[part 2 of 3: package /ComponentTypes]
AUTOSAR XML (schema 4-2-2)
package /ComponentTypes  (continued)
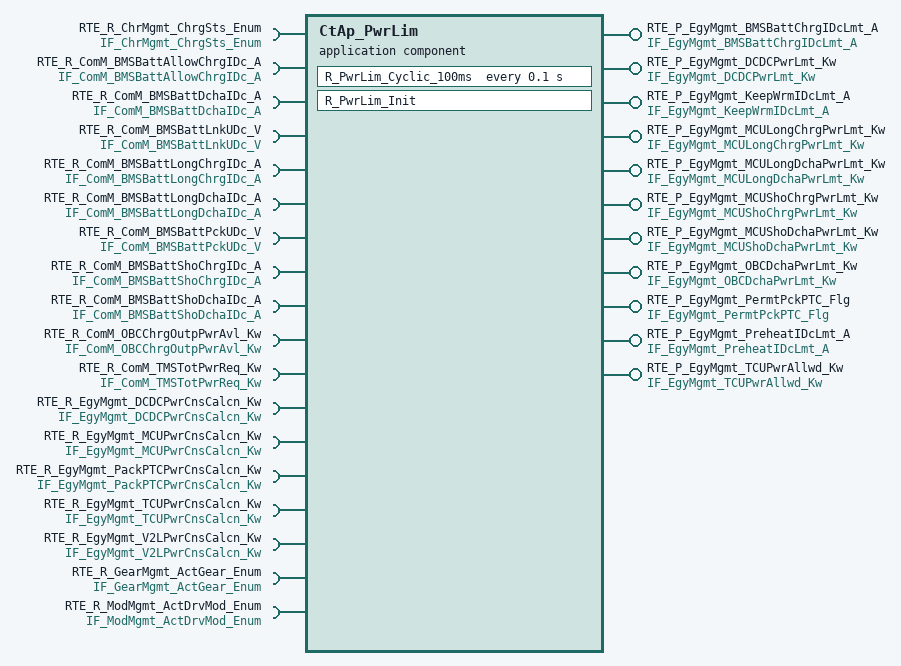
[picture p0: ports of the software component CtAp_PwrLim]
  application sw component type CtAp_PwrLim
    11 x provide port:
      RTE_P_EgyMgmt_BMSBattChrgIDcLmt_A: nonqueued-sender-com-spec{data-element=tec_EgyMgmt_BMSBattChrgIDcLmt_A, init-value=0}, provided-interface=IF_EgyMgmt_BMSBattChrgIDcLmt_A
      RTE_P_EgyMgmt_DCDCPwrLmt_Kw: nonqueued-sender-com-spec{data-element=tec_EgyMgmt_DCDCPwrLmt_Kw, init-value=0}, provided-interface=IF_EgyMgmt_DCDCPwrLmt_Kw
      RTE_P_EgyMgmt_KeepWrmIDcLmt_A: nonqueued-sender-com-spec{data-element=tec_EgyMgmt_KeepWrmIDcLmt_A, init-value=0}, provided-interface=IF_EgyMgmt_KeepWrmIDcLmt_A
      RTE_P_EgyMgmt_MCULongChrgPwrLmt_Kw: nonqueued-sender-com-spec{data-element=tec_EgyMgmt_MCULongChrgPwrLmt_Kw, init-value=0}, provided-interface=IF_EgyMgmt_MCULongChrgPwrLmt_Kw
      RTE_P_EgyMgmt_MCULongDchaPwrLmt_Kw: nonqueued-sender-com-spec{data-element=tec_EgyMgmt_MCULongDchaPwrLmt_Kw, init-value=0}, provided-interface=IF_EgyMgmt_MCULongDchaPwrLmt_Kw
      RTE_P_EgyMgmt_MCUShoChrgPwrLmt_Kw: nonqueued-sender-com-spec{data-element=tec_EgyMgmt_MCUShoChrgPwrLmt_Kw, init-value=0}, provided-interface=IF_EgyMgmt_MCUShoChrgPwrLmt_Kw
      RTE_P_EgyMgmt_MCUShoDchaPwrLmt_Kw: nonqueued-sender-com-spec{data-element=tec_EgyMgmt_MCUShoDchaPwrLmt_Kw, init-value=0}, provided-interface=IF_EgyMgmt_MCUShoDchaPwrLmt_Kw
      RTE_P_EgyMgmt_OBCDchaPwrLmt_Kw: nonqueued-sender-com-spec{data-element=tec_EgyMgmt_OBCDchaPwrLmt_Kw, init-value=0}, provided-interface=IF_EgyMgmt_OBCDchaPwrLmt_Kw
      RTE_P_EgyMgmt_PermtPckPTC_Flg: nonqueued-sender-com-spec{data-element=tec_EgyMgmt_PermtPckPTC_Flg, init-value=0}, provided-interface=IF_EgyMgmt_PermtPckPTC_Flg
      RTE_P_EgyMgmt_PreheatIDcLmt_A: nonqueued-sender-com-spec{data-element=tec_EgyMgmt_PreheatIDcLmt_A, init-value=0}, provided-interface=IF_EgyMgmt_PreheatIDcLmt_A
      RTE_P_EgyMgmt_TCUPwrAllwd_Kw: nonqueued-sender-com-spec{data-element=tec_EgyMgmt_TCUPwrAllwd_Kw, init-value=0}, provided-interface=IF_EgyMgmt_TCUPwrAllwd_Kw
    18 x require port:
      RTE_R_ChrMgmt_ChrgSts_Enum: nonqueued-receiver-com-spec{data-element=tec_ChrMgmt_ChrgSts_Enum, filter=data-filter-type=ALWAYS, init-value=0}, required-interface=IF_ChrMgmt_ChrgSts_Enum
      RTE_R_ComM_BMSBattAllowChrgIDc_A: nonqueued-receiver-com-spec{data-element=tec_ComM_BMSBattAllowChrgIDc_A, filter=data-filter-type=ALWAYS, init-value=0}, required-interface=IF_ComM_BMSBattAllowChrgIDc_A
      RTE_R_ComM_BMSBattDchaIDc_A: nonqueued-receiver-com-spec{data-element=tec_ComM_BMSBattDchaIDc_A, filter=data-filter-type=ALWAYS, init-value=0}, required-interface=IF_ComM_BMSBattDchaIDc_A
      RTE_R_ComM_BMSBattLnkUDc_V: nonqueued-receiver-com-spec{data-element=tec_ComM_BMSBattLnkUDc_V, filter=data-filter-type=ALWAYS, init-value=0}, required-interface=IF_ComM_BMSBattLnkUDc_V
      RTE_R_ComM_BMSBattLongChrgIDc_A: nonqueued-receiver-com-spec{data-element=tec_ComM_BMSBattLongChrgIDc_A, filter=data-filter-type=ALWAYS, init-value=0}, required-interface=IF_ComM_BMSBattLongChrgIDc_A
      RTE_R_ComM_BMSBattLongDchaIDc_A: nonqueued-receiver-com-spec{data-element=tec_ComM_BMSBattLongDchaIDc_A, filter=data-filter-type=ALWAYS, init-value=0}, required-interface=IF_ComM_BMSBattLongDchaIDc_A
      RTE_R_ComM_BMSBattPckUDc_V: nonqueued-receiver-com-spec{data-element=tec_ComM_BMSBattPckUDc_V, filter=data-filter-type=ALWAYS, init-value=0}, required-interface=IF_ComM_BMSBattPckUDc_V
      RTE_R_ComM_BMSBattShoChrgIDc_A: nonqueued-receiver-com-spec{data-element=tec_ComM_BMSBattShoChrgIDc_A, filter=data-filter-type=ALWAYS, init-value=0}, required-interface=IF_ComM_BMSBattShoChrgIDc_A
      RTE_R_ComM_BMSBattShoDchaIDc_A: nonqueued-receiver-com-spec{data-element=tec_ComM_BMSBattShoDchaIDc_A, filter=data-filter-type=ALWAYS, init-value=0}, required-interface=IF_ComM_BMSBattShoDchaIDc_A
      RTE_R_ComM_OBCChrgOutpPwrAvl_Kw: nonqueued-receiver-com-spec{data-element=tec_ComM_OBCChrgOutpPwrAvl_Kw, filter=data-filter-type=ALWAYS, init-value=0}, required-interface=IF_ComM_OBCChrgOutpPwrAvl_Kw
      RTE_R_ComM_TMSTotPwrReq_Kw: nonqueued-receiver-com-spec{data-element=tec_ComM_TMSTotPwrReq_Kw, filter=data-filter-type=ALWAYS, init-value=0}, required-interface=IF_ComM_TMSTotPwrReq_Kw
      RTE_R_EgyMgmt_DCDCPwrCnsCalcn_Kw: nonqueued-receiver-com-spec{data-element=tec_EgyMgmt_DCDCPwrCnsCalcn_Kw, filter=data-filter-type=ALWAYS, init-value=0}, required-interface=IF_EgyMgmt_DCDCPwrCnsCalcn_Kw
      RTE_R_EgyMgmt_MCUPwrCnsCalcn_Kw: nonqueued-receiver-com-spec{data-element=tec_EgyMgmt_MCUPwrCnsCalcn_Kw, filter=data-filter-type=ALWAYS, init-value=0}, required-interface=IF_EgyMgmt_MCUPwrCnsCalcn_Kw
      RTE_R_EgyMgmt_PackPTCPwrCnsCalcn_Kw: nonqueued-receiver-com-spec{data-element=tec_EgyMgmt_PackPTCPwrCnsCalcn_Kw, filter=data-filter-type=ALWAYS, init-value=0}, required-interface=IF_EgyMgmt_PackPTCPwrCnsCalcn_Kw
      RTE_R_EgyMgmt_TCUPwrCnsCalcn_Kw: nonqueued-receiver-com-spec{data-element=tec_EgyMgmt_TCUPwrCnsCalcn_Kw, filter=data-filter-type=ALWAYS, init-value=0}, required-interface=IF_EgyMgmt_TCUPwrCnsCalcn_Kw
      RTE_R_EgyMgmt_V2LPwrCnsCalcn_Kw: nonqueued-receiver-com-spec{data-element=IF_EgyMgmt_V2LPwrCnsCalcn_Kw, filter=data-filter-type=ALWAYS, init-value=0}, required-interface=IF_EgyMgmt_V2LPwrCnsCalcn_Kw
      RTE_R_GearMgmt_ActGear_Enum: nonqueued-receiver-com-spec{data-element=tec_GearMgmt_ActGear_Enum, filter=data-filter-type=ALWAYS, init-value=0}, required-interface=IF_GearMgmt_ActGear_Enum
      RTE_R_ModMgmt_ActDrvMod_Enum: nonqueued-receiver-com-spec{data-element=tec_ModMgmt_ActDrvMod_Enum, filter=data-filter-type=ALWAYS, init-value=0}, required-interface=IF_ModMgmt_ActDrvMod_Enum
    behavior CtAp_PwrLim_InternalBehavior
      timing event TMT_R_PwrLim_Cyclic_100ms: start-on-event=R_PwrLim_Cyclic_100ms, period=0.1
      init event CtAp_PwrLim_InitEvent: start-on-event=CtAp_PwrLim_InternalBehavior/R_PwrLim_Init
      runnable R_PwrLim_Cyclic_100ms
        data-receive-point-by-arguments:
          18 x access:
            REC_RTE_R_ChrMgmt_ChrgSts_Enum_tec_ChrMgmt_ChrgSts_Enum: accessed-variable=RTE_R_ChrMgmt_ChrgSts_Enum.tec_ChrMgmt_ChrgSts_Enum
            REC_RTE_R_ComM_BMSBattAllowChrgIDc_A_tec_ComM_BMSBattAllowChrgIDc_A: accessed-variable=RTE_R_ComM_BMSBattAllowChrgIDc_A.tec_ComM_BMSBattAllowChrgIDc_A
            REC_RTE_R_ComM_BMSBattDchaIDc_A_tec_ComM_BMSBattDchaIDc_A: accessed-variable=RTE_R_ComM_BMSBattDchaIDc_A.tec_ComM_BMSBattDchaIDc_A
            REC_RTE_R_ComM_BMSBattLnkUDc_V_tec_ComM_BMSBattLnkUDc_V: accessed-variable=RTE_R_ComM_BMSBattLnkUDc_V.tec_ComM_BMSBattLnkUDc_V
            REC_RTE_R_ComM_BMSBattLongChrgIDc_A_tec_ComM_BMSBattLongChrgIDc_A: accessed-variable=RTE_R_ComM_BMSBattLongChrgIDc_A.tec_ComM_BMSBattLongChrgIDc_A
            REC_RTE_R_ComM_BMSBattLongDchaIDc_A_tec_ComM_BMSBattLongDchaIDc_A: accessed-variable=RTE_R_ComM_BMSBattLongDchaIDc_A.tec_ComM_BMSBattLongDchaIDc_A
            REC_RTE_R_ComM_BMSBattPckUDc_V_tec_ComM_BMSBattPckUDc_V: accessed-variable=RTE_R_ComM_BMSBattPckUDc_V.tec_ComM_BMSBattPckUDc_V
            REC_RTE_R_ComM_BMSBattShoChrgIDc_A_tec_ComM_BMSBattShoChrgIDc_A: accessed-variable=RTE_R_ComM_BMSBattShoChrgIDc_A.tec_ComM_BMSBattShoChrgIDc_A
            REC_RTE_R_ComM_BMSBattShoDchaIDc_A_tec_ComM_BMSBattShoDchaIDc_A: accessed-variable=RTE_R_ComM_BMSBattShoDchaIDc_A.tec_ComM_BMSBattShoDchaIDc_A
            REC_RTE_R_ComM_OBCChrgOutpPwrAvl_Kw_tec_ComM_OBCChrgOutpPwrAvl_Kw: accessed-variable=RTE_R_ComM_OBCChrgOutpPwrAvl_Kw.tec_ComM_OBCChrgOutpPwrAvl_Kw
            REC_RTE_R_ComM_TMSTotPwrReq_Kw_tec_ComM_TMSTotPwrReq_Kw: accessed-variable=RTE_R_ComM_TMSTotPwrReq_Kw.tec_ComM_TMSTotPwrReq_Kw
            REC_RTE_R_EgyMgmt_DCDCPwrCnsCalcn_Kw_tec_EgyMgmt_DCDCPwrCnsCalcn_Kw: accessed-variable=RTE_R_EgyMgmt_DCDCPwrCnsCalcn_Kw.tec_EgyMgmt_DCDCPwrCnsCalcn_Kw
            REC_RTE_R_EgyMgmt_MCUPwrCnsCalcn_Kw_tec_EgyMgmt_MCUPwrCnsCalcn_Kw: accessed-variable=RTE_R_EgyMgmt_MCUPwrCnsCalcn_Kw.tec_EgyMgmt_MCUPwrCnsCalcn_Kw
            REC_RTE_R_EgyMgmt_PackPTCPwrCnsCalcn_Kw_tec_EgyMgmt_PackPTCPwrCnsCalcn_Kw: accessed-variable=RTE_R_EgyMgmt_PackPTCPwrCnsCalcn_Kw.tec_EgyMgmt_PackPTCPwrCnsCalcn_Kw
            REC_RTE_R_EgyMgmt_TCUPwrCnsCalcn_Kw_tec_EgyMgmt_TCUPwrCnsCalcn_Kw: accessed-variable=RTE_R_EgyMgmt_TCUPwrCnsCalcn_Kw.tec_EgyMgmt_TCUPwrCnsCalcn_Kw
            REC_RTE_R_EgyMgmt_V2LPwrCnsCalcn_Kw_IF_EgyMgmt_V2LPwrCnsCalcn_Kw: accessed-variable=RTE_R_EgyMgmt_V2LPwrCnsCalcn_Kw.IF_EgyMgmt_V2LPwrCnsCalcn_Kw
            REC_RTE_R_GearMgmt_ActGear_Enum_tec_GearMgmt_ActGear_Enum: accessed-variable=RTE_R_GearMgmt_ActGear_Enum.tec_GearMgmt_ActGear_Enum
            REC_RTE_R_ModMgmt_ActDrvMod_Enum_tec_ModMgmt_ActDrvMod_Enum: accessed-variable=RTE_R_ModMgmt_ActDrvMod_Enum.tec_ModMgmt_ActDrvMod_Enum
        data-send-points:
          11 x access:
            SEND_RTE_P_EgyMgmt_BMSBattChrgIDcLmt_A_tec_EgyMgmt_BMSBattChrgIDcLmt_A: accessed-variable=RTE_P_EgyMgmt_BMSBattChrgIDcLmt_A.tec_EgyMgmt_BMSBattChrgIDcLmt_A
            SEND_RTE_P_EgyMgmt_DCDCPwrLmt_Kw_tec_EgyMgmt_DCDCPwrLmt_Kw: accessed-variable=RTE_P_EgyMgmt_DCDCPwrLmt_Kw.tec_EgyMgmt_DCDCPwrLmt_Kw
            SEND_RTE_P_EgyMgmt_KeepWrmIDcLmt_A_tec_EgyMgmt_KeepWrmIDcLmt_A: accessed-variable=RTE_P_EgyMgmt_KeepWrmIDcLmt_A.tec_EgyMgmt_KeepWrmIDcLmt_A
            SEND_RTE_P_EgyMgmt_MCULongChrgPwrLmt_Kw_tec_EgyMgmt_MCULongChrgPwrLmt_Kw: accessed-variable=RTE_P_EgyMgmt_MCULongChrgPwrLmt_Kw.tec_EgyMgmt_MCULongChrgPwrLmt_Kw
            SEND_RTE_P_EgyMgmt_MCULongDchaPwrLmt_Kw_tec_EgyMgmt_MCULongDchaPwrLmt_Kw: accessed-variable=RTE_P_EgyMgmt_MCULongDchaPwrLmt_Kw.tec_EgyMgmt_MCULongDchaPwrLmt_Kw
            SEND_RTE_P_EgyMgmt_MCUShoChrgPwrLmt_Kw_tec_EgyMgmt_MCUShoChrgPwrLmt_Kw: accessed-variable=RTE_P_EgyMgmt_MCUShoChrgPwrLmt_Kw.tec_EgyMgmt_MCUShoChrgPwrLmt_Kw
            SEND_RTE_P_EgyMgmt_MCUShoDchaPwrLmt_Kw_tec_EgyMgmt_MCUShoDchaPwrLmt_Kw: accessed-variable=RTE_P_EgyMgmt_MCUShoDchaPwrLmt_Kw.tec_EgyMgmt_MCUShoDchaPwrLmt_Kw
            SEND_RTE_P_EgyMgmt_OBCDchaPwrLmt_Kw_tec_EgyMgmt_OBCDchaPwrLmt_Kw: accessed-variable=RTE_P_EgyMgmt_OBCDchaPwrLmt_Kw.tec_EgyMgmt_OBCDchaPwrLmt_Kw
            SEND_RTE_P_EgyMgmt_PermtPckPTC_Flg_tec_EgyMgmt_PermtPckPTC_Flg: accessed-variable=RTE_P_EgyMgmt_PermtPckPTC_Flg.tec_EgyMgmt_PermtPckPTC_Flg
            SEND_RTE_P_EgyMgmt_PreheatIDcLmt_A_tec_EgyMgmt_PreheatIDcLmt_A: accessed-variable=RTE_P_EgyMgmt_PreheatIDcLmt_A.tec_EgyMgmt_PreheatIDcLmt_A
            SEND_RTE_P_EgyMgmt_TCUPwrAllwd_Kw_tec_EgyMgmt_TCUPwrAllwd_Kw: accessed-variable=RTE_P_EgyMgmt_TCUPwrAllwd_Kw.tec_EgyMgmt_TCUPwrAllwd_Kw
      runnable R_PwrLim_Init
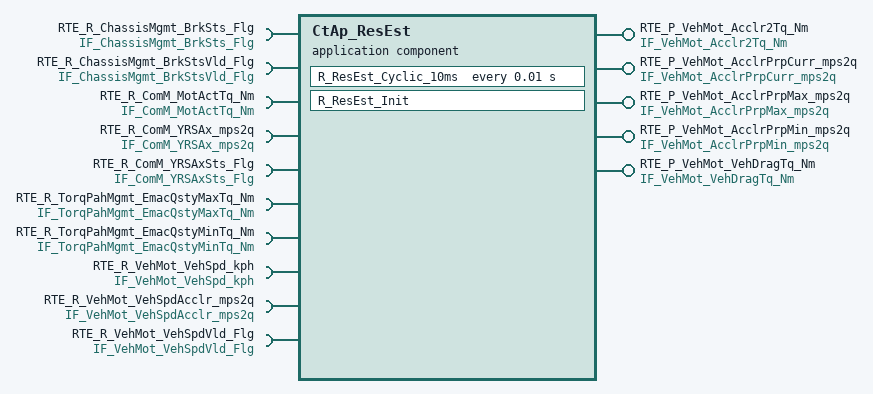
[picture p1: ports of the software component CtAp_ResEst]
  application sw component type CtAp_ResEst
    5 x provide port:
      RTE_P_VehMot_Acclr2Tq_Nm: nonqueued-sender-com-spec{data-element=tec_VehMot_Acclr2Tq_Nm, init-value=0}, provided-interface=IF_VehMot_Acclr2Tq_Nm
      RTE_P_VehMot_AcclrPrpCurr_mps2q: nonqueued-sender-com-spec{data-element=tec_VehMot_AcclrPrpCurr_mps2q, init-value=0}, provided-interface=IF_VehMot_AcclrPrpCurr_mps2q
      RTE_P_VehMot_AcclrPrpMax_mps2q: nonqueued-sender-com-spec{data-element=tec_VehMot_AcclrPrpMax_mps2q, init-value=0}, provided-interface=IF_VehMot_AcclrPrpMax_mps2q
      RTE_P_VehMot_AcclrPrpMin_mps2q: nonqueued-sender-com-spec{data-element=tec_VehMot_AcclrPrpMin_mps2q, init-value=0}, provided-interface=IF_VehMot_AcclrPrpMin_mps2q
      RTE_P_VehMot_VehDragTq_Nm: nonqueued-sender-com-spec{data-element=tec_VehMot_VehDragTq_Nm, init-value=0}, provided-interface=IF_VehMot_VehDragTq_Nm
    10 x require port:
      RTE_R_ChassisMgmt_BrkSts_Flg: nonqueued-receiver-com-spec{data-element=tec_ChassisMgmt_BrkSts_Flg, filter=data-filter-type=ALWAYS, init-value=0}, required-interface=IF_ChassisMgmt_BrkSts_Flg
      RTE_R_ChassisMgmt_BrkStsVld_Flg: nonqueued-receiver-com-spec{data-element=tec_ChassisMgmt_BrkStsVld_Flg, filter=data-filter-type=ALWAYS, init-value=0}, required-interface=IF_ChassisMgmt_BrkStsVld_Flg
      RTE_R_ComM_MotActTq_Nm: nonqueued-receiver-com-spec{data-element=tec_ComM_MotActTq_Nm, filter=data-filter-type=ALWAYS, init-value=0}, required-interface=IF_ComM_MotActTq_Nm
      RTE_R_ComM_YRSAx_mps2q: nonqueued-receiver-com-spec{data-element=tec_ComM_YRSAx_mps2q, filter=data-filter-type=ALWAYS, init-value=0}, required-interface=IF_ComM_YRSAx_mps2q
      RTE_R_ComM_YRSAxSts_Flg: nonqueued-receiver-com-spec{data-element=tec_ComM_YRSAxSts_Flg, filter=data-filter-type=ALWAYS, init-value=0}, required-interface=IF_ComM_YRSAxSts_Flg
      RTE_R_TorqPahMgmt_EmacQstyMaxTq_Nm: nonqueued-receiver-com-spec{data-element=tec_TorqPahMgmt_EmacQstyMaxTq_Nm, filter=data-filter-type=ALWAYS, init-value=0}, required-interface=IF_TorqPahMgmt_EmacQstyMaxTq_Nm
      RTE_R_TorqPahMgmt_EmacQstyMinTq_Nm: nonqueued-receiver-com-spec{data-element=tec_TorqPahMgmt_EmacQstyMinTq_Nm, filter=data-filter-type=ALWAYS, init-value=0}, required-interface=IF_TorqPahMgmt_EmacQstyMinTq_Nm
      RTE_R_VehMot_VehSpd_kph: nonqueued-receiver-com-spec{data-element=tec_VehMot_VehSpd_kph, filter=data-filter-type=ALWAYS, init-value=0}, required-interface=IF_VehMot_VehSpd_kph
      RTE_R_VehMot_VehSpdAcclr_mps2q: nonqueued-receiver-com-spec{data-element=tec_VehMot_VehSpdAcclr_mps2q, filter=data-filter-type=ALWAYS, init-value=0}, required-interface=IF_VehMot_VehSpdAcclr_mps2q
      RTE_R_VehMot_VehSpdVld_Flg: nonqueued-receiver-com-spec{data-element=tec_VehMot_VehSpdVld_Flg, filter=data-filter-type=ALWAYS, init-value=0}, required-interface=IF_VehMot_VehSpdVld_Flg
    behavior CtAp_ResEst_InternalBehavior
      timing event TMT_R_ResEst_Cyclic_10ms: start-on-event=R_ResEst_Cyclic_10ms, period=0.01
      init event CtAp_ResEst_InitEvent: start-on-event=R_ResEst_Init
      runnable R_ResEst_Cyclic_10ms
        data-receive-point-by-arguments:
          10 x access:
            REC_RTE_R_ChassisMgmt_BrkSts_Flg_tec_ChassisMgmt_BrkSts_Flg: accessed-variable=RTE_R_ChassisMgmt_BrkSts_Flg.tec_ChassisMgmt_BrkSts_Flg
            REC_RTE_R_ChassisMgmt_BrkStsVld_Flg_tec_ChassisMgmt_BrkStsVld_Flg: accessed-variable=RTE_R_ChassisMgmt_BrkStsVld_Flg.tec_ChassisMgmt_BrkStsVld_Flg
            REC_RTE_R_ComM_MotActTq_Nm_tec_ComM_MotActTq_Nm: accessed-variable=RTE_R_ComM_MotActTq_Nm.tec_ComM_MotActTq_Nm
            REC_RTE_R_ComM_YRSAx_mps2q_tec_ComM_YRSAx_mps2q: accessed-variable=RTE_R_ComM_YRSAx_mps2q.tec_ComM_YRSAx_mps2q
            REC_RTE_R_ComM_YRSAxSts_Flg_tec_ComM_YRSAxSts_Flg: accessed-variable=RTE_R_ComM_YRSAxSts_Flg.tec_ComM_YRSAxSts_Flg
            REC_RTE_R_TorqPahMgmt_EmacQstyMaxTq_Nm_tec_TorqPahMgmt_EmacQstyMaxTq_Nm: accessed-variable=RTE_R_TorqPahMgmt_EmacQstyMaxTq_Nm.tec_TorqPahMgmt_EmacQstyMaxTq_Nm
            REC_RTE_R_TorqPahMgmt_EmacQstyMinTq_Nm_tec_TorqPahMgmt_EmacQstyMinTq_Nm: accessed-variable=RTE_R_TorqPahMgmt_EmacQstyMinTq_Nm.tec_TorqPahMgmt_EmacQstyMinTq_Nm
            REC_RTE_R_VehMot_VehSpd_kph_tec_VehMot_VehSpd_kph: accessed-variable=RTE_R_VehMot_VehSpd_kph.tec_VehMot_VehSpd_kph
            REC_RTE_R_VehMot_VehSpdAcclr_mps2q_tec_VehMot_VehSpdAcclr_mps2q: accessed-variable=RTE_R_VehMot_VehSpdAcclr_mps2q.tec_VehMot_VehSpdAcclr_mps2q
            REC_RTE_R_VehMot_VehSpdVld_Flg_tec_VehMot_VehSpdVld_Flg: accessed-variable=RTE_R_VehMot_VehSpdVld_Flg.tec_VehMot_VehSpdVld_Flg
        data-send-points:
          5 x access:
            SEND_RTE_P_VehMot_Acclr2Tq_Nm_tec_VehMot_Acclr2Tq_Nm: accessed-variable=RTE_P_VehMot_Acclr2Tq_Nm.tec_VehMot_Acclr2Tq_Nm
            SEND_RTE_P_VehMot_AcclrPrpCurr_mps2q_tec_VehMot_AcclrPrpCurr_mps2q: accessed-variable=RTE_P_VehMot_AcclrPrpCurr_mps2q.tec_VehMot_AcclrPrpCurr_mps2q
            SEND_RTE_P_VehMot_AcclrPrpMax_mps2q_tec_VehMot_AcclrPrpMax_mps2q: accessed-variable=RTE_P_VehMot_AcclrPrpMax_mps2q.tec_VehMot_AcclrPrpMax_mps2q
            SEND_RTE_P_VehMot_AcclrPrpMin_mps2q_tec_VehMot_AcclrPrpMin_mps2q: accessed-variable=RTE_P_VehMot_AcclrPrpMin_mps2q.tec_VehMot_AcclrPrpMin_mps2q
            SEND_RTE_P_VehMot_VehDragTq_Nm_tec_VehMot_VehDragTq_Nm: accessed-variable=RTE_P_VehMot_VehDragTq_Nm.tec_VehMot_VehDragTq_Nm
      runnable R_ResEst_Init
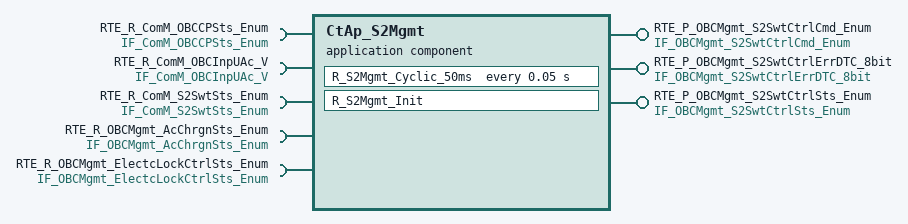
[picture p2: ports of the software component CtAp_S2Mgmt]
  application sw component type CtAp_S2Mgmt
    provide port RTE_P_OBCMgmt_S2SwtCtrlCmd_Enum: nonqueued-sender-com-spec{data-element=tec_OBCMgmt_S2SwtCtrlCmd_Enum, init-value=0}, provided-interface=IF_OBCMgmt_S2SwtCtrlCmd_Enum
    provide port RTE_P_OBCMgmt_S2SwtCtrlErrDTC_8bit: nonqueued-sender-com-spec{data-element=tec_OBCMgmt_S2SwtCtrlErrDTC_8bit, init-value=0}, provided-interface=IF_OBCMgmt_S2SwtCtrlErrDTC_8bit
    provide port RTE_P_OBCMgmt_S2SwtCtrlSts_Enum: nonqueued-sender-com-spec{data-element=tec_OBCMgmt_S2SwtCtrlSts_Enum, init-value=0}, provided-interface=IF_OBCMgmt_S2SwtCtrlSts_Enum
    5 x require port:
      RTE_R_ComM_OBCCPSts_Enum: nonqueued-receiver-com-spec{data-element=tec_ComM_OBCCPSts_Enum, filter=data-filter-type=ALWAYS, init-value=0}, required-interface=IF_ComM_OBCCPSts_Enum
      RTE_R_ComM_OBCInpUAc_V: nonqueued-receiver-com-spec{data-element=tec_ComM_OBCInpUAc_V, filter=data-filter-type=ALWAYS, init-value=0}, required-interface=IF_ComM_OBCInpUAc_V
      RTE_R_ComM_S2SwtSts_Enum: nonqueued-receiver-com-spec{data-element=tec_ComM_S2SwtSts_Enum, filter=data-filter-type=ALWAYS, init-value=0}, required-interface=IF_ComM_S2SwtSts_Enum
      RTE_R_OBCMgmt_AcChrgnSts_Enum: nonqueued-receiver-com-spec{data-element=tec_OBCMgmt_AcChrgnSts_Enum, filter=data-filter-type=ALWAYS, init-value=0}, required-interface=IF_OBCMgmt_AcChrgnSts_Enum
      RTE_R_OBCMgmt_ElectcLockCtrlSts_Enum: nonqueued-receiver-com-spec{data-element=tec_OBCMgmt_ElectcLockCtrlSts_Enum, filter=data-filter-type=ALWAYS, init-value=0}, required-interface=IF_OBCMgmt_ElectcLockCtrlSts_Enum
    behavior CtAp_S2Mgmt_InternalBehavior
      timing event TMT_R_S2Mgmt_Cyclic_50ms: start-on-event=R_S2Mgmt_Cyclic_50ms, period=0.05
      init event CtAp_S2Mgmt_InitEvent: start-on-event=R_S2Mgmt_Init
      runnable R_S2Mgmt_Cyclic_50ms
        data-receive-point-by-arguments:
          5 x access:
            REC_RTE_R_ComM_OBCCPSts_Enum_tec_ComM_OBCCPSts_Enum: accessed-variable=RTE_R_ComM_OBCCPSts_Enum.tec_ComM_OBCCPSts_Enum
            REC_RTE_R_ComM_OBCInpUAc_V_tec_ComM_OBCInpUAc_V: accessed-variable=RTE_R_ComM_OBCInpUAc_V.tec_ComM_OBCInpUAc_V
            REC_RTE_R_ComM_S2SwtSts_Enum_tec_ComM_S2SwtSts_Enum: accessed-variable=RTE_R_ComM_S2SwtSts_Enum.tec_ComM_S2SwtSts_Enum
            REC_RTE_R_OBCMgmt_AcChrgnSts_Enum_tec_OBCMgmt_AcChrgnSts_Enum: accessed-variable=RTE_R_OBCMgmt_AcChrgnSts_Enum.tec_OBCMgmt_AcChrgnSts_Enum
            REC_RTE_R_OBCMgmt_ElectcLockCtrlSts_Enum_tec_OBCMgmt_ElectcLockCtrlSts_Enum: accessed-variable=RTE_R_OBCMgmt_ElectcLockCtrlSts_Enum.tec_OBCMgmt_ElectcLockCtrlSts_Enum
        data-send-points:
          access SEND_RTE_P_OBCMgmt_S2SwtCtrlCmd_Enum_tec_OBCMgmt_S2SwtCtrlCmd_Enum: accessed-variable=RTE_P_OBCMgmt_S2SwtCtrlCmd_Enum.tec_OBCMgmt_S2SwtCtrlCmd_Enum
          access SEND_RTE_P_OBCMgmt_S2SwtCtrlErrDTC_8bit_tec_OBCMgmt_S2SwtCtrlErrDTC_8bit: accessed-variable=RTE_P_OBCMgmt_S2SwtCtrlErrDTC_8bit.tec_OBCMgmt_S2SwtCtrlErrDTC_8bit
          access SEND_RTE_P_OBCMgmt_S2SwtCtrlSts_Enum_tec_OBCMgmt_S2SwtCtrlSts_Enum: accessed-variable=RTE_P_OBCMgmt_S2SwtCtrlSts_Enum.tec_OBCMgmt_S2SwtCtrlSts_Enum
      runnable R_S2Mgmt_Init
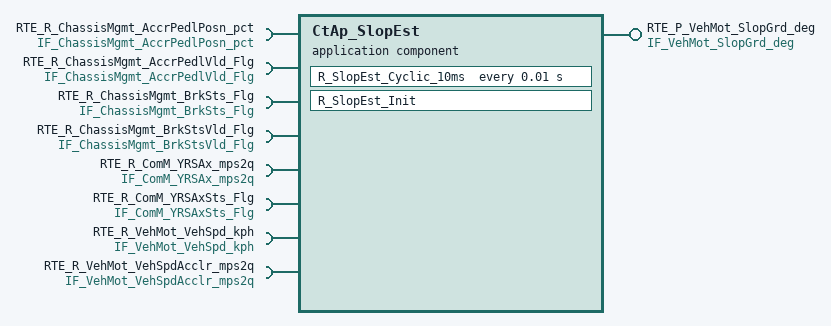
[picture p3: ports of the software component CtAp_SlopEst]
  application sw component type CtAp_SlopEst
    provide port RTE_P_VehMot_SlopGrd_deg: nonqueued-sender-com-spec{data-element=tec_VehMot_SlopGrd_deg, init-value=0}, provided-interface=IF_VehMot_SlopGrd_deg
    8 x require port:
      RTE_R_ChassisMgmt_AccrPedlPosn_pct: nonqueued-receiver-com-spec{data-element=tec_ChassisMgmt_AccrPedlPosn_pct, filter=data-filter-type=ALWAYS, init-value=0}, required-interface=IF_ChassisMgmt_AccrPedlPosn_pct
      RTE_R_ChassisMgmt_AccrPedlVld_Flg: nonqueued-receiver-com-spec{data-element=tec_ChassisMgmt_AccrPedlVld_Flg, filter=data-filter-type=ALWAYS, init-value=0}, required-interface=IF_ChassisMgmt_AccrPedlVld_Flg
      RTE_R_ChassisMgmt_BrkSts_Flg: nonqueued-receiver-com-spec{data-element=tec_ChassisMgmt_BrkSts_Flg, filter=data-filter-type=ALWAYS, init-value=0}, required-interface=IF_ChassisMgmt_BrkSts_Flg
      RTE_R_ChassisMgmt_BrkStsVld_Flg: nonqueued-receiver-com-spec{data-element=tec_ChassisMgmt_BrkStsVld_Flg, filter=data-filter-type=ALWAYS, init-value=0}, required-interface=IF_ChassisMgmt_BrkStsVld_Flg
      RTE_R_ComM_YRSAx_mps2q: nonqueued-receiver-com-spec{data-element=tec_ComM_YRSAx_mps2q, filter=data-filter-type=ALWAYS, init-value=0}, required-interface=IF_ComM_YRSAx_mps2q
      RTE_R_ComM_YRSAxSts_Flg: nonqueued-receiver-com-spec{data-element=tec_ComM_YRSAxSts_Flg, filter=data-filter-type=ALWAYS, init-value=0}, required-interface=IF_ComM_YRSAxSts_Flg
      RTE_R_VehMot_VehSpd_kph: nonqueued-receiver-com-spec{data-element=tec_VehMot_VehSpd_kph, filter=data-filter-type=ALWAYS, init-value=0}, required-interface=IF_VehMot_VehSpd_kph
      RTE_R_VehMot_VehSpdAcclr_mps2q: nonqueued-receiver-com-spec{data-element=tec_VehMot_VehSpdAcclr_mps2q, filter=data-filter-type=ALWAYS, init-value=0}, required-interface=IF_VehMot_VehSpdAcclr_mps2q
    behavior CtAp_SlopEst_InternalBehavior
      timing event TMT_R_SlopEst_Cyclic_10ms: start-on-event=R_SlopEst_Cyclic_10ms, period=0.01
      init event CtAp_SlopEst_InitEvent: start-on-event=R_SlopEst_Init
      runnable R_SlopEst_Cyclic_10ms
        data-receive-point-by-arguments:
          8 x access:
            REC_RTE_R_ChassisMgmt_AccrPedlPosn_pct_tec_ChassisMgmt_AccrPedlPosn_pct: accessed-variable=RTE_R_ChassisMgmt_AccrPedlPosn_pct.tec_ChassisMgmt_AccrPedlPosn_pct
            REC_RTE_R_ChassisMgmt_AccrPedlVld_Flg_tec_ChassisMgmt_AccrPedlVld_Flg: accessed-variable=RTE_R_ChassisMgmt_AccrPedlVld_Flg.tec_ChassisMgmt_AccrPedlVld_Flg
            REC_RTE_R_ChassisMgmt_BrkSts_Flg_tec_ChassisMgmt_BrkSts_Flg: accessed-variable=RTE_R_ChassisMgmt_BrkSts_Flg.tec_ChassisMgmt_BrkSts_Flg
            REC_RTE_R_ChassisMgmt_BrkStsVld_Flg_tec_ChassisMgmt_BrkStsVld_Flg: accessed-variable=RTE_R_ChassisMgmt_BrkStsVld_Flg.tec_ChassisMgmt_BrkStsVld_Flg
            REC_RTE_R_ComM_YRSAx_mps2q_tec_ComM_YRSAx_mps2q: accessed-variable=RTE_R_ComM_YRSAx_mps2q.tec_ComM_YRSAx_mps2q
            REC_RTE_R_ComM_YRSAxSts_Flg_tec_ComM_YRSAxSts_Flg: accessed-variable=RTE_R_ComM_YRSAxSts_Flg.tec_ComM_YRSAxSts_Flg
            REC_RTE_R_VehMot_VehSpd_kph_tec_VehMot_VehSpd_kph: accessed-variable=RTE_R_VehMot_VehSpd_kph.tec_VehMot_VehSpd_kph
            REC_RTE_R_VehMot_VehSpdAcclr_mps2q_tec_VehMot_VehSpdAcclr_mps2q: accessed-variable=RTE_R_VehMot_VehSpdAcclr_mps2q.tec_VehMot_VehSpdAcclr_mps2q
        data-send-points:
          access SEND_RTE_P_VehMot_SlopGrd_deg_tec_VehMot_SlopGrd_deg: accessed-variable=RTE_P_VehMot_SlopGrd_deg.tec_VehMot_SlopGrd_deg
      runnable R_SlopEst_Init
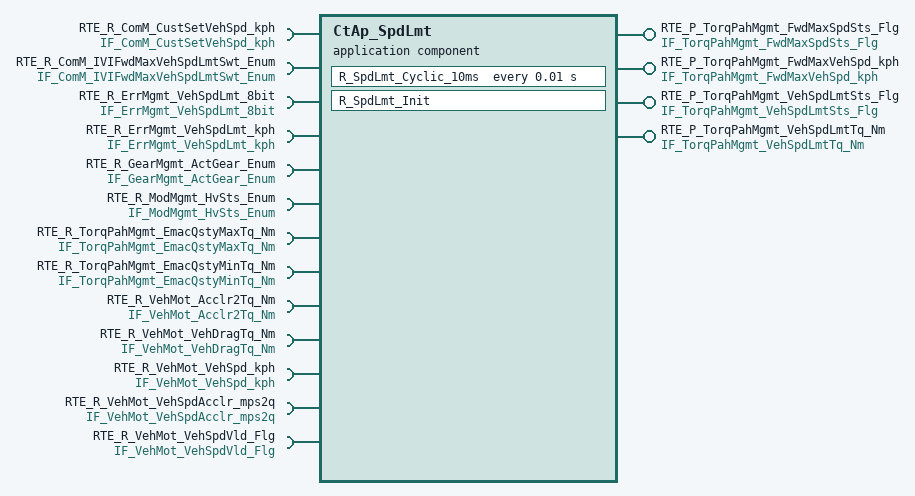
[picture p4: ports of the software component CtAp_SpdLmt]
  application sw component type CtAp_SpdLmt
    4 x provide port:
      RTE_P_TorqPahMgmt_FwdMaxSpdSts_Flg: nonqueued-sender-com-spec{data-element=tec_TorqPahMgmt_FwdMaxSpdSts_Flg, init-value=0}, provided-interface=IF_TorqPahMgmt_FwdMaxSpdSts_Flg
      RTE_P_TorqPahMgmt_FwdMaxVehSpd_kph: nonqueued-sender-com-spec{data-element=tec_TorqPahMgmt_FwdMaxVehSpd_kph, init-value=0}, provided-interface=IF_TorqPahMgmt_FwdMaxVehSpd_kph
      RTE_P_TorqPahMgmt_VehSpdLmtSts_Flg: nonqueued-sender-com-spec{data-element=tec_TorqPahMgmt_VehSpdLmtSts_Flg, init-value=0}, provided-interface=IF_TorqPahMgmt_VehSpdLmtSts_Flg
      RTE_P_TorqPahMgmt_VehSpdLmtTq_Nm: nonqueued-sender-com-spec{data-element=tec_TorqPahMgmt_VehSpdLmtTq_Nm, init-value=0}, provided-interface=IF_TorqPahMgmt_VehSpdLmtTq_Nm
    13 x require port:
      RTE_R_ComM_CustSetVehSpd_kph: nonqueued-receiver-com-spec{data-element=tec_ComM_IVISetFwdVehSpd_kph, filter=data-filter-type=ALWAYS, init-value=0}, required-interface=IF_ComM_CustSetVehSpd_kph
      RTE_R_ComM_IVIFwdMaxVehSpdLmtSwt_Enum: nonqueued-receiver-com-spec{data-element=tec_ComM_IVIFwdMaxVehSpdLmtSwt_Enum, filter=data-filter-type=ALWAYS, init-value=0}, required-interface=IF_ComM_IVIFwdMaxVehSpdLmtSwt_Enum
      RTE_R_ErrMgmt_VehSpdLmt_8bit: nonqueued-receiver-com-spec{data-element=tec_ErrMgmt_VehSpdLmt_8bit, filter=data-filter-type=ALWAYS, init-value=0}, required-interface=IF_ErrMgmt_VehSpdLmt_8bit
      RTE_R_ErrMgmt_VehSpdLmt_kph: nonqueued-receiver-com-spec{data-element=tec_ErrMgmt_VehSpdLmt_kph, filter=data-filter-type=ALWAYS, init-value=0}, required-interface=IF_ErrMgmt_VehSpdLmt_kph
      RTE_R_GearMgmt_ActGear_Enum: nonqueued-receiver-com-spec{data-element=tec_GearMgmt_ActGear_Enum, filter=data-filter-type=ALWAYS, init-value=0}, required-interface=IF_GearMgmt_ActGear_Enum
      RTE_R_ModMgmt_HvSts_Enum: nonqueued-receiver-com-spec{data-element=tec_ModMgmt_HvSts_Enum, filter=data-filter-type=ALWAYS, init-value=0}, required-interface=IF_ModMgmt_HvSts_Enum
      RTE_R_TorqPahMgmt_EmacQstyMaxTq_Nm: nonqueued-receiver-com-spec{data-element=tec_TorqPahMgmt_EmacQstyMaxTq_Nm, filter=data-filter-type=ALWAYS, init-value=0}, required-interface=IF_TorqPahMgmt_EmacQstyMaxTq_Nm
      RTE_R_TorqPahMgmt_EmacQstyMinTq_Nm: nonqueued-receiver-com-spec{data-element=tec_TorqPahMgmt_EmacQstyMinTq_Nm, filter=data-filter-type=ALWAYS, init-value=0}, required-interface=IF_TorqPahMgmt_EmacQstyMinTq_Nm
      RTE_R_VehMot_Acclr2Tq_Nm: nonqueued-receiver-com-spec{data-element=tec_VehMot_Acclr2Tq_Nm, filter=data-filter-type=ALWAYS, init-value=0}, required-interface=IF_VehMot_Acclr2Tq_Nm
      RTE_R_VehMot_VehDragTq_Nm: nonqueued-receiver-com-spec{data-element=tec_VehMot_VehDragTq_Nm, filter=data-filter-type=ALWAYS, init-value=0}, required-interface=IF_VehMot_VehDragTq_Nm
      RTE_R_VehMot_VehSpd_kph: nonqueued-receiver-com-spec{data-element=tec_VehMot_VehSpd_kph, filter=data-filter-type=ALWAYS, init-value=0}, required-interface=IF_VehMot_VehSpd_kph
      RTE_R_VehMot_VehSpdAcclr_mps2q: nonqueued-receiver-com-spec{data-element=tec_VehMot_VehSpdAcclr_mps2q, filter=data-filter-type=ALWAYS, init-value=0}, required-interface=IF_VehMot_VehSpdAcclr_mps2q
      RTE_R_VehMot_VehSpdVld_Flg: nonqueued-receiver-com-spec{data-element=tec_VehMot_VehSpdVld_Flg, filter=data-filter-type=ALWAYS, init-value=0}, required-interface=IF_VehMot_VehSpdVld_Flg
    behavior CtAp_SpdLmt_InternalBehavior
      timing event TMT_R_SpdLmt_Cyclic_10ms: start-on-event=R_SpdLmt_Cyclic_10ms, period=0.01
      init event CtAp_TorqLmt_InitEvent: start-on-event=R_SpdLmt_Init
      runnable R_SpdLmt_Cyclic_10ms
        data-receive-point-by-arguments:
          13 x access:
            REC_RTE_R_ComM_CustSetVehSpd_kph_tec_ComM_IVISetFwdVehSpd_kph: accessed-variable=RTE_R_ComM_CustSetVehSpd_kph.tec_ComM_IVISetFwdVehSpd_kph
            REC_RTE_R_ComM_IVIFwdMaxVehSpdLmtSwt_Enum_tec_ComM_IVIFwdMaxVehSpdLmtSwt_Enum: accessed-variable=RTE_R_ComM_IVIFwdMaxVehSpdLmtSwt_Enum.tec_ComM_IVIFwdMaxVehSpdLmtSwt_Enum
            REC_RTE_R_ErrMgmt_VehSpdLmt_8bit_tec_ErrMgmt_VehSpdLmt_8bit: accessed-variable=RTE_R_ErrMgmt_VehSpdLmt_8bit.tec_ErrMgmt_VehSpdLmt_8bit
            REC_RTE_R_ErrMgmt_VehSpdLmt_kph_tec_ErrMgmt_VehSpdLmt_kph: accessed-variable=RTE_R_ErrMgmt_VehSpdLmt_kph.tec_ErrMgmt_VehSpdLmt_kph
            REC_RTE_R_GearMgmt_ActGear_Enum_tec_GearMgmt_ActGear_Enum: accessed-variable=RTE_R_GearMgmt_ActGear_Enum.tec_GearMgmt_ActGear_Enum
            REC_RTE_R_ModMgmt_HvSts_Enum_tec_ModMgmt_HvSts_Enum: accessed-variable=RTE_R_ModMgmt_HvSts_Enum.tec_ModMgmt_HvSts_Enum
            REC_RTE_R_VehMot_Acclr2Tq_Nm_tec_VehMot_Acclr2Tq_Nm: accessed-variable=RTE_R_VehMot_Acclr2Tq_Nm.tec_VehMot_Acclr2Tq_Nm
            REC_RTE_R_VehMot_VehDragTq_Nm_tec_VehMot_VehDragTq_Nm: accessed-variable=RTE_R_VehMot_VehDragTq_Nm.tec_VehMot_VehDragTq_Nm
            REC_RTE_R_VehMot_VehSpd_kph_tec_VehMot_VehSpd_kph: accessed-variable=RTE_R_VehMot_VehSpd_kph.tec_VehMot_VehSpd_kph
            REC_RTE_R_VehMot_VehSpdAcclr_mps2q_tec_VehMot_VehSpdAcclr_mps2q: accessed-variable=RTE_R_VehMot_VehSpdAcclr_mps2q.tec_VehMot_VehSpdAcclr_mps2q
            REC_RTE_R_VehMot_VehSpdVld_Flg_tec_VehMot_VehSpdVld_Flg: accessed-variable=RTE_R_VehMot_VehSpdVld_Flg.tec_VehMot_VehSpdVld_Flg
            SEND_RTE_P_TorqPahMgmt_EmacQstyMaxTq_Nm_tec_TorqPahMgmt_EmacQstyMaxTq_Nm: accessed-variable=RTE_R_TorqPahMgmt_EmacQstyMaxTq_Nm.tec_TorqPahMgmt_EmacQstyMaxTq_Nm
            SEND_RTE_P_TorqPahMgmt_EmacQstyMinTq_Nm_tec_TorqPahMgmt_EmacQstyMinTq_Nm: accessed-variable=RTE_R_TorqPahMgmt_EmacQstyMinTq_Nm.tec_TorqPahMgmt_EmacQstyMinTq_Nm
        data-send-points:
          4 x access:
            SEND_RTE_P_TorqPahMgmt_FwdMaxSpdSts_Flg_tec_TorqPahMgmt_FwdMaxSpdSts_Flg: accessed-variable=RTE_P_TorqPahMgmt_FwdMaxSpdSts_Flg.tec_TorqPahMgmt_FwdMaxSpdSts_Flg
            SEND_RTE_P_TorqPahMgmt_FwdMaxVehSpd_kph_tec_TorqPahMgmt_FwdMaxVehSpd_kph: accessed-variable=RTE_P_TorqPahMgmt_FwdMaxVehSpd_kph.tec_TorqPahMgmt_FwdMaxVehSpd_kph
            SEND_RTE_P_TorqPahMgmt_VehSpdLmtSts_Flg_tec_TorqPahMgmt_VehSpdLmtSts_Flg: accessed-variable=RTE_P_TorqPahMgmt_VehSpdLmtSts_Flg.tec_TorqPahMgmt_VehSpdLmtSts_Flg
            SEND_RTE_P_TorqPahMgmt_VehSpdLmtTq_Nm_tec_TorqPahMgmt_VehSpdLmtTq_Nm: accessed-variable=RTE_P_TorqPahMgmt_VehSpdLmtTq_Nm.tec_TorqPahMgmt_VehSpdLmtTq_Nm
      runnable R_SpdLmt_Init
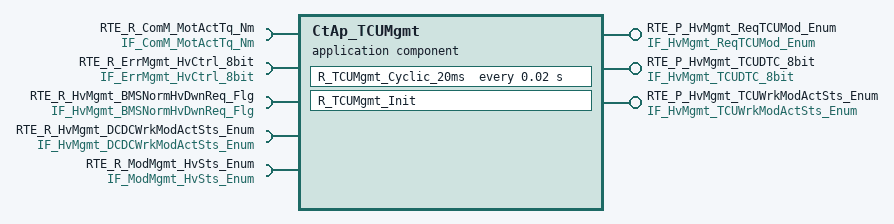
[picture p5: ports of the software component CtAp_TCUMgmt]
  application sw component type CtAp_TCUMgmt
    provide port RTE_P_HvMgmt_ReqTCUMod_Enum: nonqueued-sender-com-spec{data-element=tec_HvMgmt_ReqTCUMod_Enum, init-value=0}, provided-interface=IF_HvMgmt_ReqTCUMod_Enum
    provide port RTE_P_HvMgmt_TCUDTC_8bit: nonqueued-sender-com-spec{data-element=tec_HvMgmt_TCUDTC_8bit, init-value=0}, provided-interface=IF_HvMgmt_TCUDTC_8bit
    provide port RTE_P_HvMgmt_TCUWrkModActSts_Enum: nonqueued-sender-com-spec{data-element=tec_HvMgmt_TCUWrkModActSts_Enum, init-value=0}, provided-interface=IF_HvMgmt_TCUWrkModActSts_Enum
    5 x require port:
      RTE_R_ComM_MotActTq_Nm: nonqueued-receiver-com-spec{data-element=tec_ComM_MotActTq_Nm, filter=data-filter-type=ALWAYS, init-value=0}, required-interface=IF_ComM_MotActTq_Nm
      RTE_R_ErrMgmt_HvCtrl_8bit: nonqueued-receiver-com-spec{data-element=tec_ErrMgmt_HvCtrl_8bit, filter=data-filter-type=ALWAYS, init-value=0}, required-interface=IF_ErrMgmt_HvCtrl_8bit
      RTE_R_HvMgmt_BMSNormHvDwnReq_Flg: nonqueued-receiver-com-spec{data-element=tec_HvMgmt_BMSNormHvDwnReq_Flg, filter=data-filter-type=ALWAYS, init-value=0}, required-interface=IF_HvMgmt_BMSNormHvDwnReq_Flg
      RTE_R_HvMgmt_DCDCWrkModActSts_Enum: nonqueued-receiver-com-spec{data-element=tec_HvMgmt_DCDCWrkModActSts_Enum, filter=data-filter-type=ALWAYS, init-value=0}, required-interface=IF_HvMgmt_DCDCWrkModActSts_Enum
      RTE_R_ModMgmt_HvSts_Enum: nonqueued-receiver-com-spec{data-element=tec_ModMgmt_HvSts_Enum, filter=data-filter-type=ALWAYS, init-value=0}, required-interface=IF_ModMgmt_HvSts_Enum
    behavior CtAp_TCUMgmt_InternalBehavior
      timing event TMT_R_TCUMgmt_Cyclic_20ms: start-on-event=R_TCUMgmt_Cyclic_20ms, period=0.02
      init event CtAp_TCUMgmt_InitEvent: start-on-event=R_TCUMgmt_Init
      runnable R_TCUMgmt_Cyclic_20ms
        data-receive-point-by-arguments:
          5 x access:
            REC_RTE_R_ComM_MotActTq_Nm_tec_ComM_MotActTq_Nm: accessed-variable=RTE_R_ComM_MotActTq_Nm.tec_ComM_MotActTq_Nm
            REC_RTE_R_ErrMgmt_HvCtrl_8bit_tec_ErrMgmt_HvCtrl_8bit: accessed-variable=RTE_R_ErrMgmt_HvCtrl_8bit.tec_ErrMgmt_HvCtrl_8bit
            REC_RTE_R_HvMgmt_BMSNormHvDwnReq_Flg_tec_HvMgmt_BMSNormHvDwnReq_Flg: accessed-variable=RTE_R_HvMgmt_BMSNormHvDwnReq_Flg.tec_HvMgmt_BMSNormHvDwnReq_Flg
            REC_RTE_R_HvMgmt_DCDCWrkModActSts_Enum_tec_HvMgmt_DCDCWrkModActSts_Enum: accessed-variable=RTE_R_HvMgmt_DCDCWrkModActSts_Enum.tec_HvMgmt_DCDCWrkModActSts_Enum
            REC_RTE_R_ModMgmt_HvSts_Enum_tec_ModMgmt_HvSts_Enum: accessed-variable=RTE_R_ModMgmt_HvSts_Enum.tec_ModMgmt_HvSts_Enum
        data-send-points:
          access SEND_RTE_P_HvMgmt_ReqTCUMod_Enum_tec_HvMgmt_ReqTCUMod_Enum: accessed-variable=RTE_P_HvMgmt_ReqTCUMod_Enum.tec_HvMgmt_ReqTCUMod_Enum
          access SEND_RTE_P_HvMgmt_TCUDTC_8bit_tec_HvMgmt_TCUDTC_8bit: accessed-variable=RTE_P_HvMgmt_TCUDTC_8bit.tec_HvMgmt_TCUDTC_8bit
          access SEND_RTE_P_HvMgmt_TCUWrkModActSts_Enum_tec_HvMgmt_TCUWrkModActSts_Enum: accessed-variable=RTE_P_HvMgmt_TCUWrkModActSts_Enum.tec_HvMgmt_TCUWrkModActSts_Enum
      runnable R_TCUMgmt_Init
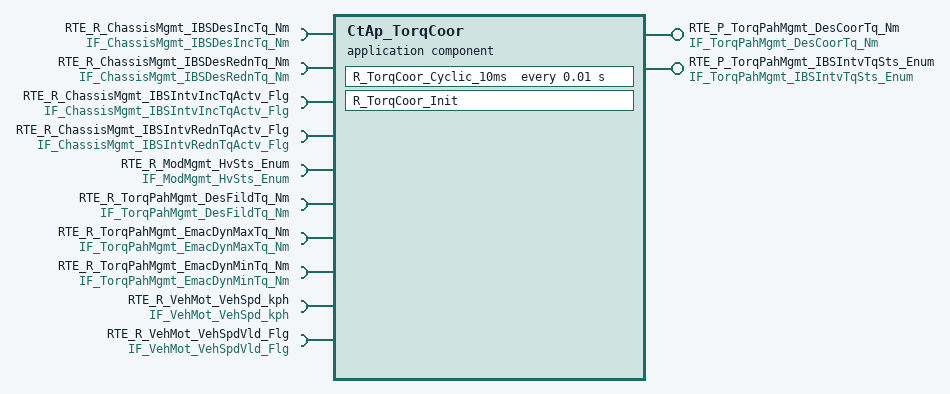
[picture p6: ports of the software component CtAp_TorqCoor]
  application sw component type CtAp_TorqCoor
    provide port RTE_P_TorqPahMgmt_DesCoorTq_Nm: nonqueued-sender-com-spec{data-element=tec_TorqPahMgmt_DesCoorTq_Nm, init-value=0}, provided-interface=IF_TorqPahMgmt_DesCoorTq_Nm
    provide port RTE_P_TorqPahMgmt_IBSIntvTqSts_Enum: nonqueued-sender-com-spec{data-element=tec_TorqPahMgmt_IBSIntvTqSts_Enum, init-value=0}, provided-interface=IF_TorqPahMgmt_IBSIntvTqSts_Enum
    10 x require port:
      RTE_R_ChassisMgmt_IBSDesIncTq_Nm: nonqueued-receiver-com-spec{data-element=tec_ChassisMgmt_IBSDesIncTq_Nm, filter=data-filter-type=ALWAYS, init-value=0}, required-interface=IF_ChassisMgmt_IBSDesIncTq_Nm
      RTE_R_ChassisMgmt_IBSDesRednTq_Nm: nonqueued-receiver-com-spec{data-element=tec_ChassisMgmt_IBSDesRednTq_Nm, filter=data-filter-type=ALWAYS, init-value=0}, required-interface=IF_ChassisMgmt_IBSDesRednTq_Nm
      RTE_R_ChassisMgmt_IBSIntvIncTqActv_Flg: nonqueued-receiver-com-spec{data-element=tec_ChassisMgmt_IBSIntvIncTqActv_Flg, filter=data-filter-type=ALWAYS, init-value=0}, required-interface=IF_ChassisMgmt_IBSIntvIncTqActv_Flg
      RTE_R_ChassisMgmt_IBSIntvRednTqActv_Flg: nonqueued-receiver-com-spec{data-element=tec_ChassisMgmt_IBSIntvRednTqActv_Flg, filter=data-filter-type=ALWAYS, init-value=0}, required-interface=IF_ChassisMgmt_IBSIntvRednTqActv_Flg
      RTE_R_ModMgmt_HvSts_Enum: nonqueued-receiver-com-spec{data-element=tec_ModMgmt_HvSts_Enum, filter=data-filter-type=ALWAYS, init-value=0}, required-interface=IF_ModMgmt_HvSts_Enum
      RTE_R_TorqPahMgmt_DesFildTq_Nm: nonqueued-receiver-com-spec{data-element=tec_TorqPahMgmt_DesFildTq_Nm, filter=data-filter-type=ALWAYS, init-value=0}, required-interface=IF_TorqPahMgmt_DesFildTq_Nm
      RTE_R_TorqPahMgmt_EmacDynMaxTq_Nm: nonqueued-receiver-com-spec{data-element=tec_TorqPahMgmt_EmacDynMaxTq_Nm, filter=data-filter-type=ALWAYS, init-value=0}, required-interface=IF_TorqPahMgmt_EmacDynMaxTq_Nm
      RTE_R_TorqPahMgmt_EmacDynMinTq_Nm: nonqueued-receiver-com-spec{data-element=tec_TorqPahMgmt_EmacDynMinTq_Nm, filter=data-filter-type=ALWAYS, init-value=0}, required-interface=IF_TorqPahMgmt_EmacDynMinTq_Nm
      RTE_R_VehMot_VehSpd_kph: nonqueued-receiver-com-spec{data-element=tec_VehMot_VehSpd_kph, filter=data-filter-type=ALWAYS, init-value=0}, required-interface=IF_VehMot_VehSpd_kph
      RTE_R_VehMot_VehSpdVld_Flg: nonqueued-receiver-com-spec{data-element=tec_VehMot_VehSpdVld_Flg, filter=data-filter-type=ALWAYS, init-value=0}, required-interface=IF_VehMot_VehSpdVld_Flg
    behavior CtAp_TorqCoor_InternalBehavior
      timing event TMT_R_TorqCoor_Cyclic_10ms: start-on-event=R_TorqCoor_Cyclic_10ms, period=0.01
      init event CtAp_TorqCoor_InitEvent: start-on-event=R_TorqCoor_Init
      runnable R_TorqCoor_Cyclic_10ms
        data-receive-point-by-arguments:
          10 x access:
            REC_RTE_R_ChassisMgmt_IBSDesIncTq_Nm_tec_ChassisMgmt_IBSDesIncTq_Nm: accessed-variable=RTE_R_ChassisMgmt_IBSDesIncTq_Nm.tec_ChassisMgmt_IBSDesIncTq_Nm
            REC_RTE_R_ChassisMgmt_IBSDesRednTq_Nm_tec_ChassisMgmt_IBSDesRednTq_Nm: accessed-variable=RTE_R_ChassisMgmt_IBSDesRednTq_Nm.tec_ChassisMgmt_IBSDesRednTq_Nm
            REC_RTE_R_ChassisMgmt_IBSIntvIncTqActv_Flg_tec_ChassisMgmt_IBSIntvIncTqActv_Flg: accessed-variable=RTE_R_ChassisMgmt_IBSIntvIncTqActv_Flg.tec_ChassisMgmt_IBSIntvIncTqActv_Flg
            REC_RTE_R_ChassisMgmt_IBSIntvRednTqActv_Flg_tec_ChassisMgmt_IBSIntvRednTqActv_Flg: accessed-variable=RTE_R_ChassisMgmt_IBSIntvRednTqActv_Flg.tec_ChassisMgmt_IBSIntvRednTqActv_Flg
            REC_RTE_R_ModMgmt_HvSts_Enum_tec_ModMgmt_HvSts_Enum: accessed-variable=RTE_R_ModMgmt_HvSts_Enum.tec_ModMgmt_HvSts_Enum
            REC_RTE_R_TorqPahMgmt_DesFildTq_Nm_tec_TorqPahMgmt_DesFildTq_Nm: accessed-variable=RTE_R_TorqPahMgmt_DesFildTq_Nm.tec_TorqPahMgmt_DesFildTq_Nm
            REC_RTE_R_TorqPahMgmt_EmacDynMaxTq_Nm_tec_TorqPahMgmt_EmacDynMaxTq_Nm: accessed-variable=RTE_R_TorqPahMgmt_EmacDynMaxTq_Nm.tec_TorqPahMgmt_EmacDynMaxTq_Nm
            REC_RTE_R_TorqPahMgmt_EmacDynMinTq_Nm_tec_TorqPahMgmt_EmacDynMinTq_Nm: accessed-variable=RTE_R_TorqPahMgmt_EmacDynMinTq_Nm.tec_TorqPahMgmt_EmacDynMinTq_Nm
            REC_RTE_R_VehMot_VehSpd_kph_tec_VehMot_VehSpd_kph: accessed-variable=RTE_R_VehMot_VehSpd_kph.tec_VehMot_VehSpd_kph
            REC_RTE_R_VehMot_VehSpdVld_Flg_tec_VehMot_VehSpdVld_Flg: accessed-variable=RTE_R_VehMot_VehSpdVld_Flg.tec_VehMot_VehSpdVld_Flg
        data-send-points:
          access SEND_RTE_P_TorqPahMgmt_DesCoorTq_Nm_tec_TorqPahMgmt_DesCoorTq_Nm: accessed-variable=RTE_P_TorqPahMgmt_DesCoorTq_Nm.tec_TorqPahMgmt_DesCoorTq_Nm
          access SEND_RTE_P_TorqPahMgmt_IBSIntvTqSts_Enum_tec_TorqPahMgmt_IBSIntvTqSts_Enum: accessed-variable=RTE_P_TorqPahMgmt_IBSIntvTqSts_Enum.tec_TorqPahMgmt_IBSIntvTqSts_Enum
      runnable R_TorqCoor_Init
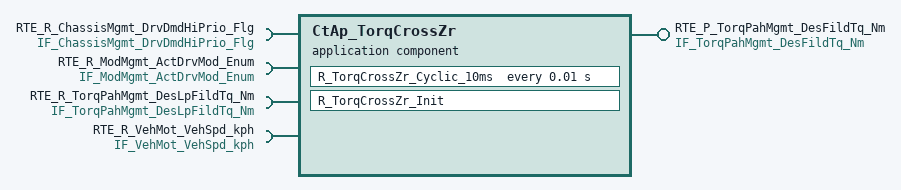
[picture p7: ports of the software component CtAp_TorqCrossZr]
  application sw component type CtAp_TorqCrossZr
    provide port RTE_P_TorqPahMgmt_DesFildTq_Nm: nonqueued-sender-com-spec{data-element=tec_TorqPahMgmt_DesFildTq_Nm, init-value=0}, provided-interface=IF_TorqPahMgmt_DesFildTq_Nm
    4 x require port:
      RTE_R_ChassisMgmt_DrvDmdHiPrio_Flg: nonqueued-receiver-com-spec{data-element=tec_ChassisMgmt_DrvDmdHiPrio_Flg, filter=data-filter-type=ALWAYS, init-value=0}, required-interface=IF_ChassisMgmt_DrvDmdHiPrio_Flg
      RTE_R_ModMgmt_ActDrvMod_Enum: nonqueued-receiver-com-spec{data-element=tec_ModMgmt_ActDrvMod_Enum, filter=data-filter-type=ALWAYS, init-value=0}, required-interface=IF_ModMgmt_ActDrvMod_Enum
      RTE_R_TorqPahMgmt_DesLpFildTq_Nm: nonqueued-receiver-com-spec{data-element=tec_TorqPahMgmt_DesLpFildTq_Nm, filter=data-filter-type=ALWAYS, init-value=0}, required-interface=IF_TorqPahMgmt_DesLpFildTq_Nm
      RTE_R_VehMot_VehSpd_kph: nonqueued-receiver-com-spec{data-element=tec_VehMot_VehSpd_kph, filter=data-filter-type=ALWAYS, init-value=0}, required-interface=IF_VehMot_VehSpd_kph
    behavior CtAp_TorqCrossZr_InternalBehavior
      timing event TMT_R_TorqCrossZr_Cyclic_10ms: start-on-event=R_TorqCrossZr_Cyclic_10ms, period=0.01
      init event CtAp_TorqCrossZr_InitEvent: start-on-event=R_TorqCrossZr_Init
      runnable R_TorqCrossZr_Cyclic_10ms
        data-receive-point-by-arguments:
          4 x access:
            REC_RTE_R_ChassisMgmt_DrvDmdHiPrio_Flg_tec_ChassisMgmt_DrvDmdHiPrio_Flg: accessed-variable=RTE_R_ChassisMgmt_DrvDmdHiPrio_Flg.tec_ChassisMgmt_DrvDmdHiPrio_Flg
            REC_RTE_R_ModMgmt_ActDrvMod_Enum_tec_ModMgmt_ActDrvMod_Enum: accessed-variable=RTE_R_ModMgmt_ActDrvMod_Enum.tec_ModMgmt_ActDrvMod_Enum
            REC_RTE_R_TorqPahMgmt_DesLpFildTq_Nm_tec_TorqPahMgmt_DesLpFildTq_Nm: accessed-variable=RTE_R_TorqPahMgmt_DesLpFildTq_Nm.tec_TorqPahMgmt_DesLpFildTq_Nm
            REC_RTE_R_VehMot_VehSpd_kph_tec_VehMot_VehSpd_kph: accessed-variable=RTE_R_VehMot_VehSpd_kph.tec_VehMot_VehSpd_kph
        data-send-points:
          access SEND_RTE_P_TorqPahMgmt_DesFildTq_Nm_tec_TorqPahMgmt_DesFildTq_Nm: accessed-variable=RTE_P_TorqPahMgmt_DesFildTq_Nm.tec_TorqPahMgmt_DesFildTq_Nm
      runnable R_TorqCrossZr_Init
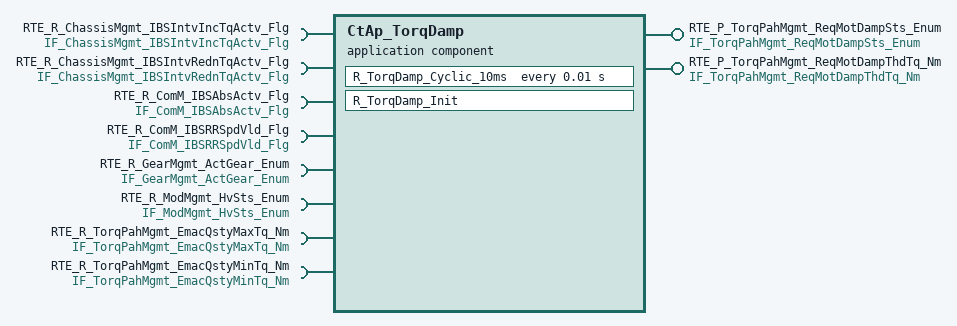
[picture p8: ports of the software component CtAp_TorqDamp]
  application sw component type CtAp_TorqDamp
    provide port RTE_P_TorqPahMgmt_ReqMotDampSts_Enum: nonqueued-sender-com-spec{data-element=tec_TorqPahMgmt_ReqMotDampSts_Enum, init-value=0}, provided-interface=IF_TorqPahMgmt_ReqMotDampSts_Enum
    provide port RTE_P_TorqPahMgmt_ReqMotDampThdTq_Nm: nonqueued-sender-com-spec{data-element=tec_TorqPahMgmt_ReqMotDampThdTq_Nm, init-value=0}, provided-interface=IF_TorqPahMgmt_ReqMotDampThdTq_Nm
    8 x require port:
      RTE_R_ChassisMgmt_IBSIntvIncTqActv_Flg: nonqueued-receiver-com-spec{data-element=tec_ChassisMgmt_IBSIntvIncTqActv_Flg, filter=data-filter-type=ALWAYS, init-value=0}, required-interface=IF_ChassisMgmt_IBSIntvIncTqActv_Flg
      RTE_R_ChassisMgmt_IBSIntvRednTqActv_Flg: nonqueued-receiver-com-spec{data-element=tec_ChassisMgmt_IBSIntvRednTqActv_Flg, filter=data-filter-type=ALWAYS, init-value=0}, required-interface=IF_ChassisMgmt_IBSIntvRednTqActv_Flg
      RTE_R_ComM_IBSAbsActv_Flg: nonqueued-receiver-com-spec{data-element=tec_ComM_IBSAbsActv_Flg, filter=data-filter-type=ALWAYS, init-value=0}, required-interface=IF_ComM_IBSAbsActv_Flg
      RTE_R_ComM_IBSRRSpdVld_Flg: nonqueued-receiver-com-spec{data-element=tec_ComM_IBSRRSpdVld_Flg, filter=data-filter-type=ALWAYS, init-value=0}, required-interface=IF_ComM_IBSRRSpdVld_Flg
      RTE_R_GearMgmt_ActGear_Enum: nonqueued-receiver-com-spec{data-element=tec_GearMgmt_ActGear_Enum, filter=data-filter-type=ALWAYS, init-value=0}, required-interface=IF_GearMgmt_ActGear_Enum
      RTE_R_ModMgmt_HvSts_Enum: nonqueued-receiver-com-spec{data-element=tec_ModMgmt_HvSts_Enum, filter=data-filter-type=ALWAYS, init-value=0}, required-interface=IF_ModMgmt_HvSts_Enum
      RTE_R_TorqPahMgmt_EmacQstyMaxTq_Nm: nonqueued-receiver-com-spec{data-element=tec_TorqPahMgmt_EmacQstyMaxTq_Nm, filter=data-filter-type=ALWAYS, init-value=0}, required-interface=IF_TorqPahMgmt_EmacQstyMaxTq_Nm
      RTE_R_TorqPahMgmt_EmacQstyMinTq_Nm: nonqueued-receiver-com-spec{data-element=tec_TorqPahMgmt_EmacQstyMinTq_Nm, filter=data-filter-type=ALWAYS, init-value=0}, required-interface=IF_TorqPahMgmt_EmacQstyMinTq_Nm
    behavior CtAp_TorqDamp_InternalBehavior
      timing event TMT_R_TorqDamp_Cyclic_10ms: start-on-event=R_TorqDamp_Cyclic_10ms, period=0.01
      init event CtAp_TorqDamp_InitEvent: start-on-event=R_TorqDamp_Init
      runnable R_TorqDamp_Cyclic_10ms
        data-receive-point-by-arguments:
          8 x access:
            REC_RTE_R_ChassisMgmt_IBSIntvIncTqActv_Flg_tec_ChassisMgmt_IBSIntvIncTqActv_Flg: accessed-variable=RTE_R_ChassisMgmt_IBSIntvIncTqActv_Flg.tec_ChassisMgmt_IBSIntvIncTqActv_Flg
            REC_RTE_R_ChassisMgmt_IBSIntvRednTqActv_Flg_tec_ChassisMgmt_IBSIntvRednTqActv_Flg: accessed-variable=RTE_R_ChassisMgmt_IBSIntvRednTqActv_Flg.tec_ChassisMgmt_IBSIntvRednTqActv_Flg
            REC_RTE_R_ComM_IBSAbsActv_Flg_tec_ComM_IBSAbsActv_Flg: accessed-variable=RTE_R_ComM_IBSAbsActv_Flg.tec_ComM_IBSAbsActv_Flg
            REC_RTE_R_Comm_IBSRRSpdVld_Flg_tec_ComM_IBSRRSpdVld_Flg: accessed-variable=RTE_R_ComM_IBSRRSpdVld_Flg.tec_ComM_IBSRRSpdVld_Flg
            REC_RTE_R_GearMgmt_ActGear_Enum_tec_GearMgmt_ActGear_Enum: accessed-variable=RTE_R_GearMgmt_ActGear_Enum.tec_GearMgmt_ActGear_Enum
            REC_RTE_R_ModMgmt_HvSts_Enum_tec_ModMgmt_HvSts_Enum: accessed-variable=RTE_R_ModMgmt_HvSts_Enum.tec_ModMgmt_HvSts_Enum
            REC_RTE_R_TorqPahMgmt_EmacQstyMaxTq_Nm_tec_TorqPahMgmt_EmacQstyMaxTq_Nm: accessed-variable=RTE_R_TorqPahMgmt_EmacQstyMaxTq_Nm.tec_TorqPahMgmt_EmacQstyMaxTq_Nm
            REC_RTE_R_TorqPahMgmt_EmacQstyMinTq_Nm_tec_TorqPahMgmt_EmacQstyMinTq_Nm: accessed-variable=RTE_R_TorqPahMgmt_EmacQstyMinTq_Nm.tec_TorqPahMgmt_EmacQstyMinTq_Nm
        data-send-points:
          access SEND_RTE_P_TorqPahMgmt_ReqMotDampSts_Enum_tec_TorqPahMgmt_ReqMotDampSts_Enum: accessed-variable=RTE_P_TorqPahMgmt_ReqMotDampSts_Enum.tec_TorqPahMgmt_ReqMotDampSts_Enum
          access SEND_RTE_P_TorqPahMgmt_ReqMotDampThdTq_Nm_tec_TorqPahMgmt_ReqMotDampThdTq_Nm: accessed-variable=RTE_P_TorqPahMgmt_ReqMotDampThdTq_Nm.tec_TorqPahMgmt_ReqMotDampThdTq_Nm
      runnable R_TorqDamp_Init
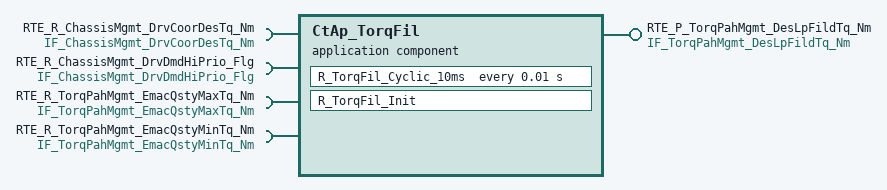
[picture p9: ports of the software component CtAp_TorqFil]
  application sw component type CtAp_TorqFil
    provide port RTE_P_TorqPahMgmt_DesLpFildTq_Nm: nonqueued-sender-com-spec{data-element=tec_TorqPahMgmt_DesLpFildTq_Nm, init-value=0}, provided-interface=IF_TorqPahMgmt_DesLpFildTq_Nm
    4 x require port:
      RTE_R_ChassisMgmt_DrvCoorDesTq_Nm: nonqueued-receiver-com-spec{data-element=tec_ChassisMgmt_DrvCoorDesTq_Nm, filter=data-filter-type=ALWAYS, init-value=0}, required-interface=IF_ChassisMgmt_DrvCoorDesTq_Nm
      RTE_R_ChassisMgmt_DrvDmdHiPrio_Flg: nonqueued-receiver-com-spec{data-element=tec_ChassisMgmt_DrvDmdHiPrio_Flg, filter=data-filter-type=ALWAYS, init-value=0}, required-interface=IF_ChassisMgmt_DrvDmdHiPrio_Flg
      RTE_R_TorqPahMgmt_EmacQstyMaxTq_Nm: nonqueued-receiver-com-spec{data-element=tec_TorqPahMgmt_EmacQstyMaxTq_Nm, filter=data-filter-type=ALWAYS, init-value=0}, required-interface=IF_TorqPahMgmt_EmacQstyMaxTq_Nm
      RTE_R_TorqPahMgmt_EmacQstyMinTq_Nm: nonqueued-receiver-com-spec{data-element=tec_TorqPahMgmt_EmacQstyMinTq_Nm, filter=data-filter-type=ALWAYS, init-value=0}, required-interface=IF_TorqPahMgmt_EmacQstyMinTq_Nm
    behavior CtAp_TorqFil_InternalBehavior
      timing event TMT_R_TorqFil_Cyclic_10ms: start-on-event=R_TorqFil_Cyclic_10ms, period=0.01
      init event CtAp_TorqFil_InitEvent: start-on-event=R_TorqFil_Init
      runnable R_TorqFil_Cyclic_10ms
        data-receive-point-by-arguments:
          4 x access:
            REC_RTE_R_ChassisMgmt_DrvCoorDesTq_Nm_tec_ChassisMgmt_DrvCoorDesTq_Nm: accessed-variable=RTE_R_ChassisMgmt_DrvCoorDesTq_Nm.tec_ChassisMgmt_DrvCoorDesTq_Nm
            REC_RTE_R_ChassisMgmt_DrvDmdHiPrio_Flg_tec_ChassisMgmt_DrvDmdHiPrio_Flg: accessed-variable=RTE_R_ChassisMgmt_DrvDmdHiPrio_Flg.tec_ChassisMgmt_DrvDmdHiPrio_Flg
            REC_RTE_R_TorqPahMgmt_EmacQstyMaxTq_Nm_tec_TorqPahMgmt_EmacQstyMaxTq_Nm: accessed-variable=RTE_R_TorqPahMgmt_EmacQstyMaxTq_Nm.tec_TorqPahMgmt_EmacQstyMaxTq_Nm
            REC_RTE_R_TorqPahMgmt_EmacQstyMinTq_Nm_tec_TorqPahMgmt_EmacQstyMinTq_Nm: accessed-variable=RTE_R_TorqPahMgmt_EmacQstyMinTq_Nm.tec_TorqPahMgmt_EmacQstyMinTq_Nm
        data-send-points:
          access SEND_RTE_P_TorqPahMgmt_DesLpFildTq_Nm_tec_TorqPahMgmt_DesLpFildTq_Nm: accessed-variable=RTE_P_TorqPahMgmt_DesLpFildTq_Nm.tec_TorqPahMgmt_DesLpFildTq_Nm
      runnable R_TorqFil_Init
  application sw component type CtAp_TorqLmt
    4 x provide port:
      RTE_P_TorqPahMgmt_EmacDynMaxTq_Nm: nonqueued-sender-com-spec{data-element=tec_TorqPahMgmt_EmacDynMaxTq_Nm, init-value=0}, provided-interface=IF_TorqPahMgmt_EmacDynMaxTq_Nm
      RTE_P_TorqPahMgmt_EmacDynMinTq_Nm: nonqueued-sender-com-spec{data-element=tec_TorqPahMgmt_EmacDynMinTq_Nm, init-value=0}, provided-interface=IF_TorqPahMgmt_EmacDynMinTq_Nm
      RTE_P_TorqPahMgmt_EmacQstyMaxTq_Nm: nonqueued-sender-com-spec{data-element=tec_TorqPahMgmt_EmacQstyMaxTq_Nm, init-value=0}, provided-interface=IF_TorqPahMgmt_EmacQstyMaxTq_Nm
      RTE_P_TorqPahMgmt_EmacQstyMinTq_Nm: nonqueued-sender-com-spec{data-element=tec_TorqPahMgmt_EmacQstyMinTq_Nm, init-value=0}, provided-interface=IF_TorqPahMgmt_EmacQstyMinTq_Nm
    9 x require port:
      RTE_R_ComM_MCUUDc_V: nonqueued-receiver-com-spec{data-element=tec_ComM_MCUUDc_V, filter=data-filter-type=ALWAYS, init-value=0}, required-interface=IF_ComM_MCUUDc_V
      RTE_R_ComM_MotActSpd_rpm: nonqueued-receiver-com-spec{data-element=tec_ComM_MotActSpd_rpm, filter=data-filter-type=ALWAYS, init-value=0}, required-interface=IF_ComM_MotActSpd_rpm
      RTE_R_ComM_MotMaxTq_Nm: nonqueued-receiver-com-spec{data-element=tec_ComM_MotMaxTq_Nm, filter=data-filter-type=ALWAYS, init-value=0}, required-interface=IF_ComM_MotMaxTq_Nm
      RTE_R_ComM_MotMinTq_Nm: nonqueued-receiver-com-spec{data-element=tec_ComM_MotMinTq_Nm, filter=data-filter-type=ALWAYS, init-value=0}, required-interface=IF_ComM_MotMinTq_Nm
      RTE_R_EgyMgmt_MCULongChrgPwrLmt_Kw: nonqueued-receiver-com-spec{data-element=tec_EgyMgmt_MCULongChrgPwrLmt_Kw, filter=data-filter-type=ALWAYS, init-value=0}, required-interface=IF_EgyMgmt_MCULongChrgPwrLmt_Kw
      RTE_R_EgyMgmt_MCULongDchaPwrLmt_Kw: nonqueued-receiver-com-spec{data-element=tec_EgyMgmt_MCULongDchaPwrLmt_Kw, filter=data-filter-type=ALWAYS, init-value=0}, required-interface=IF_EgyMgmt_MCULongDchaPwrLmt_Kw
      RTE_R_EgyMgmt_MCUShoChrgPwrLmt_Kw: nonqueued-receiver-com-spec{data-element=tec_EgyMgmt_MCUShoChrgPwrLmt_Kw, filter=data-filter-type=ALWAYS, init-value=0}, required-interface=IF_EgyMgmt_MCUShoChrgPwrLmt_Kw
      RTE_R_EgyMgmt_MCUShoDchaPwrLmt_Kw: nonqueued-receiver-com-spec{data-element=tec_EgyMgmt_MCUShoDchaPwrLmt_Kw, filter=data-filter-type=ALWAYS, init-value=0}, required-interface=IF_EgyMgmt_MCUShoDchaPwrLmt_Kw
      RTE_R_ErrMgmt_TqCtrl_8bit: nonqueued-receiver-com-spec{data-element=tec_ErrMgmt_TqCtrl_8bit, filter=data-filter-type=ALWAYS, init-value=0}, required-interface=IF_ErrMgmt_TqCtrl_8bit
    behavior CtAp_TorqLmt_InternalBehavior
      timing event TMT_R_TorqLmt_Cyclic_10ms: start-on-event=R_TorqLmt_Cyclic_10ms, period=0.01
      init event CtAp_TorqLmt_InitEvent: start-on-event=R_TorqLmt_Init
      runnable R_TorqLmt_Cyclic_10ms
        data-receive-point-by-arguments:
          9 x access:
            REC_RTE_R_ComM_MCUUDc_V_tec_ComM_MCUUDc_V: accessed-variable=RTE_R_ComM_MCUUDc_V.tec_ComM_MCUUDc_V
            REC_RTE_R_ComM_MotActSpd_rpm_tec_ComM_MotActSpd_rpm: accessed-variable=RTE_R_ComM_MotActSpd_rpm.tec_ComM_MotActSpd_rpm
            REC_RTE_R_ComM_MotMaxTq_Nm_tec_ComM_MotMaxTq_Nm: accessed-variable=RTE_R_ComM_MotMaxTq_Nm.tec_ComM_MotMaxTq_Nm
            REC_RTE_R_ComM_MotMinTq_Nm_tec_ComM_MotMinTq_Nm: accessed-variable=RTE_R_ComM_MotMinTq_Nm.tec_ComM_MotMinTq_Nm
            REC_RTE_R_EgyMgmt_MCULongChrgPwrLmt_Kw_tec_EgyMgmt_MCULongChrgPwrLmt_Kw: accessed-variable=RTE_R_EgyMgmt_MCULongChrgPwrLmt_Kw.tec_EgyMgmt_MCULongChrgPwrLmt_Kw
            REC_RTE_R_EgyMgmt_MCULongDchaPwrLmt_Kw_tec_EgyMgmt_MCULongDchaPwrLmt_Kw: accessed-variable=RTE_R_EgyMgmt_MCULongDchaPwrLmt_Kw.tec_EgyMgmt_MCULongDchaPwrLmt_Kw
            REC_RTE_R_EgyMgmt_MCUShoChrgPwrLmt_Kw_tec_EgyMgmt_MCUShoChrgPwrLmt_Kw: accessed-variable=RTE_R_EgyMgmt_MCUShoChrgPwrLmt_Kw.tec_EgyMgmt_MCUShoChrgPwrLmt_Kw
            REC_RTE_R_EgyMgmt_MCUShoDchaPwrLmt_Kw_tec_EgyMgmt_MCUShoDchaPwrLmt_Kw: accessed-variable=RTE_R_EgyMgmt_MCUShoDchaPwrLmt_Kw.tec_EgyMgmt_MCUShoDchaPwrLmt_Kw
            REC_RTE_R_ErrMgmt_TqCtrl_8bit_tec_ErrMgmt_TqCtrl_8bit: accessed-variable=RTE_R_ErrMgmt_TqCtrl_8bit.tec_ErrMgmt_TqCtrl_8bit
        data-send-points:
          4 x access:
            SEND_RTE_P_TorqPahMgmt_EmacDynMaxTq_Nm_tec_TorqPahMgmt_EmacDynMaxTq_Nm: accessed-variable=RTE_P_TorqPahMgmt_EmacDynMaxTq_Nm.tec_TorqPahMgmt_EmacDynMaxTq_Nm
            SEND_RTE_P_TorqPahMgmt_EmacDynMinTq_Nm_tec_TorqPahMgmt_EmacDynMinTq_Nm: accessed-variable=RTE_P_TorqPahMgmt_EmacDynMinTq_Nm.tec_TorqPahMgmt_EmacDynMinTq_Nm
            SEND_RTE_P_TorqPahMgmt_EmacQstyMaxTq_Nm_tec_TorqPahMgmt_EmacQstyMaxTq_Nm: accessed-variable=RTE_P_TorqPahMgmt_EmacQstyMaxTq_Nm.tec_TorqPahMgmt_EmacQstyMaxTq_Nm
            SEND_RTE_P_TorqPahMgmt_EmacQstyMinTq_Nm_tec_TorqPahMgmt_EmacQstyMinTq_Nm: accessed-variable=RTE_P_TorqPahMgmt_EmacQstyMinTq_Nm.tec_TorqPahMgmt_EmacQstyMinTq_Nm
      runnable R_TorqLmt_Init
  application sw component type CtAp_TorqModMap
    provide port RTE_P_TorqPahMgmt_DesMotSpd_rpm: nonqueued-sender-com-spec{data-element=tec_TorqPahMgmt_DesMotSpd_rpm, init-value=0}, provided-interface=IF_TorqPahMgmt_DesMotSpd_rpm
    provide port RTE_P_TorqPahMgmt_DesMotTq_Nm: nonqueued-sender-com-spec{data-element=tec_TorqPahMgmt_DesMotTq_Nm, init-value=0}, provided-interface=IF_TorqPahMgmt_DesMotTq_Nm
    7 x require port:
      RTE_R_ChassisMgmt_OnePedlDesSpd_rpm: nonqueued-receiver-com-spec{data-element=tec_ChassisMgmt_OnePedlDesSpd_rpm, filter=data-filter-type=ALWAYS, init-value=0}, required-interface=IF_ChassisMgmt_OnePedlDesSpd_rpm
      RTE_R_ComM_MotActTq_Nm: nonqueued-receiver-com-spec{data-element=tec_ComM_MotActTq_Nm, filter=data-filter-type=ALWAYS, init-value=0}, required-interface=IF_ComM_MotActTq_Nm
      RTE_R_GearMgmt_TarGearPInhbTq_Flg: nonqueued-receiver-com-spec{data-element=tec_GearMgmt_TarGearPInhbTq_Flg, filter=data-filter-type=ALWAYS, init-value=0}, required-interface=IF_GearMgmt_TarGearPInhbTq_Flg
      RTE_R_HvMgmt_MCUReqSts_Enum: nonqueued-receiver-com-spec{data-element=tec_HvMgmt_MCUReqSts_Enum, filter=data-filter-type=ALWAYS, init-value=0}, required-interface=IF_HvMgmt_MCUReqSts_Enum
      RTE_R_TorqPahMgmt_DesCoorTq_Nm: nonqueued-receiver-com-spec{data-element=tec_TorqPahMgmt_DesCoorTq_Nm, filter=data-filter-type=ALWAYS, init-value=0}, required-interface=IF_TorqPahMgmt_DesCoorTq_Nm
      RTE_R_TorqPahMgmt_TramProtdLmtMaxTq_Nm: nonqueued-receiver-com-spec{data-element=IF_TorqPahMgmt_TramProtdLmtMaxTq_Nm/tec_TorqPahMgmt_TramProtdLmtMaxTq_Nm, filter=data-filter-type=ALWAYS, init-value=0}, required-interface=IF_TorqPahMgmt_TramProtdLmtMaxTq_Nm
      RTE_R_TorqPahMgmt_TramProtdLmtMinTq_Nm: nonqueued-receiver-com-spec{data-element=IF_TorqPahMgmt_TramProtdLmtMinTq_Nm/tec_TorqPahMgmt_TramProtdLmtMinTq_Nm, filter=data-filter-type=ALWAYS, init-value=0}, required-interface=IF_TorqPahMgmt_TramProtdLmtMinTq_Nm
    behavior CtAp_TorqModMap_InternalBehavior
      timing event TMT_R_TorqModMap_Cyclic_10ms: start-on-event=R_TorqModMap_Cyclic_10ms, period=0.01
      init event CtAp_TorqModMap_InitEvent: start-on-event=R_TorqModMap_Init
      runnable R_TorqModMap_Cyclic_10ms
        data-receive-point-by-arguments:
          7 x access:
            REC_RTE_R_ChassisMgmt_OnePedlDesSpd_rpm_tec_ChassisMgmt_OnePedlDesSpd_rpm: accessed-variable=RTE_R_ChassisMgmt_OnePedlDesSpd_rpm.tec_ChassisMgmt_OnePedlDesSpd_rpm
            REC_RTE_R_ComM_MotActTq_Nm_tec_ComM_MotActTq_Nm: accessed-variable=RTE_R_ComM_MotActTq_Nm.tec_ComM_MotActTq_Nm
            REC_RTE_R_GearMgmt_TarGearPInhbTq_Flg_tec_GearMgmt_TarGearPInhbTq_Flg: accessed-variable=RTE_R_GearMgmt_TarGearPInhbTq_Flg.tec_GearMgmt_TarGearPInhbTq_Flg
            REC_RTE_R_HvMgmt_MCUReqSts_Enum_tec_HvMgmt_MCUReqSts_Enum: accessed-variable=RTE_R_HvMgmt_MCUReqSts_Enum.tec_HvMgmt_MCUReqSts_Enum
            REC_RTE_R_TorqPahMgmt_DesCoorTq_Nm_tec_TorqPahMgmt_DesCoorTq_Nm: accessed-variable=RTE_R_TorqPahMgmt_DesCoorTq_Nm.tec_TorqPahMgmt_DesCoorTq_Nm
            REC_RTE_R_TorqPahMgmt_TramProtdLmtMaxTq_Nm_tec_TorqPahMgmt_TramProtdLmtMaxTq_Nm: accessed-variable=RTE_R_TorqPahMgmt_TramProtdLmtMaxTq_Nm.tec_TorqPahMgmt_TramProtdLmtMaxTq_Nm
            REC_RTE_R_TorqPahMgmt_TramProtdLmtMinTq_Nm_tec_TorqPahMgmt_TramProtdLmtMinTq_Nm: accessed-variable=RTE_R_TorqPahMgmt_TramProtdLmtMinTq_Nm.tec_TorqPahMgmt_TramProtdLmtMinTq_Nm
        data-send-points:
          access SEND_RTE_P_TorqPahMgmt_DesMotSpd_rpm_tec_TorqPahMgmt_DesMotSpd_rpm: accessed-variable=RTE_P_TorqPahMgmt_DesMotSpd_rpm.tec_TorqPahMgmt_DesMotSpd_rpm
          access SEND_RTE_P_TorqPahMgmt_DesMotTq_Nm_tec_TorqPahMgmt_DesMotTq_Nm: accessed-variable=RTE_P_TorqPahMgmt_DesMotTq_Nm.tec_TorqPahMgmt_DesMotTq_Nm
      runnable R_TorqModMap_Init
  application sw component type CtAp_TrsmProtd
    provide port RTE_P_TorqPahMgmt_TramProtdLimMaxTq_Nm: nonqueued-sender-com-spec{data-element=IF_TorqPahMgmt_TramProtdLimMaxTq_Nm/tec_TorqPahMgmt_TramProtdLmtMaxTq_Nm, init-value=0}, provided-interface=IF_TorqPahMgmt_TramProtdLimMaxTq_Nm
    provide port RTE_P_TorqPahMgmt_TramProtdLimMinTq_Nm: nonqueued-sender-com-spec{data-element=IF_TorqPahMgmt_TramProtdLimMinTq_Nm/tec_TorqPahMgmt_TramProtdLmtMinTq_Nm, init-value=0}, provided-interface=IF_TorqPahMgmt_TramProtdLimMinTq_Nm
    9 x require port:
      RTE_R_ComM_IBSRLMovgDir_Enum: nonqueued-receiver-com-spec{data-element=tec_ComM_IBSRLMovgDir_Enum, filter=data-filter-type=ALWAYS, init-value=0}, required-interface=IF_ComM_IBSRLMovgDir_Enum
      RTE_R_ComM_IBSRLSpd_kph: nonqueued-receiver-com-spec{data-element=tec_ComM_IBSRLSpd_kph, filter=data-filter-type=ALWAYS, init-value=0}, required-interface=IF_ComM_IBSRLSpd_kph
      RTE_R_ComM_IBSRLSpdVld_Flg: nonqueued-receiver-com-spec{data-element=tec_ComM_IBSRLSpdVld_Flg, filter=data-filter-type=ALWAYS, init-value=0}, required-interface=IF_ComM_IBSRLSpdVld_Flg
      RTE_R_ComM_IBSRRMovgDir_Enum: nonqueued-receiver-com-spec{data-element=tec_ComM_IBSRRMovgDir_Enum, filter=data-filter-type=ALWAYS, init-value=0}, required-interface=IF_ComM_IBSRRMovgDir_Enum
      RTE_R_ComM_IBSRrSpd_kph: nonqueued-receiver-com-spec{data-element=tec_ComM_IBSRRSpd_kph, filter=data-filter-type=ALWAYS, init-value=0}, required-interface=IF_ComM_IBSRrSpd_kph
      RTE_R_ComM_IBSRRSpdVld_Flg: nonqueued-receiver-com-spec{data-element=tec_ComM_IBSRRSpdVld_Flg, filter=data-filter-type=ALWAYS, init-value=0}, required-interface=IF_ComM_IBSRRSpdVld_Flg
      RTE_R_ComM_MotActSpd_rpm: nonqueued-receiver-com-spec{data-element=tec_ComM_MotActSpd_rpm, filter=data-filter-type=ALWAYS, init-value=0}, required-interface=IF_ComM_MotActSpd_rpm
      RTE_R_GearMgmt_ActGear_Enum: nonqueued-receiver-com-spec{data-element=tec_GearMgmt_ActGear_Enum, filter=data-filter-type=ALWAYS, init-value=0}, required-interface=IF_GearMgmt_ActGear_Enum
      RTE_R_VehMot_VehSpd_kph: nonqueued-receiver-com-spec{data-element=tec_VehMot_VehSpd_kph, filter=data-filter-type=ALWAYS, init-value=0}, required-interface=IF_VehMot_VehSpd_kph
    behavior CtAp_TrsmProtd_InternalBehavior
      timing event TMT_R_TrsmProtd_Cyclic_10ms: start-on-event=R_TrsmProtd_Cyclic_10ms, period=0.01
      init event CtAp_TrsmProtd_InitEvent: start-on-event=R_TrsmProtd_Init
      runnable R_TrsmProtd_Cyclic_10ms
        data-receive-point-by-arguments:
          9 x access:
            REC_RTE_R_ComM_IBSRLMovgDir_Enum_tec_ComM_IBSRLMovgDir_Enum: accessed-variable=RTE_R_ComM_IBSRLMovgDir_Enum.tec_ComM_IBSRLMovgDir_Enum
            REC_RTE_R_ComM_IBSRLSpd_kph_tec_ComM_IBSRLSpd_kph: accessed-variable=RTE_R_ComM_IBSRLSpd_kph.tec_ComM_IBSRLSpd_kph
            REC_RTE_R_Comm_IBSRLSpdVld_Flg_tec_ComM_IBSRLSpdVld_Flg: accessed-variable=RTE_R_ComM_IBSRLSpdVld_Flg.tec_ComM_IBSRLSpdVld_Flg
            REC_RTE_R_ComM_IBSRRMovgDir_Enum_tec_ComM_IBSRRMovgDir_Enum: accessed-variable=RTE_R_ComM_IBSRRMovgDir_Enum.tec_ComM_IBSRRMovgDir_Enum
            REC_RTE_R_Comm_IBSRrSpd_kph_tec_ComM_IBSRRSpd_kph: accessed-variable=RTE_R_ComM_IBSRrSpd_kph.tec_ComM_IBSRRSpd_kph
            REC_RTE_R_Comm_IBSRRSpdVld_Flg_tec_ComM_IBSRRSpdVld_Flg: accessed-variable=RTE_R_ComM_IBSRRSpdVld_Flg.tec_ComM_IBSRRSpdVld_Flg
            REC_RTE_R_ComM_MotActSpd_rpm_tec_ComM_MotActSpd_rpm: accessed-variable=RTE_R_ComM_MotActSpd_rpm.tec_ComM_MotActSpd_rpm
            REC_RTE_R_GearMgmt_ActGear_Enum_tec_GearMgmt_ActGear_Enum: accessed-variable=RTE_R_GearMgmt_ActGear_Enum.tec_GearMgmt_ActGear_Enum
            REC_RTE_R_VehMot_VehSpd_kph_tec_VehMot_VehSpd_kph: accessed-variable=RTE_R_VehMot_VehSpd_kph.tec_VehMot_VehSpd_kph
        data-send-points:
          access SEND_RTE_P_TorqPahMgmt_TramProtdLimMaxTq_Nm_tec_TorqPahMgmt_TramProtdLmtMaxTq_Nm: accessed-variable=RTE_P_TorqPahMgmt_TramProtdLimMaxTq_Nm.tec_TorqPahMgmt_TramProtdLmtMaxTq_Nm
          access SEND_RTE_P_TorqPahMgmt_TramProtdLimMinTq_Nm_tec_TorqPahMgmt_TramProtdLmtMinTq_Nm: accessed-variable=RTE_P_TorqPahMgmt_TramProtdLimMinTq_Nm.tec_TorqPahMgmt_TramProtdLmtMinTq_Nm
      runnable R_TrsmProtd_Init
  application sw component type CtAp_VehSpd
    4 x provide port:
      RTE_P_VehMot_VehDirDif_Flg: nonqueued-sender-com-spec{data-element=tec_VehMot_VehDirDif_Flg, init-value=0}, provided-interface=IF_VehMot_VehDirDif_Flg
      RTE_P_VehMot_VehSpd_kph: nonqueued-sender-com-spec{data-element=tec_VehMot_VehSpd_kph, init-value=0}, provided-interface=IF_VehMot_VehSpd_kph
      RTE_P_VehMot_VehSpdABS_kph: nonqueued-sender-com-spec{data-element=tec_VehMot_VehSpdABS_kph, init-value=0}, provided-interface=IF_VehMot_VehSpdABS_kph
      RTE_P_VehMot_VehSpdVld_Flg: nonqueued-sender-com-spec{data-element=tec_VehMot_VehSpdVld_Flg, init-value=0}, provided-interface=IF_VehMot_VehSpdVld_Flg
    10 x require port:
      RTE_R_ComM_IBSFLMovgDir_Enum: nonqueued-receiver-com-spec{data-element=tec_ComM_IBSFLMovgDir_Enum, filter=data-filter-type=ALWAYS, init-value=0}, required-interface=IF_ComM_IBSFLMovgDir_Enum
      RTE_R_ComM_IBSFRMovgDir_Enum: nonqueued-receiver-com-spec{data-element=tec_ComM_IBSFRMovgDir_Enum, filter=data-filter-type=ALWAYS, init-value=0}, required-interface=IF_ComM_IBSFRMovgDir_Enum
      RTE_R_ComM_IBSRLMovgDir_Enum: nonqueued-receiver-com-spec{data-element=tec_ComM_IBSRLMovgDir_Enum, filter=data-filter-type=ALWAYS, init-value=0}, required-interface=IF_ComM_IBSRLMovgDir_Enum
      RTE_R_ComM_IBSRRMovgDir_Enum: nonqueued-receiver-com-spec{data-element=tec_ComM_IBSRRMovgDir_Enum, filter=data-filter-type=ALWAYS, init-value=0}, required-interface=IF_ComM_IBSRRMovgDir_Enum
      RTE_R_ComM_IBSVehSpd_kph: nonqueued-receiver-com-spec{data-element=tec_ComM_IBSVehSpd_kph, filter=data-filter-type=ALWAYS, init-value=0}, required-interface=IF_ComM_IBSVehSpd_kph
      RTE_R_ComM_IBSVehSpdVld_Flg: nonqueued-receiver-com-spec{data-element=tec_ComM_IBSVehSpdVld_Flg, filter=data-filter-type=ALWAYS, init-value=0}, required-interface=IF_ComM_IBSVehSpdVld_Flg
      RTE_R_ComM_MotActSpd_rpm: nonqueued-receiver-com-spec{data-element=tec_ComM_MotActSpd_rpm, filter=data-filter-type=ALWAYS, init-value=0}, required-interface=IF_ComM_MotActSpd_rpm
      RTE_R_ComM_MotActSpdVld_Flg: nonqueued-receiver-com-spec{data-element=tec_ComM_MotActSpdVld_Flg, filter=data-filter-type=ALWAYS, init-value=0}, required-interface=IF_ComM_MotActSpdVld_Flg
      RTE_R_ErrMgmt_ComFailDTC_16bit: nonqueued-receiver-com-spec{data-element=tec_ErrMgmt_ComFailDTC_16bit, filter=data-filter-type=ALWAYS, init-value=0}, required-interface=IF_ErrMgmt_ComFailDTC_16bit
      RTE_R_GearMgmt_ActGear_Enum: nonqueued-receiver-com-spec{data-element=tec_GearMgmt_ActGear_Enum, filter=data-filter-type=ALWAYS, init-value=0}, required-interface=IF_GearMgmt_ActGear_Enum
    behavior CtAp_VehSpd_InternalBehavior
      timing event TMT_R_VehSpd_Cyclic_10ms: start-on-event=R_VehSpd_Cyclic_10ms, period=0.01
      init event CtAp_VehSpd_InitEvent: start-on-event=R_VehSpd_Init
      runnable R_VehSpd_Cyclic_10ms
        data-receive-point-by-arguments:
          10 x access:
            REC_RTE_R_ComM_IBSFLMovgDir_Enum_tec_ComM_IBSFLMovgDir_Enum: accessed-variable=RTE_R_ComM_IBSFLMovgDir_Enum.tec_ComM_IBSFLMovgDir_Enum
            REC_RTE_R_ComM_IBSFRMovgDir_Enum_tec_ComM_IBSFRMovgDir_Enum: accessed-variable=RTE_R_ComM_IBSFRMovgDir_Enum.tec_ComM_IBSFRMovgDir_Enum
            REC_RTE_R_ComM_IBSRLMovgDir_Enum_tec_ComM_IBSRLMovgDir_Enum: accessed-variable=RTE_R_ComM_IBSRLMovgDir_Enum.tec_ComM_IBSRLMovgDir_Enum
            REC_RTE_R_ComM_IBSRRMovgDir_Enum_tec_ComM_IBSRRMovgDir_Enum: accessed-variable=RTE_R_ComM_IBSRRMovgDir_Enum.tec_ComM_IBSRRMovgDir_Enum
            REC_RTE_R_ComM_IBSVehSpd_kph_tec_ComM_IBSVehSpd_kph: accessed-variable=RTE_R_ComM_IBSVehSpd_kph.tec_ComM_IBSVehSpd_kph
            REC_RTE_R_ComM_IBSVehSpdVld_Flg_tec_ComM_IBSVehSpdVld_Flg: accessed-variable=RTE_R_ComM_IBSVehSpdVld_Flg.tec_ComM_IBSVehSpdVld_Flg
            REC_RTE_R_ComM_MotActSpd_rpm_tec_ComM_MotActSpd_rpm: accessed-variable=RTE_R_ComM_MotActSpd_rpm.tec_ComM_MotActSpd_rpm
            REC_RTE_R_ComM_MotActSpdVld_Flg_tec_ComM_MotActSpdVld_Flg: accessed-variable=RTE_R_ComM_MotActSpdVld_Flg.tec_ComM_MotActSpdVld_Flg
            REC_RTE_R_ErrMgmt_ComFailDTC_16bit_tec_ErrMgmt_ComFailDTC_16bit: accessed-variable=RTE_R_ErrMgmt_ComFailDTC_16bit.tec_ErrMgmt_ComFailDTC_16bit
            REC_RTE_R_GearMgmt_ActGear_Enum_tec_GearMgmt_ActGear_Enum: accessed-variable=RTE_R_GearMgmt_ActGear_Enum.tec_GearMgmt_ActGear_Enum
        data-send-points:
          4 x access:
            SEND_RTE_P_VehMot_VehDirDif_Flg_tec_VehMot_VehDirDif_Flg: accessed-variable=RTE_P_VehMot_VehDirDif_Flg.tec_VehMot_VehDirDif_Flg
            SEND_RTE_P_VehMot_VehSpd_kph_tec_VehMot_VehSpd_kph: accessed-variable=RTE_P_VehMot_VehSpd_kph.tec_VehMot_VehSpd_kph
            SEND_RTE_P_VehMot_VehSpdABS_kph_tec_VehMot_VehSpdABS_kph: accessed-variable=RTE_P_VehMot_VehSpdABS_kph.tec_VehMot_VehSpdABS_kph
            SEND_RTE_P_VehMot_VehSpdVld_Flg_tec_VehMot_VehSpdVld_Flg: accessed-variable=RTE_P_VehMot_VehSpdVld_Flg.tec_VehMot_VehSpdVld_Flg
      runnable R_VehSpd_Init
  application sw component type CtAp_VehStabyCtrl
    4 x provide port:
      RTE_P_ChassisMgmt_IBSIntvIncTq_Nm: nonqueued-sender-com-spec{data-element=tec_ChassisMgmt_IBSIntvIncTq_Nm, init-value=0}, provided-interface=IF_ChassisMgmt_IBSIntvIncTq_Nm
      RTE_P_ChassisMgmt_IBSIntvIncTqActv_Flg: nonqueued-sender-com-spec{data-element=tec_ChassisMgmt_IBSIntvIncTqActv_Flg, init-value=0}, provided-interface=IF_ChassisMgmt_IBSIntvIncTqActv_Flg
      RTE_P_ChassisMgmt_IBSIntvRednTq_Nm: nonqueued-sender-com-spec{data-element=tec_ChassisMgmt_IBSIntvRednTq_Nm, init-value=0}, provided-interface=IF_ChassisMgmt_IBSIntvRednTq_Nm
      RTE_P_ChassisMgmt_IBSIntvRednTqActv_Flg: nonqueued-sender-com-spec{data-element=tec_ChassisMgmt_IBSIntvRednTqActv_Flg, init-value=0}, provided-interface=IF_ChassisMgmt_IBSIntvRednTqActv_Flg
    16 x require port:
      RTE_R_ComM_IBSDtcActv_Flg: nonqueued-receiver-com-spec{data-element=tec_ComM_IBSDtcActv_Flg, filter=data-filter-type=ALWAYS, init-value=0}, required-interface=IF_ComM_IBSDtcActv_Flg
      RTE_R_ComM_IBSDtcFlt_Flg: nonqueued-receiver-com-spec{data-element=tec_ComM_IBSDtcFlt_Flg, filter=data-filter-type=ALWAYS, init-value=0}, required-interface=IF_ComM_IBSDtcFlt_Flg
      RTE_R_ComM_IBSReqIncTq_Nm: nonqueued-receiver-com-spec{data-element=tec_ComM_IBSReqIncTq_Nm, filter=data-filter-type=ALWAYS, init-value=0}, required-interface=IF_ComM_IBSReqIncTq_Nm
      RTE_R_ComM_IBSReqIncTqVld_Flg: nonqueued-receiver-com-spec{data-element=tec_ComM_IBSReqIncTqVld_Flg, filter=data-filter-type=ALWAYS, init-value=0}, required-interface=IF_ComM_IBSReqIncTqVld_Flg
      RTE_R_ComM_IBSReqRednTq_Nm: nonqueued-receiver-com-spec{data-element=tec_ComM_IBSReqRednTq_Nm, filter=data-filter-type=ALWAYS, init-value=0}, required-interface=IF_ComM_IBSReqRednTq_Nm
      RTE_R_ComM_IBSReqRednTqVld_Flg: nonqueued-receiver-com-spec{data-element=tec_ComM_IBSReqRednTqVld_Flg, filter=data-filter-type=ALWAYS, init-value=0}, required-interface=IF_ComM_IBSReqRednTqVld_Flg
      RTE_R_ComM_IBSTcsActv_Flg: nonqueued-receiver-com-spec{data-element=tec_ComM_IBSTcsActv_Flg, filter=data-filter-type=ALWAYS, init-value=0}, required-interface=IF_ComM_IBSTcsActv_Flg
      RTE_R_ComM_IBSTcsFlt_Flg: nonqueued-receiver-com-spec{data-element=tec_ComM_IBSTcsFlt_Flg, filter=data-filter-type=ALWAYS, init-value=0}, required-interface=IF_ComM_IBSTcsFlt_Flg
      RTE_R_ComM_IBSVdcActv_Flg: nonqueued-receiver-com-spec{data-element=tec_ComM_IBSVdcActv_Flg, filter=data-filter-type=ALWAYS, init-value=0}, required-interface=IF_ComM_IBSVdcActv_Flg
      RTE_R_ComM_IBSVdcFlt_Flg: nonqueued-receiver-com-spec{data-element=tec_ComM_IBSVdcFlt_Flg, filter=data-filter-type=ALWAYS, init-value=0}, required-interface=IF_ComM_IBSVdcFlt_Flg
      RTE_R_ErrMgmt_ChassisCtrl_8bit: nonqueued-receiver-com-spec{data-element=tec_ErrMgmt_ChassisCtrl_8bit, filter=data-filter-type=ALWAYS, init-value=0}, required-interface=IF_ErrMgmt_ChassisCtrl_8bit
      RTE_R_GearMgmt_ActGear_Enum: nonqueued-receiver-com-spec{data-element=tec_GearMgmt_ActGear_Enum, filter=data-filter-type=ALWAYS, init-value=0}, required-interface=IF_GearMgmt_ActGear_Enum
      RTE_R_ModMgmt_HvSts_Enum: nonqueued-receiver-com-spec{data-element=tec_ModMgmt_HvSts_Enum, filter=data-filter-type=ALWAYS, init-value=0}, required-interface=IF_ModMgmt_HvSts_Enum
      RTE_R_TorqPahMgmt_EmacQstyMaxTq_Nm: nonqueued-receiver-com-spec{data-element=tec_TorqPahMgmt_EmacQstyMaxTq_Nm, filter=data-filter-type=ALWAYS, init-value=0}, required-interface=IF_TorqPahMgmt_EmacQstyMaxTq_Nm
      RTE_R_TorqPahMgmt_EmacQstyMinTq_Nm: nonqueued-receiver-com-spec{data-element=tec_TorqPahMgmt_EmacQstyMinTq_Nm, filter=data-filter-type=ALWAYS, init-value=0}, required-interface=IF_TorqPahMgmt_EmacQstyMinTq_Nm
      RTE_R_TorqPahMgmt_IBSIntvTqSts_Enum: nonqueued-receiver-com-spec{data-element=tec_TorqPahMgmt_IBSIntvTqSts_Enum, filter=data-filter-type=ALWAYS, init-value=0}, required-interface=IF_TorqPahMgmt_IBSIntvTqSts_Enum
    behavior CtAp_VehStabyCtrl_InternalBehavior
      timing event TMT_R_VehStabyCtrl_Cyclic_10ms: start-on-event=R_VehStabyCtrl_Cyclic_10ms, period=0.01
      init event CtAp_VehStabyCtrl_InitEvent: start-on-event=R_VehStabyCtrl_Init
      runnable R_VehStabyCtrl_Cyclic_10ms
        data-receive-point-by-arguments:
          16 x access:
            REC_RTE_R_ComM_IBSDtcActv_Flg_tec_ComM_IBSDtcActv_Flg: accessed-variable=RTE_R_ComM_IBSDtcActv_Flg.tec_ComM_IBSDtcActv_Flg
            REC_RTE_R_ComM_IBSDtcFlt_Flg_tec_ComM_IBSDtcFlt_Flg: accessed-variable=RTE_R_ComM_IBSDtcFlt_Flg.tec_ComM_IBSDtcFlt_Flg
            REC_RTE_R_Comm_IBSReqIncTq_Nm_tec_ComM_IBSReqIncTq_Nm: accessed-variable=RTE_R_ComM_IBSReqIncTq_Nm.tec_ComM_IBSReqIncTq_Nm
            REC_RTE_R_Comm_IBSReqIncTqVld_Flg_tec_ComM_IBSReqIncTqVld_Flg: accessed-variable=RTE_R_ComM_IBSReqIncTqVld_Flg.tec_ComM_IBSReqIncTqVld_Flg
            REC_RTE_R_Comm_IBSReqRednTq_Nm_tec_ComM_IBSReqRednTq_Nm: accessed-variable=RTE_R_ComM_IBSReqRednTq_Nm.tec_ComM_IBSReqRednTq_Nm
            REC_RTE_R_Comm_IBSReqRednTqVld_Flg_tec_ComM_IBSReqRednTqVld_Flg: accessed-variable=RTE_R_ComM_IBSReqRednTqVld_Flg.tec_ComM_IBSReqRednTqVld_Flg
            REC_RTE_R_ComM_IBSTcsActv_Flg_tec_ComM_IBSTcsActv_Flg: accessed-variable=RTE_R_ComM_IBSTcsActv_Flg.tec_ComM_IBSTcsActv_Flg
            REC_RTE_R_ComM_IBSTcsFlt_Flg_tec_ComM_IBSTcsFlt_Flg: accessed-variable=RTE_R_ComM_IBSTcsFlt_Flg.tec_ComM_IBSTcsFlt_Flg
            REC_RTE_R_ComM_IBSVdcActv_Flg_tec_ComM_IBSVdcActv_Flg: accessed-variable=RTE_R_ComM_IBSVdcActv_Flg.tec_ComM_IBSVdcActv_Flg
            REC_RTE_R_ComM_IBSVdcFlt_Flg_tec_ComM_IBSVdcFlt_Flg: accessed-variable=RTE_R_ComM_IBSVdcFlt_Flg.tec_ComM_IBSVdcFlt_Flg
            REC_RTE_R_ErrMgmt_ChassisCtrl_8bit_tec_ErrMgmt_ChassisCtrl_8bit: accessed-variable=RTE_R_ErrMgmt_ChassisCtrl_8bit.tec_ErrMgmt_ChassisCtrl_8bit
            REC_RTE_R_GearMgmt_ActGear_Enum_tec_GearMgmt_ActGear_Enum: accessed-variable=RTE_R_GearMgmt_ActGear_Enum.tec_GearMgmt_ActGear_Enum
            REC_RTE_R_ModMgmt_HvSts_Enum_tec_ModMgmt_HvSts_Enum: accessed-variable=RTE_R_ModMgmt_HvSts_Enum.tec_ModMgmt_HvSts_Enum
            REC_RTE_R_TorqPahMgmt_EmacQstyMaxTq_Nm_tec_TorqPahMgmt_EmacQstyMaxTq_Nm: accessed-variable=RTE_R_TorqPahMgmt_EmacQstyMaxTq_Nm.tec_TorqPahMgmt_EmacQstyMaxTq_Nm
            REC_RTE_R_TorqPahMgmt_EmacQstyMinTq_Nm_tec_TorqPahMgmt_EmacQstyMinTq_Nm: accessed-variable=RTE_R_TorqPahMgmt_EmacQstyMinTq_Nm.tec_TorqPahMgmt_EmacQstyMinTq_Nm
            REC_RTE_R_TorqPahMgmt_IBSIntvTqSts_Enum_tec_TorqPahMgmt_IBSIntvTqSts_Enum: accessed-variable=RTE_R_TorqPahMgmt_IBSIntvTqSts_Enum.tec_TorqPahMgmt_IBSIntvTqSts_Enum
        data-send-points:
          4 x access:
            SEND_RTE_P_ChassisMgmt_IBSIntvIncTq_Nm_tec_ChassisMgmt_IBSIntvIncTq_Nm: accessed-variable=RTE_P_ChassisMgmt_IBSIntvIncTq_Nm.tec_ChassisMgmt_IBSIntvIncTq_Nm
            SEND_RTE_P_ChassisMgmt_IBSIntvIncTqActv_Flg_tec_ChassisMgmt_IBSIntvIncTqActv_Flg: accessed-variable=RTE_P_ChassisMgmt_IBSIntvIncTqActv_Flg.tec_ChassisMgmt_IBSIntvIncTqActv_Flg
            SEND_RTE_P_ChassisMgmt_IBSIntvRednTq_Nm_tec_ChassisMgmt_IBSIntvRednTq_Nm: accessed-variable=RTE_P_ChassisMgmt_IBSIntvRednTq_Nm.tec_ChassisMgmt_IBSIntvRednTq_Nm
            SEND_RTE_P_ChassisMgmt_IBSIntvRednTqActv_Flg_tec_ChassisMgmt_IBSIntvRednTqActv_Flg: accessed-variable=RTE_P_ChassisMgmt_IBSIntvRednTqActv_Flg.tec_ChassisMgmt_IBSIntvRednTqActv_Flg
      runnable R_VehStabyCtrl_Init
  application sw component type CtAp_VehStat
    4 x provide port:
      RTE_P_ModMgmt_HvSts_Enum: nonqueued-sender-com-spec{data-element=tec_ModMgmt_HvSts_Enum, init-value=0}, provided-interface=IF_ModMgmt_HvSts_Enum
      RTE_P_ModMgmt_ReqSleep_Flg: nonqueued-sender-com-spec{data-element=tec_ModMgmt_ReqSleep_Flg, init-value=0}, provided-interface=IF_ModMgmt_ReqSleep_Flg
      RTE_P_ModMgmt_RstCtrl_Flg: nonqueued-sender-com-spec{data-element=tec_ModMgmt_RstCtrl_Flg, init-value=0}, provided-interface=IF_ModMgmt_RstCtrl_Flg
      RTE_P_ModMgmt_SysRdy_Enum: nonqueued-sender-com-spec{data-element=tec_ModMgmt_SysRdy_Enum, init-value=0}, provided-interface=IF_ModMgmt_SysRdy_Enum
    8 x require port:
      RTE_R_HvMgmt_BMSNegRlyActSts_Enum: nonqueued-receiver-com-spec{data-element=tec_HvMgmt_BMSNegRlyActSts_Enum, filter=data-filter-type=ALWAYS, init-value=0}, required-interface=IF_HvMgmt_BMSNegRlyActSts_Enum
      RTE_R_HvMgmt_BMSPosRlyActSts_Enum: nonqueued-receiver-com-spec{data-element=tec_HvMgmt_BMSPosRlyActSts_Enum, filter=data-filter-type=ALWAYS, init-value=0}, required-interface=IF_HvMgmt_BMSPosRlyActSts_Enum
      RTE_R_HvMgmt_BMSWrkModActSts_Enum: nonqueued-receiver-com-spec{data-element=tec_HvMgmt_BMSWrkModActSts_Enum, filter=data-filter-type=ALWAYS, init-value=0}, required-interface=IF_HvMgmt_BMSWrkModActSts_Enum
      RTE_R_HvMgmt_MCUWrkModActSts_Enum: nonqueued-receiver-com-spec{data-element=tec_HvMgmt_MCUWrkModActSts_Enum, filter=data-filter-type=ALWAYS, init-value=0}, required-interface=IF_HvMgmt_MCUWrkModActSts_Enum
      RTE_R_LvMgmt_LvPwrDwn_Flg: nonqueued-receiver-com-spec{data-element=tec_LvMgmt_LvPwrDwn_Flg, filter=data-filter-type=ALWAYS, init-value=0}, required-interface=IF_LvMgmt_LvPwrDwn_Flg
      RTE_R_LvMgmt_SelfChkSts_Flg: nonqueued-receiver-com-spec{data-element=tec_LvMgmt_SelfChkSts_Flg, filter=data-filter-type=ALWAYS, init-value=0}, required-interface=IF_LvMgmt_SelfChkSts_Flg
      RTE_R_LvMgmt_WakeUpReq_Flg: nonqueued-receiver-com-spec{data-element=tec_LvMgmt_WakeUpReq_Flg, filter=data-filter-type=ALWAYS, init-value=0}, required-interface=IF_LvMgmt_WakeUpReq_Flg
      RTE_R_VehMot_VehSpd_kph: nonqueued-receiver-com-spec{data-element=tec_VehMot_VehSpd_kph, filter=data-filter-type=ALWAYS, init-value=0}, required-interface=IF_VehMot_VehSpd_kph
    behavior CtAp_VehStat_InternalBehavior
      timing event TMT_R_VehStat_Cyclic_20ms: start-on-event=R_VehStat_Cyclic_20ms, period=0.02
      init event CtAp_VehStat_InitEvent: start-on-event=R_VehStat_Init
      runnable R_VehStat_Cyclic_20ms
        data-receive-point-by-arguments:
          8 x access:
            REC_RTE_R_HvMgmt_BMSNegRlyActSts_Enum_tec_HvMgmt_BMSNegRlyActSts_Enum: accessed-variable=RTE_R_HvMgmt_BMSNegRlyActSts_Enum.tec_HvMgmt_BMSNegRlyActSts_Enum
            REC_RTE_R_HvMgmt_BMSPosRlyActSts_Enum_tec_HvMgmt_BMSPosRlyActSts_Enum: accessed-variable=RTE_R_HvMgmt_BMSPosRlyActSts_Enum.tec_HvMgmt_BMSPosRlyActSts_Enum
            REC_RTE_R_HvMgmt_BMSWrkModActSts_Enum_tec_HvMgmt_BMSWrkModActSts_Enum: accessed-variable=RTE_R_HvMgmt_BMSWrkModActSts_Enum.tec_HvMgmt_BMSWrkModActSts_Enum
            REC_RTE_R_HvMgmt_MCUWrkModActSts_Enum_tec_HvMgmt_MCUWrkModActSts_Enum: accessed-variable=RTE_R_HvMgmt_MCUWrkModActSts_Enum.tec_HvMgmt_MCUWrkModActSts_Enum
            REC_RTE_R_LvMgmt_LvPwrDwn_Flg_tec_LvMgmt_LvPwrDwn_Flg: accessed-variable=RTE_R_LvMgmt_LvPwrDwn_Flg.tec_LvMgmt_LvPwrDwn_Flg
            REC_RTE_R_LvMgmt_SelfChkSts_Flg_tec_LvMgmt_SelfChkSts_Flg: accessed-variable=RTE_R_LvMgmt_SelfChkSts_Flg.tec_LvMgmt_SelfChkSts_Flg
            REC_RTE_R_LvMgmt_WakeUpReq_Flg_tec_LvMgmt_WakeUpReq_Flg: accessed-variable=RTE_R_LvMgmt_WakeUpReq_Flg.tec_LvMgmt_WakeUpReq_Flg
            REC_RTE_R_VehMot_VehSpd_kph_tec_VehMot_VehSpd_kph: accessed-variable=RTE_R_VehMot_VehSpd_kph.tec_VehMot_VehSpd_kph
        data-send-points:
          4 x access:
            SEND_RTE_P_ModMgmt_HvSts_Enum_tec_ModMgmt_HvSts_Enum: accessed-variable=RTE_P_ModMgmt_HvSts_Enum.tec_ModMgmt_HvSts_Enum
            SEND_RTE_P_ModMgmt_ReqSleep_Flg_tec_ModMgmt_ReqSleep_Flg: accessed-variable=RTE_P_ModMgmt_ReqSleep_Flg.tec_ModMgmt_ReqSleep_Flg
            SEND_RTE_P_ModMgmt_RstCtrl_Flg_tec_ModMgmt_RstCtrl_Flg: accessed-variable=RTE_P_ModMgmt_RstCtrl_Flg.tec_ModMgmt_RstCtrl_Flg
            SEND_RTE_P_ModMgmt_SysRdy_Enum_tec_ModMgmt_SysRdy_Enum: accessed-variable=RTE_P_ModMgmt_SysRdy_Enum.tec_ModMgmt_SysRdy_Enum
      runnable R_VehStat_Init
  application sw component type CtAp_WakeUpRsn
    provide port RTE_P_LvMgmt_WakeUpReq_Flg: nonqueued-sender-com-spec{data-element=tec_LvMgmt_WakeUpReq_Flg, init-value=0}, provided-interface=IF_LvMgmt_WakeUpReq_Flg
    provide port RTE_P_LvMgmt_WakeUpSrc_Enum: nonqueued-sender-com-spec{data-element=tec_LvMgmt_WakeUpSrc_Enum, init-value=0}, provided-interface=IF_LvMgmt_WakeUpSrc_Enum
    12 x require port:
      RTE_R_BswM_CANWakeUp_Flg: nonqueued-receiver-com-spec{data-element=tec_BswM_CANWakeUp_Flg, filter=data-filter-type=ALWAYS, init-value=0}, required-interface=IF_BswM_CANWakeUp_Flg
      RTE_R_BswM_DcWakeUp_Flg: nonqueued-receiver-com-spec{data-element=tec_BswM_DcWakeUp_Flg, filter=data-filter-type=ALWAYS, init-value=0}, required-interface=IF_BswM_DcWakeUp_Flg
      RTE_R_BswM_KeyWakeUp_Flg: nonqueued-receiver-com-spec{data-element=tec_BswM_KeyWakeUp_Flg, filter=data-filter-type=ALWAYS, init-value=0}, required-interface=IF_BswM_KeyWakeUp_Flg
      RTE_R_BswM_LinWakeUp_Flg: nonqueued-receiver-com-spec{data-element=tec_BswM_LinWakeUp_Flg, filter=data-filter-type=ALWAYS, init-value=0}, required-interface=IF_BswM_LinWakeUp_Flg
      RTE_R_ComM_BMSBattSOCLow_Flg: nonqueued-receiver-com-spec{data-element=tec_ComM_BMSBattSOCLow_Flg, filter=data-filter-type=ALWAYS, init-value=0}, required-interface=IF_ComM_BMSBattSOCLow_Flg
      RTE_R_ComM_IBSBattSOC_pct: nonqueued-receiver-com-spec{data-element=tec_ComM_IBSBattSOC_pct, filter=data-filter-type=ALWAYS, init-value=0}, required-interface=IF_ComM_IBSBattSOC_pct
      RTE_R_ComM_IVIPrecReq_Flg: nonqueued-receiver-com-spec{data-element=tec_ComM_IVIPrecReq_Flg, filter=data-filter-type=ALWAYS, init-value=0}, required-interface=IF_ComM_IVIPrecReq_Flg
      RTE_R_ComM_IVIPreheatReq_Flg: nonqueued-receiver-com-spec{data-element=tec_ComM_IVIPreheatReq_Flg, filter=data-filter-type=ALWAYS, init-value=0}, required-interface=IF_ComM_IVIPreheatReq_Flg
      RTE_R_ComM_OBCCCSts_Enum: nonqueued-receiver-com-spec{data-element=tec_ComM_OBCCCSts_Enum, filter=data-filter-type=ALWAYS, init-value=0}, required-interface=IF_ComM_OBCCCSts_Enum
      RTE_R_ComM_PEPSPwrMod_Enum: nonqueued-receiver-com-spec{data-element=tec_ComM_PEPSPwrMod_Enum, filter=data-filter-type=ALWAYS, init-value=0}, required-interface=IF_ComM_PEPSPwrMod_Enum
      RTE_R_ComM_SGWAcReq_Flg: nonqueued-receiver-com-spec{data-element=tec_ComM_SGWAcReq_Flg, filter=data-filter-type=ALWAYS, init-value=0}, required-interface=IF_ComM_SGWAcReq_Flg
      RTE_R_ComM_SGWWakeUpReq_Flg: nonqueued-receiver-com-spec{data-element=tec_ComM_SGWWakeUpReq_Flg, filter=data-filter-type=ALWAYS, init-value=0}, required-interface=IF_ComM_SGWWakeUpReq_Flg
    behavior CtAp_WakeUpRsn_InternalBehavior
      timing event TMT_R_WakeUpRsn_Cyclic_20ms: start-on-event=R_WakeUpRsn_Cyclic_20ms, period=0.02
      init event CtAp_WakeUpRsn_InitEvent: start-on-event=R_WakeUpRsn_Init
      runnable R_WakeUpRsn_Cyclic_20ms
        data-receive-point-by-arguments:
          12 x access:
            REC_RTE_R_BswM_CANWakeUp_Flg_tec_BswM_CANWakeUp_Flg: accessed-variable=RTE_R_BswM_CANWakeUp_Flg.tec_BswM_CANWakeUp_Flg
            REC_RTE_R_BswM_DcWakeUp_Flg_tec_BswM_DcWakeUp_Flg: accessed-variable=RTE_R_BswM_DcWakeUp_Flg.tec_BswM_DcWakeUp_Flg
            REC_RTE_R_BswM_KeyWakeUp_Flg_tec_BswM_KeyWakeUp_Flg: accessed-variable=RTE_R_BswM_KeyWakeUp_Flg.tec_BswM_KeyWakeUp_Flg
            REC_RTE_R_BswM_LinWakeUp_Flg_tec_BswM_LinWakeUp_Flg: accessed-variable=RTE_R_BswM_LinWakeUp_Flg.tec_BswM_LinWakeUp_Flg
            REC_RTE_R_ComM_BMSBattSOCLow_Flg_tec_ComM_BMSBattSOCLow_Flg: accessed-variable=RTE_R_ComM_BMSBattSOCLow_Flg.tec_ComM_BMSBattSOCLow_Flg
            REC_RTE_R_ComM_IBSBattSOC_pct_tec_ComM_IBSBattSOC_pct: accessed-variable=RTE_R_ComM_IBSBattSOC_pct.tec_ComM_IBSBattSOC_pct
            REC_RTE_R_ComM_IVIPrecReq_Flg_tec_ComM_IVIPrecReq_Flg: accessed-variable=RTE_R_ComM_IVIPrecReq_Flg.tec_ComM_IVIPrecReq_Flg
            REC_RTE_R_ComM_IVIPreheatReq_Flg_tec_ComM_IVIPreheatReq_Flg: accessed-variable=RTE_R_ComM_IVIPreheatReq_Flg.tec_ComM_IVIPreheatReq_Flg
            REC_RTE_R_ComM_OBCCCSts_Enum_tec_ComM_OBCCCSts_Enum: accessed-variable=RTE_R_ComM_OBCCCSts_Enum.tec_ComM_OBCCCSts_Enum
            REC_RTE_R_ComM_PEPSPwrMod_Enum_tec_ComM_PEPSPwrMod_Enum: accessed-variable=RTE_R_ComM_PEPSPwrMod_Enum.tec_ComM_PEPSPwrMod_Enum
            REC_RTE_R_ComM_SGWAcReq_Flg_tec_ComM_SGWAcReq_Flg: accessed-variable=RTE_R_ComM_SGWAcReq_Flg.tec_ComM_SGWAcReq_Flg
            REC_RTE_R_ComM_SGWWakeUpReq_Flg_tec_ComM_SGWWakeUpReq_Flg: accessed-variable=RTE_R_ComM_SGWWakeUpReq_Flg.tec_ComM_SGWWakeUpReq_Flg
        data-send-points:
          access SEND_RTE_P_LvMgmt_WakeUpReq_Flg_tec_LvMgmt_WakeUpReq_Flg: accessed-variable=RTE_P_LvMgmt_WakeUpReq_Flg.tec_LvMgmt_WakeUpReq_Flg
          access SEND_RTE_P_LvMgmt_WakeUpSrc_Enum_tec_LvMgmt_WakeUpSrc_Enum: accessed-variable=RTE_P_LvMgmt_WakeUpSrc_Enum.tec_LvMgmt_WakeUpSrc_Enum
      runnable R_WakeUpRsn_Init
  composition sw component type CtAp_ChassisMgmt_swc
    20 x provide port:
      RTE_P_ChassisMgmt_AccrPedlDrvTq_Nm: nonqueued-sender-com-spec{data-element=tec_ChassisMgmt_AccrPedlDrvTq_Nm, init-value=0}, provided-interface=IF_ChassisMgmt_AccrPedlDrvTq_Nm
      RTE_P_ChassisMgmt_AccrPedlFltSts_Enum: nonqueued-sender-com-spec{data-element=tec_ChassisMgmt_AccrPedlFltSts_Enum, init-value=0}, provided-interface=IF_ChassisMgmt_AccrPedlFltSts_Enum
      RTE_P_ChassisMgmt_AccrPedlPosnRaw_pct: nonqueued-sender-com-spec{data-element=tec_ChassisMgmt_AccrPedlPosnRaw_pct, init-value=0}, provided-interface=IF_ChassisMgmt_AccrPedlPosnRaw_pct
      RTE_P_ChassisMgmt_AccrPedlVld_Flg: nonqueued-sender-com-spec{data-element=tec_ChassisMgmt_AccrPedlVld_Flg, init-value=0}, provided-interface=IF_ChassisMgmt_AccrPedlVld_Flg
      RTE_P_ChassisMgmt_BrkCmpSts_Enum: nonqueued-sender-com-spec{data-element=tec_ChassisMgmt_BrkCmpSts_Enum, init-value=0}, provided-interface=IF_ChassisMgmt_BrkCmpSts_Enum
      RTE_P_ChassisMgmt_BrkCtrlSts_Flg: nonqueued-sender-com-spec{data-element=tec_ChassisMgmt_BrkCtrlSts_Flg, init-value=0}, provided-interface=IF_ChassisMgmt_BrkCtrlSts_Flg
      RTE_P_ChassisMgmt_BrkFltSts_Flg: nonqueued-sender-com-spec{data-element=tec_ChassisMgmt_BrkFltSts_Flg, init-value=0}, provided-interface=IF_ChassisMgmt_BrkFltSts_Flg
      RTE_P_ChassisMgmt_CoastCtrlMCUReqSts_Enum: nonqueued-sender-com-spec{data-element=tec_ChassisMgmt_CoastCtrlMCUReqSts_Enum, init-value=0}, provided-interface=IF_ChassisMgmt_CoastCtrlMCUReqSts_Enum
      RTE_P_ChassisMgmt_DrvAsscCtrlOvrdSts_Flg: nonqueued-sender-com-spec{data-element=tec_ChassisMgmt_DrvAsscCtrlOvrdSts_Flg, init-value=0}, provided-interface=IF_ChassisMgmt_DrvAsscCtrlOvrdSts_Flg
      RTE_P_ChassisMgmt_DrvCoorDesTq_Nm: nonqueued-sender-com-spec{data-element=tec_ChassisMgmt_DrvCoorDesTq_Nm, init-value=0}, provided-interface=IF_ChassisMgmt_DrvCoorDesTq_Nm
      RTE_P_ChassisMgmt_DrvrDesTq_Nm: nonqueued-sender-com-spec{data-element=tec_ChassisMgmt_DrvrDesTq_Nm, init-value=0}, provided-interface=IF_ChassisMgmt_DrvrDesTq_Nm
      RTE_P_ChassisMgmt_IBSIntvIncTq_Nm: nonqueued-sender-com-spec{data-element=tec_ChassisMgmt_IBSIntvIncTq_Nm, init-value=0}, provided-interface=IF_ChassisMgmt_IBSIntvIncTq_Nm
      RTE_P_ChassisMgmt_IBSIntvIncTqActv_Flg: nonqueued-sender-com-spec{data-element=tec_ChassisMgmt_IBSIntvIncTqActv_Flg, init-value=0}, provided-interface=IF_ChassisMgmt_IBSIntvIncTqActv_Flg
      RTE_P_ChassisMgmt_IBSIntvRednTq_Nm: nonqueued-sender-com-spec{data-element=tec_ChassisMgmt_IBSIntvRednTq_Nm, init-value=0}, provided-interface=IF_ChassisMgmt_IBSIntvRednTq_Nm
      RTE_P_ChassisMgmt_IBSIntvRednTqActv_Flg: nonqueued-sender-com-spec{data-element=tec_ChassisMgmt_IBSIntvRednTqActv_Flg, init-value=0}, provided-interface=IF_ChassisMgmt_IBSIntvRednTqActv_Flg
      RTE_P_ChassisMgmt_IBSVlcReqTqAvl_Flg: nonqueued-sender-com-spec{data-element=tec_ChassisMgmt_IBSVlcReqTqAvl_Flg, init-value=0}, provided-interface=IF_ChassisMgmt_IBSVlcReqTqAvl_Flg
      RTE_P_ChassisMgmt_OnePedlDesDecelSpd_mps2q: nonqueued-sender-com-spec{data-element=tec_ChassisMgmt_OnePedlDesDecelSpd_mps2q, init-value=0}, provided-interface=IF_ChassisMgmt_OnePedlDesDecelSpd_mps2q
      RTE_P_ChassisMgmt_OnePedlFltSts_Flg: nonqueued-sender-com-spec{data-element=tec_ChassisMgmt_OnePedlFltSts_Flg, init-value=0}, provided-interface=IF_ChassisMgmt_OnePedlFltSts_Flg
      RTE_P_ChassisMgmt_PedlAlysDTC_16bit: nonqueued-sender-com-spec{data-element=tec_ChassisMgmt_PedlAlysDTC_16bit, init-value=0}, provided-interface=IF_ChassisMgmt_PedlAlysDTC_16bit
      RTE_P_ChassisMgmt_VehDesDecel_mps2q: nonqueued-sender-com-spec{data-element=tec_ChassisMgmt_BrkCmpDesDecel_mps2q, init-value=0}, provided-interface=IF_ChassisMgmt_VehDesDecel_mps2q
    52 x require port:
      RTE_R_ComM_EPBWrkSts_Enum: nonqueued-receiver-com-spec{data-element=tec_ComM_EPBWrkSts_Enum, filter=data-filter-type=ALWAYS, init-value=0}, required-interface=IF_ComM_EPBWrkSts_Enum
      RTE_R_ComM_IBSAbpActv_Flg: nonqueued-receiver-com-spec{data-element=tec_ComM_IBSAbpActv_Flg, filter=data-filter-type=ALWAYS, init-value=0}, required-interface=IF_ComM_IBSAbpActv_Flg
      RTE_R_ComM_IBSAebActv_Flg: nonqueued-receiver-com-spec{data-element=tec_ComM_IBSAebActv_Flg, filter=data-filter-type=ALWAYS, init-value=0}, required-interface=IF_ComM_IBSAebActv_Flg
      RTE_R_ComM_IBSApaModSts_Enum: nonqueued-receiver-com-spec{data-element=tec_ComM_IBSApaModSts_Enum, filter=data-filter-type=ALWAYS, init-value=0}, required-interface=IF_ComM_IBSApaModSts_Enum
      RTE_R_ComM_IBSApaReqTq_Nm: nonqueued-receiver-com-spec{data-element=tec_ComM_IBSApaReqTq_Nm, filter=data-filter-type=ALWAYS, init-value=0}, required-interface=IF_ComM_IBSApaReqTq_Nm
      RTE_R_ComM_IBSApaReqTqVld_Flg: nonqueued-receiver-com-spec{data-element=tec_ComM_IBSApaReqTqVld_Flg, filter=data-filter-type=ALWAYS, init-value=0}, required-interface=IF_ComM_IBSApaReqTqVld_Flg
      RTE_R_ComM_IBSBrkMstCylPrs_pct: nonqueued-receiver-com-spec{data-element=tec_ComM_IBSBrkMstCylPrs_pct, filter=data-filter-type=ALWAYS, init-value=0}, required-interface=IF_ComM_IBSBrkMstCylPrs_pct
      RTE_R_ComM_IBSBrkPlgrPrs_pct: nonqueued-receiver-com-spec{data-element=tec_ComM_IBSBrkPlgrPrs_pct, filter=data-filter-type=ALWAYS, init-value=0}, required-interface=IF_ComM_IBSBrkPlgrPrs_pct
      RTE_R_ComM_IBSBrkSts_Enum: nonqueued-receiver-com-spec{data-element=tec_ComM_IBSBrkSts_Enum, filter=data-filter-type=ALWAYS, init-value=0}, required-interface=IF_ComM_IBSBrkSts_Enum
      RTE_R_ComM_IBSDtcActv_Flg: nonqueued-receiver-com-spec{data-element=tec_ComM_IBSDtcActv_Flg, filter=data-filter-type=ALWAYS, init-value=0}, required-interface=IF_ComM_IBSDtcActv_Flg
      RTE_R_ComM_IBSDtcFlt_Flg: nonqueued-receiver-com-spec{data-element=tec_ComM_IBSDtcFlt_Flg, filter=data-filter-type=ALWAYS, init-value=0}, required-interface=IF_ComM_IBSDtcFlt_Flg
      RTE_R_ComM_IBSHdcSts_Enum: nonqueued-receiver-com-spec{data-element=tec_ComM_IBSHdcSts_Enum, filter=data-filter-type=ALWAYS, init-value=0}, required-interface=IF_ComM_IBSHdcSts_Enum
      RTE_R_ComM_IBSRbsReqTq_Nm: nonqueued-receiver-com-spec{data-element=tec_ComM_IBSRbsReqTq_Nm, filter=data-filter-type=ALWAYS, init-value=0}, required-interface=IF_ComM_IBSRbsReqTq_Nm
      RTE_R_ComM_IBSRbsReqTqVld_Flg: nonqueued-receiver-com-spec{data-element=tec_ComM_IBSRbsReqTqVld_Flg, filter=data-filter-type=ALWAYS, init-value=0}, required-interface=IF_ComM_IBSRbsReqTqVld_Flg
      RTE_R_ComM_IBSRbsSts_Enum: nonqueued-receiver-com-spec{data-element=tec_ComM_IBSRbsSts_Enum, filter=data-filter-type=ALWAYS, init-value=0}, required-interface=IF_ComM_IBSRbsSts_Enum
      RTE_R_ComM_IBSReqIncTq_Nm: nonqueued-receiver-com-spec{data-element=tec_ComM_IBSReqIncTq_Nm, filter=data-filter-type=ALWAYS, init-value=0}, required-interface=IF_ComM_IBSReqIncTq_Nm
      RTE_R_ComM_IBSReqIncTqVld_Flg: nonqueued-receiver-com-spec{data-element=tec_ComM_IBSReqIncTqVld_Flg, filter=data-filter-type=ALWAYS, init-value=0}, required-interface=IF_ComM_IBSReqIncTqVld_Flg
      RTE_R_ComM_IBSReqRednTq_Nm: nonqueued-receiver-com-spec{data-element=tec_ComM_IBSReqRednTq_Nm, filter=data-filter-type=ALWAYS, init-value=0}, required-interface=IF_ComM_IBSReqRednTq_Nm
      RTE_R_ComM_IBSReqRednTqVld_Flg: nonqueued-receiver-com-spec{data-element=tec_ComM_IBSReqRednTqVld_Flg, filter=data-filter-type=ALWAYS, init-value=0}, required-interface=IF_ComM_IBSReqRednTqVld_Flg
      RTE_R_ComM_IBSRwuActv_Flg: nonqueued-receiver-com-spec{data-element=tec_ComM_IBSRwuActv_Flg, filter=data-filter-type=ALWAYS, init-value=0}, required-interface=IF_ComM_IBSRwuActv_Flg
      RTE_R_ComM_IBSTcsActv_Flg: nonqueued-receiver-com-spec{data-element=tec_ComM_IBSTcsActv_Flg, filter=data-filter-type=ALWAYS, init-value=0}, required-interface=IF_ComM_IBSTcsActv_Flg
      RTE_R_ComM_IBSTcsFlt_Flg: nonqueued-receiver-com-spec{data-element=tec_ComM_IBSTcsFlt_Flg, filter=data-filter-type=ALWAYS, init-value=0}, required-interface=IF_ComM_IBSTcsFlt_Flg
      RTE_R_ComM_IBSVdcActv_Flg: nonqueued-receiver-com-spec{data-element=tec_ComM_IBSVdcActv_Flg, filter=data-filter-type=ALWAYS, init-value=0}, required-interface=IF_ComM_IBSVdcActv_Flg
      RTE_R_ComM_IBSVdcFlt_Flg: nonqueued-receiver-com-spec{data-element=tec_ComM_IBSVdcFlt_Flg, filter=data-filter-type=ALWAYS, init-value=0}, required-interface=IF_ComM_IBSVdcFlt_Flg
      RTE_R_ComM_IBSVlcActv_Flg: nonqueued-receiver-com-spec{data-element=tec_ComM_IBSVlcActv_Flg, filter=data-filter-type=ALWAYS, init-value=0}, required-interface=IF_ComM_IBSVlcActv_Flg
      RTE_R_ComM_IBSVlcReqTq_Nm: nonqueued-receiver-com-spec{data-element=tec_ComM_IBSVlcReqTq_Nm, filter=data-filter-type=ALWAYS, init-value=0}, required-interface=IF_ComM_IBSVlcReqTq_Nm
      RTE_R_ComM_IBSVlcReqTqVld_Flg: nonqueued-receiver-com-spec{data-element=tec_ComM_IBSVlcReqTqVld_Flg, filter=data-filter-type=ALWAYS, init-value=0}, required-interface=IF_ComM_IBSVlcReqTqVld_Flg
      RTE_R_ComM_IVIEnaBrkCmpMod_Enum: nonqueued-receiver-com-spec{data-element=tec_ComM_IVIEnaBrkCmpMod_Enum, filter=data-filter-type=ALWAYS, init-value=0}, required-interface=IF_ComM_IVIEnaBrkCmpMod_Enum
      RTE_R_Comm_IVIEnaOnePedlMod_Enum: nonqueued-receiver-com-spec{data-element=tec_ComM_IVIEnaOnePedlMod_Enum, filter=data-filter-type=ALWAYS, init-value=0}, required-interface=IF_ComM_IVIEnaOnePedlMod_Enum
      RTE_R_ErrMgmt_ChassisCtrl_8bit: nonqueued-receiver-com-spec{data-element=tec_ErrMgmt_ChassisCtrl_8bit, filter=data-filter-type=ALWAYS, init-value=0}, required-interface=IF_ErrMgmt_ChassisCtrl_8bit
      RTE_R_ErrMgmt_ComFailDTC_16bit: nonqueued-receiver-com-spec{data-element=tec_ErrMgmt_ComFailDTC_16bit, filter=data-filter-type=ALWAYS, init-value=0}, required-interface=IF_ErrMgmt_ComFailDTC_16bit
      RTE_R_GearMgmt_ActGear_Enum: nonqueued-receiver-com-spec{data-element=tec_GearMgmt_ActGear_Enum, filter=data-filter-type=ALWAYS, init-value=0}, required-interface=IF_GearMgmt_ActGear_Enum
      RTE_R_HvMgmt_MCUWrkModActSts_Enum: nonqueued-receiver-com-spec{data-element=tec_HvMgmt_MCUWrkModActSts_Enum, filter=data-filter-type=ALWAYS, init-value=0}, required-interface=IF_HvMgmt_MCUWrkModActSts_Enum
      RTE_R_IOAbs_AccrPedlMaiRaw_mV: nonqueued-receiver-com-spec{data-element=tec_IOAbs_AccrPedlMaiRaw_mV, filter=data-filter-type=ALWAYS, init-value=0}, required-interface=IF_IOAbs_AccrPedlMaiRaw_mV
      RTE_R_IOAbs_AccrPedlRdnRaw_mV: nonqueued-receiver-com-spec{data-element=tec_IOAbs_AccrPedlRdnRaw_mV, filter=data-filter-type=ALWAYS, init-value=0}, required-interface=IF_IOAbs_AccrPedlRdnRaw_mV
      RTE_R_IOAbs_BrkMaiRaw_Flg: nonqueued-receiver-com-spec{data-element=tec_IOAbs_BrkMaiRaw_Flg, filter=data-filter-type=ALWAYS, init-value=0}, required-interface=IF_IOAbs_BrkMaiRaw_Flg
      RTE_R_IOAbs_BrkRdnRaw_Flg: nonqueued-receiver-com-spec{data-element=tec_IOAbs_BrkRdnRaw_Flg, filter=data-filter-type=ALWAYS, init-value=0}, required-interface=IF_IOAbs_BrkRdnRaw_Flg
      RTE_R_LvMgmt_WakeUpSrc_Enum: nonqueued-receiver-com-spec{data-element=tec_LvMgmt_WakeUpSrc_Enum, filter=data-filter-type=ALWAYS, init-value=0}, required-interface=IF_LvMgmt_WakeUpSrc_Enum
      RTE_R_ModMgmt_ActDrvMod_Enum: nonqueued-receiver-com-spec{data-element=tec_ModMgmt_ActDrvMod_Enum, filter=data-filter-type=ALWAYS, init-value=0}, required-interface=IF_ModMgmt_ActDrvMod_Enum
      RTE_R_ModMgmt_HvSts_Enum: nonqueued-receiver-com-spec{data-element=tec_ModMgmt_HvSts_Enum, filter=data-filter-type=ALWAYS, init-value=0}, required-interface=IF_ModMgmt_HvSts_Enum
      RTE_R_TorqPahMgmt_EmacQstyMaxTq_Nm: nonqueued-receiver-com-spec{data-element=tec_TorqPahMgmt_EmacQstyMaxTq_Nm, filter=data-filter-type=ALWAYS, init-value=0}, required-interface=IF_TorqPahMgmt_EmacQstyMaxTq_Nm
      RTE_R_TorqPahMgmt_EmacQstyMinTq_Nm: nonqueued-receiver-com-spec{data-element=tec_TorqPahMgmt_EmacQstyMinTq_Nm, filter=data-filter-type=ALWAYS, init-value=0}, required-interface=IF_TorqPahMgmt_EmacQstyMinTq_Nm
      RTE_R_TorqPahMgmt_IBSIntvTqSts_Enum: nonqueued-receiver-com-spec{data-element=tec_TorqPahMgmt_IBSIntvTqSts_Enum, filter=data-filter-type=ALWAYS, init-value=0}, required-interface=IF_TorqPahMgmt_IBSIntvTqSts_Enum
      RTE_R_TorqPahMgmt_VehSpdLmtSts_Flg: nonqueued-receiver-com-spec{data-element=tec_TorqPahMgmt_VehSpdLmtSts_Flg, filter=data-filter-type=ALWAYS, init-value=0}, required-interface=IF_TorqPahMgmt_VehSpdLmtSts_Flg
      RTE_R_TorqPahMgmt_VehSpdLmtTq_Nm: nonqueued-receiver-com-spec{data-element=tec_TorqPahMgmt_VehSpdLmtTq_Nm, filter=data-filter-type=ALWAYS, init-value=0}, required-interface=IF_TorqPahMgmt_VehSpdLmtTq_Nm
      RTE_R_VehMot_Acclr2Tq_Nm: nonqueued-receiver-com-spec{data-element=tec_VehMot_Acclr2Tq_Nm, filter=data-filter-type=ALWAYS, init-value=0}, required-interface=IF_VehMot_Acclr2Tq_Nm
      RTE_R_VehMot_AcclrPrpCurr_mps2q: nonqueued-receiver-com-spec{data-element=tec_VehMot_AcclrPrpCurr_mps2q, filter=data-filter-type=ALWAYS, init-value=0}, required-interface=IF_VehMot_AcclrPrpCurr_mps2q
      RTE_R_VehMot_SlopGrd_deg: nonqueued-receiver-com-spec{data-element=tec_VehMot_SlopGrd_deg, filter=data-filter-type=ALWAYS, init-value=0}, required-interface=IF_VehMot_SlopGrd_deg
      RTE_R_VehMot_VehDirDif_Flg: nonqueued-receiver-com-spec{data-element=tec_VehMot_VehDirDif_Flg, filter=data-filter-type=ALWAYS, init-value=0}, required-interface=IF_VehMot_VehDirDif_Flg
      RTE_R_VehMot_VehDragTq_Nm: nonqueued-receiver-com-spec{data-element=tec_VehMot_VehDragTq_Nm, filter=data-filter-type=ALWAYS, init-value=0}, required-interface=IF_VehMot_VehDragTq_Nm
      RTE_R_VehMot_VehSpd_kph: nonqueued-receiver-com-spec{data-element=tec_VehMot_VehSpd_kph, filter=data-filter-type=ALWAYS, init-value=0}, required-interface=IF_VehMot_VehSpd_kph
      RTE_R_VehMot_VehSpdVld_Flg: nonqueued-receiver-com-spec{data-element=tec_VehMot_VehSpdVld_Flg, filter=data-filter-type=ALWAYS, init-value=0}, required-interface=IF_VehMot_VehSpdVld_Flg
    9 x component:
      CtAp_AccrPedlDrv: type=CtAp_AccrPedlDrv
      CtAp_BrkMgmt: type=CtAp_BrkMgmt
      CtAp_CoastCtrl: type=CtAp_CoastCtrl
      CtAp_CrpCtrl: type=CtAp_CrpCtrl
      CtAp_DrvAsscCtrl: type=CtAp_DrvAsscCtrl
      CtAp_DrvTorqCoor: type=CtAp_DrvTorqCoor
      CtAp_OnePedCtrl: type=CtAp_OnePedCtrl
      CtAp_PdlAlys: type=CtAp_PdlAlys
      CtAp_VehStabyCtrl: type=CtAp_VehStabyCtrl
    connect CtAp_AccrPedlDrv.RTE_P_ChassisMgmt_AccrPedlDrvTq_Nm -> CtAp_DrvTorqCoor.RTE_R_ChassisMgmt_AccrPedlDrvTq_Nm
    connect CtAp_BrkMgmt.RTE_P_ChassisMgmt_BrkRgnActv_Flg -> CtAp_DrvTorqCoor.RTE_R_ChassisMgmt_BrkRgnActv_Flg
    connect CtAp_BrkMgmt.RTE_P_ChassisMgmt_BrkRgnTq_Nm -> CtAp_DrvTorqCoor.RTE_R_ChassisMgmt_BrkRgnTq_Nm
    connect CtAp_CoastCtrl.RTE_P_ChassisMgmt_CoastCtrlActv_Flg -> CtAp_AccrPedlDrv.RTE_R_ChassisMgmt_CoastCtrlActv_Flg
    connect CtAp_CoastCtrl.RTE_P_ChassisMgmt_CoastCtrlTq_Nm -> CtAp_AccrPedlDrv.RTE_R_ChassisMgmt_CoastCtrlTq_Nm
    connect CtAp_CrpCtrl.RTE_P_ChassisMgmt_CrpCtrlDesTq_Nm -> CtAp_DrvTorqCoor.RTE_R_ChassisMgmt_CrpCtrlDesTq_Nm
    connect CtAp_DrvAsscCtrl.RTE_P_ChassisMgmt_DrvAsscCtrlActv_Flg -> CtAp_DrvTorqCoor.RTE_R_ChassisMgmt_DrvAsscCtrlActv_Flg
    connect CtAp_DrvAsscCtrl.RTE_P_ChassisMgmt_DrvAsscCtrlTq_Nm -> CtAp_DrvTorqCoor.RTE_R_ChassisMgmt_DrvAsscCtrlTq_Nm
    connect CtAp_DrvTorqCoor.RTE_P_ChassisMgmt_DrvDmdHiPrio_Flg -> CtAp_CrpCtrl.RTE_R_ChassisMgmt_DrvDmdHiPrio_Flg
    connect CtAp_DrvTorqCoor.RTE_P_ChassisMgmt_SpdLmtSts_Flg -> CtAp_CrpCtrl.RTE_R_ChassisMgmt_SpdLmtSts_Flg
    connect CtAp_OnePedCtrl.RTE_P_ChassisMgmt_OnePedlActv_Flg -> CtAp_DrvTorqCoor.RTE_R_ChassisMgmt_OnePedlActv_Flg
    connect CtAp_OnePedCtrl.RTE_P_ChassisMgmt_OnePedlDesTq_Nm -> CtAp_DrvTorqCoor.RTE_R_ChassisMgmt_OnePedlDesTq_Nm
    connect CtAp_PdlAlys.RTE_P_ChassisMgmt_AccrPedlPosn_pct -> CtAp_AccrPedlDrv.RTE_R_ChassisMgmt_AccrPedlPosn_pct
    connect CtAp_PdlAlys.RTE_P_ChassisMgmt_BrkSts_Flg -> CtAp_BrkMgmt.RTE_R_ChassisMgmt_BrkSts_Flg
    connect CtAp_PdlAlys.RTE_P_ChassisMgmt_AccrPedlPosn_pct -> CtAp_CoastCtrl.RTE_R_ChassisMgmt_AccrPedlPosn_pct
    connect CtAp_PdlAlys.RTE_P_ChassisMgmt_BrkPedlPosn_pct -> CtAp_CrpCtrl.RTE_R_ChassisMgmt_BrkPedlPosn_pct
    connect CtAp_PdlAlys.RTE_P_ChassisMgmt_BrkStsVld_Flg -> CtAp_CrpCtrl.RTE_R_ChassisMgmt_BrkStsVld_Flg
    connect CtAp_PdlAlys.RTE_P_ChassisMgmt_AccrPedlPosn_pct -> CtAp_OnePedCtrl.RTE_R_ChassisMgmt_AccrPedlPosn_pct
    delegate CtAp_AccrPedlDrv.RTE_P_ChassisMgmt_AccrPedlDrvTq_Nm <-> outer port CtAp_ChassisMgmt_swc/RTE_P_ChassisMgmt_AccrPedlDrvTq_Nm
    delegate CtAp_PdlAlys.RTE_P_ChassisMgmt_AccrPedlFltSts_Enum <-> outer port CtAp_ChassisMgmt_swc/RTE_P_ChassisMgmt_AccrPedlFltSts_Enum
    delegate CtAp_PdlAlys.RTE_P_ChassisMgmt_AccrPedlPosnRaw_pct <-> outer port CtAp_ChassisMgmt_swc/RTE_P_ChassisMgmt_AccrPedlPosnRaw_pct
    delegate CtAp_PdlAlys.RTE_P_ChassisMgmt_AccrPedlVld_Flg <-> outer port CtAp_ChassisMgmt_swc/RTE_P_ChassisMgmt_AccrPedlVld_Flg
    delegate CtAp_CoastCtrl.RTE_P_ChassisMgmt_BrkCmpSts_Enum <-> outer port CtAp_ChassisMgmt_swc/RTE_P_ChassisMgmt_BrkCmpSts_Enum
    delegate CtAp_DrvTorqCoor.RTE_P_ChassisMgmt_BrkCtrlSts_Flg <-> outer port CtAp_ChassisMgmt_swc/RTE_P_ChassisMgmt_BrkCtrlSts_Flg
    delegate CtAp_PdlAlys.RTE_P_ChassisMgmt_BrkFltSts_Flg <-> outer port CtAp_ChassisMgmt_swc/RTE_P_ChassisMgmt_BrkFltSts_Flg
    delegate CtAp_CoastCtrl.RTE_P_ChassisMgmt_CoastCtrlMCUReqSts_Enum <-> outer port CtAp_ChassisMgmt_swc/RTE_P_ChassisMgmt_CoastCtrlMCUReqSts_Enum
    delegate CtAp_DrvTorqCoor.RTE_P_ChassisMgmt_DrvAsscCtrlOvrdSts_Flg <-> outer port CtAp_ChassisMgmt_swc/RTE_P_ChassisMgmt_DrvAsscCtrlOvrdSts_Flg
    delegate CtAp_DrvTorqCoor.RTE_P_ChassisMgmt_DrvCoorDesTq_Nm <-> outer port CtAp_ChassisMgmt_swc/RTE_P_ChassisMgmt_DrvCoorDesTq_Nm
    delegate CtAp_DrvTorqCoor.RTE_P_ChassisMgmt_DrvrDesTq_Nm <-> outer port CtAp_ChassisMgmt_swc/RTE_P_ChassisMgmt_DrvrDesTq_Nm
    delegate CtAp_VehStabyCtrl.RTE_P_ChassisMgmt_IBSIntvIncTq_Nm <-> outer port CtAp_ChassisMgmt_swc/RTE_P_ChassisMgmt_IBSIntvIncTq_Nm
    delegate CtAp_VehStabyCtrl.RTE_P_ChassisMgmt_IBSIntvIncTqActv_Flg <-> outer port CtAp_ChassisMgmt_swc/RTE_P_ChassisMgmt_IBSIntvIncTqActv_Flg
    delegate CtAp_VehStabyCtrl.RTE_P_ChassisMgmt_IBSIntvRednTq_Nm <-> outer port CtAp_ChassisMgmt_swc/RTE_P_ChassisMgmt_IBSIntvRednTq_Nm
    delegate CtAp_VehStabyCtrl.RTE_P_ChassisMgmt_IBSIntvRednTqActv_Flg <-> outer port CtAp_ChassisMgmt_swc/RTE_P_ChassisMgmt_IBSIntvRednTqActv_Flg
    delegate CtAp_DrvAsscCtrl.RTE_P_ChassisMgmt_IBSVlcReqTqAvl_Flg <-> outer port CtAp_ChassisMgmt_swc/RTE_P_ChassisMgmt_IBSVlcReqTqAvl_Flg
    delegate CtAp_OnePedCtrl.RTE_P_ChassisMgmt_OnePedlDesDecelSpd_mps2q <-> outer port CtAp_ChassisMgmt_swc/RTE_P_ChassisMgmt_OnePedlDesDecelSpd_mps2q
    delegate CtAp_OnePedCtrl.RTE_P_ChassisMgmt_OnePedlFltSts_Flg <-> outer port CtAp_ChassisMgmt_swc/RTE_P_ChassisMgmt_OnePedlFltSts_Flg
    delegate CtAp_PdlAlys.RTE_P_ChassisMgmt_PedlAlysDTC_16bit <-> outer port CtAp_ChassisMgmt_swc/RTE_P_ChassisMgmt_PedlAlysDTC_16bit
    delegate CtAp_CoastCtrl.RTE_P_ChassisMgmt_VehDesDecel_mps2q <-> outer port CtAp_ChassisMgmt_swc/RTE_P_ChassisMgmt_VehDesDecel_mps2q
    delegate CtAp_CrpCtrl.RTE_R_ComM_EPBWrkSts_Enum <-> outer port CtAp_ChassisMgmt_swc/RTE_R_ComM_EPBWrkSts_Enum
    delegate CtAp_OnePedCtrl.RTE_R_ComM_IBSAbpActv_Flg <-> outer port CtAp_ChassisMgmt_swc/RTE_R_ComM_IBSAbpActv_Flg
    delegate CtAp_OnePedCtrl.RTE_R_ComM_IBSAebActv_Flg <-> outer port CtAp_ChassisMgmt_swc/RTE_R_ComM_IBSAebActv_Flg
    delegate CtAp_DrvAsscCtrl.RTE_R_ComM_IBSApaModSts_Enum <-> outer port CtAp_ChassisMgmt_swc/RTE_R_ComM_IBSApaModSts_Enum
    delegate CtAp_DrvAsscCtrl.RTE_R_ComM_IBSApaReqTq_Nm <-> outer port CtAp_ChassisMgmt_swc/RTE_R_ComM_IBSApaReqTq_Nm
    delegate CtAp_DrvAsscCtrl.RTE_R_ComM_IBSApaReqTqVld_Flg <-> outer port CtAp_ChassisMgmt_swc/RTE_R_ComM_IBSApaReqTqVld_Flg
    delegate CtAp_PdlAlys.RTE_R_ComM_IBSBrkMstCylPrs_pct <-> outer port CtAp_ChassisMgmt_swc/RTE_R_ComM_IBSBrkMstCylPrs_pct
    delegate CtAp_PdlAlys.RTE_R_ComM_IBSBrkPlgrPrs_pct <-> outer port CtAp_ChassisMgmt_swc/RTE_R_ComM_IBSBrkPlgrPrs_pct
    delegate CtAp_PdlAlys.RTE_R_ComM_IBSBrkSts_Enum <-> outer port CtAp_ChassisMgmt_swc/RTE_R_ComM_IBSBrkSts_Enum
    delegate CtAp_VehStabyCtrl.RTE_R_ComM_IBSDtcActv_Flg <-> outer port CtAp_ChassisMgmt_swc/RTE_R_ComM_IBSDtcActv_Flg
    delegate CtAp_VehStabyCtrl.RTE_R_ComM_IBSDtcFlt_Flg <-> outer port CtAp_ChassisMgmt_swc/RTE_R_ComM_IBSDtcFlt_Flg
    delegate CtAp_OnePedCtrl.RTE_R_ComM_IBSHdcSts_Enum <-> outer port CtAp_ChassisMgmt_swc/RTE_R_ComM_IBSHdcSts_Enum
    delegate CtAp_BrkMgmt.RTE_R_ComM_IBSRbsReqTq_Nm <-> outer port CtAp_ChassisMgmt_swc/RTE_R_ComM_IBSRbsReqTq_Nm
    delegate CtAp_BrkMgmt.RTE_R_ComM_IBSRbsReqTqVld_Flg <-> outer port CtAp_ChassisMgmt_swc/RTE_R_ComM_IBSRbsReqTqVld_Flg
    delegate CtAp_BrkMgmt.RTE_R_ComM_IBSRbsSts_Enum <-> outer port CtAp_ChassisMgmt_swc/RTE_R_ComM_IBSRbsSts_Enum
    delegate CtAp_VehStabyCtrl.RTE_R_ComM_IBSReqIncTq_Nm <-> outer port CtAp_ChassisMgmt_swc/RTE_R_ComM_IBSReqIncTq_Nm
    delegate CtAp_VehStabyCtrl.RTE_R_ComM_IBSReqIncTqVld_Flg <-> outer port CtAp_ChassisMgmt_swc/RTE_R_ComM_IBSReqIncTqVld_Flg
    delegate CtAp_VehStabyCtrl.RTE_R_ComM_IBSReqRednTq_Nm <-> outer port CtAp_ChassisMgmt_swc/RTE_R_ComM_IBSReqRednTq_Nm
    delegate CtAp_VehStabyCtrl.RTE_R_ComM_IBSReqRednTqVld_Flg <-> outer port CtAp_ChassisMgmt_swc/RTE_R_ComM_IBSReqRednTqVld_Flg
    delegate CtAp_OnePedCtrl.RTE_R_ComM_IBSRwuActv_Flg <-> outer port CtAp_ChassisMgmt_swc/RTE_R_ComM_IBSRwuActv_Flg
    delegate CtAp_VehStabyCtrl.RTE_R_ComM_IBSTcsActv_Flg <-> outer port CtAp_ChassisMgmt_swc/RTE_R_ComM_IBSTcsActv_Flg
    delegate CtAp_VehStabyCtrl.RTE_R_ComM_IBSTcsFlt_Flg <-> outer port CtAp_ChassisMgmt_swc/RTE_R_ComM_IBSTcsFlt_Flg
    delegate CtAp_VehStabyCtrl.RTE_R_ComM_IBSVdcActv_Flg <-> outer port CtAp_ChassisMgmt_swc/RTE_R_ComM_IBSVdcActv_Flg
    delegate CtAp_VehStabyCtrl.RTE_R_ComM_IBSVdcFlt_Flg <-> outer port CtAp_ChassisMgmt_swc/RTE_R_ComM_IBSVdcFlt_Flg
    delegate CtAp_DrvAsscCtrl.RTE_R_ComM_IBSVlcActv_Flg <-> outer port CtAp_ChassisMgmt_swc/RTE_R_ComM_IBSVlcActv_Flg
    delegate CtAp_DrvAsscCtrl.RTE_R_ComM_IBSVlcReqTq_Nm <-> outer port CtAp_ChassisMgmt_swc/RTE_R_ComM_IBSVlcReqTq_Nm
    delegate CtAp_DrvAsscCtrl.RTE_R_ComM_IBSVlcReqTqVld_Flg <-> outer port CtAp_ChassisMgmt_swc/RTE_R_ComM_IBSVlcReqTqVld_Flg
    delegate CtAp_CoastCtrl.RTE_R_ComM_IVIEnaBrkCmpMod_Enum <-> outer port CtAp_ChassisMgmt_swc/RTE_R_ComM_IVIEnaBrkCmpMod_Enum
    delegate CtAp_OnePedCtrl.RTE_R_ComM_IVIEnaOnePedlMod_Enum <-> outer port RTE_R_Comm_IVIEnaOnePedlMod_Enum
    delegate CtAp_AccrPedlDrv.RTE_R_ErrMgmt_ChassisCtrl_8bit <-> outer port CtAp_ChassisMgmt_swc/RTE_R_ErrMgmt_ChassisCtrl_8bit
    delegate CtAp_BrkMgmt.RTE_R_ErrMgmt_ChassisCtrl_8bit <-> outer port CtAp_ChassisMgmt_swc/RTE_R_ErrMgmt_ChassisCtrl_8bit
    delegate CtAp_CoastCtrl.RTE_R_ErrMgmt_ChassisCtrl_8bit <-> outer port CtAp_ChassisMgmt_swc/RTE_R_ErrMgmt_ChassisCtrl_8bit
    delegate CtAp_CrpCtrl.RTE_R_ErrMgmt_ChassisCtrl_8bit <-> outer port CtAp_ChassisMgmt_swc/RTE_R_ErrMgmt_ChassisCtrl_8bit
    delegate CtAp_DrvAsscCtrl.RTE_R_ErrMgmt_ChassisCtrl_8bit <-> outer port CtAp_ChassisMgmt_swc/RTE_R_ErrMgmt_ChassisCtrl_8bit
    delegate CtAp_OnePedCtrl.RTE_R_ErrMgmt_ChassisCtrl_8bit <-> outer port CtAp_ChassisMgmt_swc/RTE_R_ErrMgmt_ChassisCtrl_8bit
    delegate CtAp_VehStabyCtrl.RTE_R_ErrMgmt_ChassisCtrl_8bit <-> outer port CtAp_ChassisMgmt_swc/RTE_R_ErrMgmt_ChassisCtrl_8bit
    delegate CtAp_PdlAlys.RTE_R_ErrMgmt_ComFailDTC_16bit <-> outer port CtAp_ChassisMgmt_swc/RTE_R_ErrMgmt_ComFailDTC_16bit
    delegate CtAp_AccrPedlDrv.RTE_R_GearMgmt_ActGear_Enum <-> outer port CtAp_ChassisMgmt_swc/RTE_R_GearMgmt_ActGear_Enum
    delegate CtAp_BrkMgmt.RTE_R_GearMgmt_ActGear_Enum <-> outer port CtAp_ChassisMgmt_swc/RTE_R_GearMgmt_ActGear_Enum
    delegate CtAp_DrvAsscCtrl.RTE_R_GearMgmt_ActGear_Enum <-> outer port CtAp_ChassisMgmt_swc/RTE_R_GearMgmt_ActGear_Enum
    delegate CtAp_OnePedCtrl.RTE_R_GearMgmt_ActGear_Enum <-> outer port CtAp_ChassisMgmt_swc/RTE_R_GearMgmt_ActGear_Enum
    delegate CtAp_VehStabyCtrl.RTE_R_GearMgmt_ActGear_Enum <-> outer port CtAp_ChassisMgmt_swc/RTE_R_GearMgmt_ActGear_Enum
    delegate CtAp_CoastCtrl.RTE_R_GearMgmt_ActGear_Enum <-> outer port CtAp_ChassisMgmt_swc/RTE_R_GearMgmt_ActGear_Enum
    delegate CtAp_CrpCtrl.RTE_R_GearMgmt_ActGear_Enum <-> outer port CtAp_ChassisMgmt_swc/RTE_R_GearMgmt_ActGear_Enum
    delegate CtAp_OnePedCtrl.RTE_R_HvMgmt_MCUWrkModActSts_Enum <-> outer port CtAp_ChassisMgmt_swc/RTE_R_HvMgmt_MCUWrkModActSts_Enum
    delegate CtAp_PdlAlys.RTE_R_IOAbs_AccrPedlMaiRaw_mV <-> outer port CtAp_ChassisMgmt_swc/RTE_R_IOAbs_AccrPedlMaiRaw_mV
    delegate CtAp_PdlAlys.RTE_R_IOAbs_AccrPedlRdnRaw_mV <-> outer port CtAp_ChassisMgmt_swc/RTE_R_IOAbs_AccrPedlRdnRaw_mV
    delegate CtAp_PdlAlys.RTE_R_IOAbs_BrkMaiRaw_Flg <-> outer port CtAp_ChassisMgmt_swc/RTE_R_IOAbs_BrkMaiRaw_Flg
    delegate CtAp_PdlAlys.RTE_R_IOAbs_BrkRdnRaw_Flg <-> outer port CtAp_ChassisMgmt_swc/RTE_R_IOAbs_BrkRdnRaw_Flg
    delegate CtAp_PdlAlys.RTE_R_LvMgmt_WakeUpSrc_Enum <-> outer port CtAp_ChassisMgmt_swc/RTE_R_LvMgmt_WakeUpSrc_Enum
    delegate CtAp_AccrPedlDrv.RTE_R_ModMgmt_ActDrvMod_Enum <-> outer port CtAp_ChassisMgmt_swc/RTE_R_ModMgmt_ActDrvMod_Enum
    delegate CtAp_CoastCtrl.RTE_R_ModMgmt_ActDrvMod_Enum <-> outer port CtAp_ChassisMgmt_swc/RTE_R_ModMgmt_ActDrvMod_Enum
    delegate CtAp_OnePedCtrl.RTE_R_ModMgmt_ActDrvMod_Enum <-> outer port CtAp_ChassisMgmt_swc/RTE_R_ModMgmt_ActDrvMod_Enum
    delegate CtAp_AccrPedlDrv.RTE_R_ModMgmt_HvSts_Enum <-> outer port CtAp_ChassisMgmt_swc/RTE_R_ModMgmt_HvSts_Enum
    delegate CtAp_BrkMgmt.RTE_R_ModMgmt_HvSts_Enum <-> outer port CtAp_ChassisMgmt_swc/RTE_R_ModMgmt_HvSts_Enum
    delegate CtAp_CoastCtrl.RTE_R_ModMgmt_HvSts_Enum <-> outer port CtAp_ChassisMgmt_swc/RTE_R_ModMgmt_HvSts_Enum
    delegate CtAp_CrpCtrl.RTE_R_ModMgmt_HvSts_Enum <-> outer port CtAp_ChassisMgmt_swc/RTE_R_ModMgmt_HvSts_Enum
    delegate CtAp_DrvAsscCtrl.RTE_R_ModMgmt_HvSts_Enum <-> outer port CtAp_ChassisMgmt_swc/RTE_R_ModMgmt_HvSts_Enum
    delegate CtAp_OnePedCtrl.RTE_R_ModMgmt_HvSts_Enum <-> outer port CtAp_ChassisMgmt_swc/RTE_R_ModMgmt_HvSts_Enum
    delegate CtAp_VehStabyCtrl.RTE_R_ModMgmt_HvSts_Enum <-> outer port CtAp_ChassisMgmt_swc/RTE_R_ModMgmt_HvSts_Enum
    delegate CtAp_VehStabyCtrl.RTE_R_TorqPahMgmt_EmacQstyMaxTq_Nm <-> outer port CtAp_ChassisMgmt_swc/RTE_R_TorqPahMgmt_EmacQstyMaxTq_Nm
    delegate CtAp_VehStabyCtrl.RTE_R_TorqPahMgmt_EmacQstyMinTq_Nm <-> outer port CtAp_ChassisMgmt_swc/RTE_R_TorqPahMgmt_EmacQstyMinTq_Nm
    delegate CtAp_VehStabyCtrl.RTE_R_TorqPahMgmt_IBSIntvTqSts_Enum <-> outer port CtAp_ChassisMgmt_swc/RTE_R_TorqPahMgmt_IBSIntvTqSts_Enum
    delegate CtAp_DrvTorqCoor.RTE_R_TorqPahMgmt_VehSpdLmtSts_Flg <-> outer port CtAp_ChassisMgmt_swc/RTE_R_TorqPahMgmt_VehSpdLmtSts_Flg
    delegate CtAp_DrvTorqCoor.RTE_R_TorqPahMgmt_VehSpdLmtTq_Nm <-> outer port CtAp_ChassisMgmt_swc/RTE_R_TorqPahMgmt_VehSpdLmtTq_Nm
    delegate CtAp_CoastCtrl.RTE_R_VehMot_Acclr2Tq_Nm <-> outer port CtAp_ChassisMgmt_swc/RTE_R_VehMot_Acclr2Tq_Nm
    delegate CtAp_OnePedCtrl.RTE_R_VehMot_Acclr2Tq_Nm <-> outer port CtAp_ChassisMgmt_swc/RTE_R_VehMot_Acclr2Tq_Nm
    delegate CtAp_CoastCtrl.RTE_R_VehMot_AcclrPrpCurr_mps2q <-> outer port CtAp_ChassisMgmt_swc/RTE_R_VehMot_AcclrPrpCurr_mps2q
    delegate CtAp_OnePedCtrl.RTE_R_VehMot_AcclrPrpCurr_mps2q <-> outer port CtAp_ChassisMgmt_swc/RTE_R_VehMot_AcclrPrpCurr_mps2q
    delegate CtAp_CrpCtrl.RTE_R_VehMot_SlopGrd_deg <-> outer port CtAp_ChassisMgmt_swc/RTE_R_VehMot_SlopGrd_deg
    delegate CtAp_AccrPedlDrv.RTE_R_VehMot_VehDirDif_Flg <-> outer port CtAp_ChassisMgmt_swc/RTE_R_VehMot_VehDirDif_Flg
    delegate CtAp_CrpCtrl.RTE_R_VehMot_VehDirDif_Flg <-> outer port CtAp_ChassisMgmt_swc/RTE_R_VehMot_VehDirDif_Flg
    delegate CtAp_OnePedCtrl.RTE_R_VehMot_VehDirDif_Flg <-> outer port CtAp_ChassisMgmt_swc/RTE_R_VehMot_VehDirDif_Flg
    delegate CtAp_OnePedCtrl.RTE_R_VehMot_VehDragTq_Nm <-> outer port CtAp_ChassisMgmt_swc/RTE_R_VehMot_VehDragTq_Nm
    delegate CtAp_AccrPedlDrv.RTE_R_VehMot_VehSpd_kph <-> outer port CtAp_ChassisMgmt_swc/RTE_R_VehMot_VehSpd_kph
    delegate CtAp_BrkMgmt.RTE_R_VehMot_VehSpd_kph <-> outer port CtAp_ChassisMgmt_swc/RTE_R_VehMot_VehSpd_kph
    delegate CtAp_CoastCtrl.RTE_R_VehMot_VehSpd_kph <-> outer port CtAp_ChassisMgmt_swc/RTE_R_VehMot_VehSpd_kph
    delegate CtAp_CrpCtrl.RTE_R_VehMot_VehSpd_kph <-> outer port CtAp_ChassisMgmt_swc/RTE_R_VehMot_VehSpd_kph
    delegate CtAp_OnePedCtrl.RTE_R_VehMot_VehSpd_kph <-> outer port CtAp_ChassisMgmt_swc/RTE_R_VehMot_VehSpd_kph
    delegate CtAp_AccrPedlDrv.RTE_R_VehMot_VehSpdVld_Flg <-> outer port CtAp_ChassisMgmt_swc/RTE_R_VehMot_VehSpdVld_Flg
    delegate CtAp_CoastCtrl.RTE_R_VehMot_VehSpdVld_Flg <-> outer port CtAp_ChassisMgmt_swc/RTE_R_VehMot_VehSpdVld_Flg
    delegate CtAp_CrpCtrl.RTE_R_VehMot_VehSpdVld_Flg <-> outer port CtAp_ChassisMgmt_swc/RTE_R_VehMot_VehSpdVld_Flg
    delegate CtAp_OnePedCtrl.RTE_R_VehMot_VehSpdVld_Flg <-> outer port CtAp_ChassisMgmt_swc/RTE_R_VehMot_VehSpdVld_Flg
  composition sw component type CtAp_ChrMgmt_swc
    26 x provide port:
      RTE_P_ChgMgmt_ChrgIndcnSts_Enum: nonqueued-sender-com-spec{data-element=tec_ChgMgmt_ChrgIndcnSts_Enum, init-value=0}, provided-interface=IF_ChgMgmt_ChrgIndcnSts_Enum
      RTE_P_ChgMgmt_DchaAbortRsn_Enum: nonqueued-sender-com-spec{data-element=tec_ChgMgmt_DchaAbortRsn_Enum, init-value=0}, provided-interface=IF_ChgMgmt_DchaAbortRsn_Enum
      RTE_P_ChrgMgmt_ChrgnRemnTim_min: nonqueued-sender-com-spec{data-element=tec_ChrgMgmt_ChrgnRemnTim_min, init-value=0}, provided-interface=IF_ChrgMgmt_ChrgnRemnTim_min
      RTE_P_ChrMgmt_AcChrgCmplSts_Enum: nonqueued-sender-com-spec{data-element=tec_ChrMgmt_AcChrgCmplSts_Enum, init-value=0}, provided-interface=IF_ChrMgmt_AcChrgCmplSts_Enum
      RTE_P_ChrMgmt_BattSideSngChrgEgy_kWh: nonqueued-sender-com-spec{data-element=tec_ChrMgmt_BattSideSngChrgEgy_kWh, init-value=0}, provided-interface=IF_ChrMgmt_BattSideSngChrgEgy_kWh
      RTE_P_ChrMgmt_ChrgPwr_kW: nonqueued-sender-com-spec{data-element=tec_ChrMgmt_ChrgPwr_kW, init-value=0}, provided-interface=IF_ChrMgmt_ChrgPwr_kW
      RTE_P_ChrMgmt_ChrgSts_Enum: nonqueued-sender-com-spec{data-element=tec_ChrMgmt_ChrgSts_Enum, init-value=0}, provided-interface=IF_ChrMgmt_ChrgSts_Enum
      RTE_P_ChrMgmt_ChrgStsErrDTC_8bit: nonqueued-sender-com-spec{data-element=tec_ChrMgmt_ChrgStsErrDTC_8bit, init-value=0}, provided-interface=IF_ChrMgmt_ChrgStsErrDTC_8bit
      RTE_P_ChrMgmt_ChrgTim_min: nonqueued-sender-com-spec{data-element=tec_ChrMgmt_ChrgTim_min, init-value=0}, provided-interface=IF_ChrMgmt_ChrgTim_min
      RTE_P_ChrMgmt_DcChrgAllwd_Flg: nonqueued-sender-com-spec{data-element=tec_ChrMgmt_DcChrgAllwd_Flg, init-value=0}, provided-interface=IF_ChrMgmt_DcChrgAllwd_Flg
      RTE_P_ChrMgmt_DcChrgCmplSts_Enum: nonqueued-sender-com-spec{data-element=tec_ChrMgmt_DcChrgCmplSts_Enum, init-value=0}, provided-interface=IF_ChrMgmt_DcChrgCmplSts_Enum
      RTE_P_ChrMgmt_DcChrgrSideSngChrgEgy_kWh: nonqueued-sender-com-spec{data-element=tec_ChrMgmt_DcChrgrSideSngChrgEgy_kWh, init-value=0}, provided-interface=IF_ChrMgmt_DcChrgrSideSngChrgEgy_kWh
      RTE_P_ChrMgmt_KeepWrm_Flg: nonqueued-sender-com-spec{data-element=tec_ChrMgmt_KeepWrm_Flg, init-value=0}, provided-interface=IF_ChrMgmt_KeepWrm_Flg
      RTE_P_ChrMgmt_NegRlyOpenReq_Flg: nonqueued-sender-com-spec{data-element=tec_ChrMgmt_NegRlyOpenReq_Flg, init-value=0}, provided-interface=IF_ChrMgmt_NegRlyOpenReq_Flg
      RTE_P_ChrMgmt_OBCCtrlMdlSts_Enum: nonqueued-sender-com-spec{data-element=tec_ChrMgmt_OBCCtrlMdlSts_Enum, init-value=0}, provided-interface=IF_ChrMgmt_OBCCtrlMdlSts_Enum
      RTE_P_ChrMgmt_OBCEnaAllwd_Flg: nonqueued-sender-com-spec{data-element=tec_ChrMgmt_OBCEnaAllwd_Flg, init-value=0}, provided-interface=IF_ChrMgmt_OBCEnaAllwd_Flg
      RTE_P_ChrMgmt_OBCSideSngChrgEgy_kWh: nonqueued-sender-com-spec{data-element=tec_ChrMgmt_OBCSideSngChrgEgy_kWh, init-value=0}, provided-interface=IF_ChrMgmt_OBCSideSngChrgEgy_kWh
      RTE_P_ChrMgmt_OBCSideSngDchaEgy_kWh: nonqueued-sender-com-spec{data-element=tec_ChrMgmt_OBCSideSngDchaEgy_kWh, init-value=0}, provided-interface=IF_ChrMgmt_OBCSideSngDchaEgy_kWh
      RTE_P_ChrMgmt_PlugSts_Enum: nonqueued-sender-com-spec{data-element=tec_ChrMgmt_PlugSts_Enum, init-value=0}, provided-interface=IF_ChrMgmt_PlugSts_Enum
      RTE_P_ChrMgmt_PODSideSngChrgEgy_kWh: nonqueued-sender-com-spec{data-element=tec_ChrMgmt_PODSideSngChrgEgy_kWh, init-value=0}, provided-interface=IF_ChrMgmt_PODSideSngChrgEgy_kWh
      RTE_P_ChrMgmt_PreheatPODDiReq_Flg: nonqueued-sender-com-spec{data-element=tec_ChrMgmt_PreheatPODDiReq_Flg, init-value=0}, provided-interface=IF_ChrMgmt_PreheatPODDiReq_Flg
      RTE_P_ChrMgmt_PreheatSts_Enum: nonqueued-sender-com-spec{data-element=tec_ChrMgmt_PreheatSts_Enum, init-value=0}, provided-interface=IF_ChrMgmt_PreheatSts_Enum
      RTE_P_ChrMgmt_ReqHvRdy_Flg: nonqueued-sender-com-spec{data-element=tec_ChrMgmt_ReqHvRdy_Flg, init-value=0}, provided-interface=IF_ChrMgmt_ReqHvRdy_Flg
      RTE_P_ChrMgmt_VCUCalcdPODIDc_A: nonqueued-sender-com-spec{data-element=tec_ChrMgmt_VCUCalcdPODIDc_A, init-value=0}, provided-interface=IF_ChrMgmt_VCUCalcdPODIDc_A
      RTE_P_ChrMgmt_VCUDispChrgI_A: nonqueued-sender-com-spec{data-element=tec_ChrMgmt_VCUDispChrgI_A, init-value=0}, provided-interface=IF_ChrMgmt_VCUDispChrgI_A
      RTE_P_ChrMgmt_VCUDispChrgU_V: nonqueued-sender-com-spec{data-element=tec_ChrMgmt_VCUDispChrgU_V, init-value=0}, provided-interface=IF_ChrMgmt_VCUDispChrgU_V
    46 x require port:
      RTE_R_ComM_AcChrgPha_Enum: nonqueued-receiver-com-spec{data-element=tec_ComM_AcChrgPha_Enum, filter=data-filter-type=ALWAYS, init-value=0}, required-interface=IF_ComM_AcChrgPha_Enum
      RTE_R_ComM_ApptChrgMdlSts_Enum: nonqueued-receiver-com-spec{data-element=tec_ComM_ApptChrgMdlSts_Enum, filter=data-filter-type=ALWAYS, init-value=0}, required-interface=IF_ComM_ApptChrgMdlSts_Enum
      RTE_R_ComM_BattMaxTemp_C: nonqueued-receiver-com-spec{data-element=tec_ComM_BMSBattMaxTemp_C, filter=data-filter-type=ALWAYS, init-value=0}, required-interface=IF_ComM_BattMaxTemp_C
      RTE_R_ComM_BattMinTemp_C: nonqueued-receiver-com-spec{data-element=tec_ComM_BMSBattMinTemp_C, filter=data-filter-type=ALWAYS, init-value=0}, required-interface=IF_ComM_BattMinTemp_C
      RTE_R_ComM_BMSBattDispSOC_pct: nonqueued-receiver-com-spec{data-element=tec_ComM_BMSBattDispSOC_pct, filter=data-filter-type=ALWAYS, init-value=0}, required-interface=IF_ComM_BMSBattDispSOC_pct
      RTE_R_ComM_BMSBattIDc_A: nonqueued-receiver-com-spec{data-element=tec_ComM_BMSBattIDc_A, filter=data-filter-type=ALWAYS, init-value=0}, required-interface=IF_ComM_BMSBattIDc_A
      RTE_R_ComM_BMSBattLnkUDc_V: nonqueued-receiver-com-spec{data-element=tec_ComM_BMSBattLnkUDc_V, filter=data-filter-type=ALWAYS, init-value=0}, required-interface=IF_ComM_BMSBattLnkUDc_V
      RTE_R_ComM_BMSBattPckUDc_V: nonqueued-receiver-com-spec{data-element=tec_ComM_BMSBattPckUDc_V, filter=data-filter-type=ALWAYS, init-value=0}, required-interface=IF_ComM_BMSBattPckUDc_V
      RTE_R_ComM_BMSBattRateCp_Ah: nonqueued-receiver-com-spec{data-element=tec_ComM_BMSBattRateCp_Ah, filter=data-filter-type=ALWAYS, init-value=0}, required-interface=IF_ComM_BMSBattRateCp_Ah
      RTE_R_ComM_BMSBattUDc_V: nonqueued-receiver-com-spec{data-element=tec_ComM_BMSBattUDc_V, filter=data-filter-type=ALWAYS, init-value=0}, required-interface=IF_ComM_BMSBattUDc_V
      RTE_R_ComM_BMSChrgCmplSts_Enum: nonqueued-receiver-com-spec{data-element=tec_ComM_BMSChrgCmplSts_Enum, filter=data-filter-type=ALWAYS, init-value=0}, required-interface=IF_ComM_BMSChrgCmplSts_Enum
      RTE_R_ComM_BMSChrgReqSts_Enum: nonqueued-receiver-com-spec{data-element=tec_ComM_BMSChrgReqSts_Enum, filter=data-filter-type=ALWAYS, init-value=0}, required-interface=IF_ComM_BMSChrgReqSts_Enum
      RTE_R_ComM_BMSChrgSts_Enum: nonqueued-receiver-com-spec{data-element=tec_ComM_BMSChrgSts_Enum, filter=data-filter-type=ALWAYS, init-value=0}, required-interface=IF_ComM_BMSChrgSts_Enum
      RTE_R_ComM_BMSKeepWrmReq_Enum: nonqueued-receiver-com-spec{data-element=tec_ComM_BMSKeepWrmReq_Enum, filter=data-filter-type=ALWAYS, init-value=0}, required-interface=IF_ComM_BMSKeepWrmReq_Enum
      RTE_R_ComM_BMSRemnChrgTim_min: nonqueued-receiver-com-spec{data-element=tec_ComM_BMSRemnChrgTim_min, filter=data-filter-type=ALWAYS, init-value=0}, required-interface=IF_ComM_BMSRemnChrgTim_min
      RTE_R_ComM_CCSOutpIDc_A: nonqueued-receiver-com-spec{data-element=tec_ComM_CCSOutpIDc_A, filter=data-filter-type=ALWAYS, init-value=0}, required-interface=IF_ComM_CCSOutpIDc_A
      RTE_R_ComM_CCSOutpUDc_V: nonqueued-receiver-com-spec{data-element=tec_ComM_CCSOutpUDc_V, filter=data-filter-type=ALWAYS, init-value=0}, required-interface=IF_ComM_CCSOutpUDc_V
      RTE_R_ComM_CMLMaxOutpIDc_A: nonqueued-receiver-com-spec{data-element=tec_ComM_CMLMaxOutpIDc_A, filter=data-filter-type=ALWAYS, init-value=0}, required-interface=IF_ComM_CMLMaxOutpIDc_A
      RTE_R_ComM_DchaSwtSts_Enum: nonqueued-receiver-com-spec{data-element=tec_ComM_DchaSwtSts_Enum, filter=data-filter-type=ALWAYS, init-value=0}, required-interface=IF_ComM_DchaSwtSts_Enum
      RTE_R_ComM_IVIChrgCmd_Enum: nonqueued-receiver-com-spec{data-element=tec_ComM_IVIChrgCmd_Enum, filter=data-filter-type=ALWAYS, init-value=0}, required-interface=IF_ComM_IVIChrgCmd_Enum
      RTE_R_ComM_MaxChrgSOCSet_Enum: nonqueued-receiver-com-spec{data-element=tec_ComM_MaxChrgSOCSet_Enum, filter=data-filter-type=ALWAYS, init-value=0}, required-interface=IF_ComM_MaxChrgSOCSet_Enum
      RTE_R_ComM_MinDchaSOCSet_Enum: nonqueued-receiver-com-spec{data-element=tec_ComM_MinDchaSOCSet_Enum, filter=data-filter-type=ALWAYS, init-value=0}, required-interface=IF_ComM_MinDchaSOCSet_Enum
      RTE_R_ComM_OBCCCSts_Enum: nonqueued-receiver-com-spec{data-element=tec_ComM_OBCCCSts_Enum, filter=data-filter-type=ALWAYS, init-value=0}, required-interface=IF_ComM_OBCCCSts_Enum
      RTE_R_ComM_OBCCPSts_Enum: nonqueued-receiver-com-spec{data-element=tec_ComM_OBCCPSts_Enum, filter=data-filter-type=ALWAYS, init-value=0}, required-interface=IF_ComM_OBCCPSts_Enum
      RTE_R_ComM_OBCInpIAc_A: nonqueued-receiver-com-spec{data-element=tec_ComM_OBCInpIAc_A, filter=data-filter-type=ALWAYS, init-value=0}, required-interface=IF_ComM_OBCInpIAc_A
      RTE_R_ComM_OBCInpUAc_V: nonqueued-receiver-com-spec{data-element=tec_ComM_OBCInpUAc_V, filter=data-filter-type=ALWAYS, init-value=0}, required-interface=IF_ComM_OBCInpUAc_V
      RTE_R_ComM_OBCOutpIDc_A: nonqueued-receiver-com-spec{data-element=tec_ComM_OBCOutpIDc_A, filter=data-filter-type=ALWAYS, init-value=0}, required-interface=IF_ComM_OBCOutpIDc_A
      RTE_R_ComM_OBCOutpUDc_V: nonqueued-receiver-com-spec{data-element=tec_ComM_OBCOutpUDc_V, filter=data-filter-type=ALWAYS, init-value=0}, required-interface=IF_ComM_OBCOutpUDc_V
      RTE_R_ComM_PEPSPwrMod_Enum: nonqueued-receiver-com-spec{data-element=tec_ComM_PEPSPwrMod_Enum, filter=data-filter-type=ALWAYS, init-value=0}, required-interface=IF_ComM_PEPSPwrMod_Enum
      RTE_R_ComM_PODDCFCUDc_V: nonqueued-receiver-com-spec{data-element=tec_ComM_PODDCFCUDc_V, filter=data-filter-type=ALWAYS, init-value=0}, required-interface=IF_ComM_PODDCFCUDc_V
      RTE_R_ComM_SGWChrgCmd_Enum: nonqueued-receiver-com-spec{data-element=tec_ComM_SGWChrgCmd_Enum, filter=data-filter-type=ALWAYS, init-value=0}, required-interface=IF_ComM_SGWChrgCmd_Enum
      RTE_R_ComM_SysIRVal_kOhm: nonqueued-receiver-com-spec{data-element=tec_ComM_SysIRVal_kOhm, filter=data-filter-type=ALWAYS, init-value=0}, required-interface=IF_ComM_SysIRVal_kOhm
      RTE_R_DCChrMgmt_DcChrgnMod_Enum: nonqueued-receiver-com-spec{data-element=tec_DCChrMgmt_DcChrgnMod_Enum, filter=data-filter-type=ALWAYS, init-value=0}, required-interface=IF_DCChrMgmt_DcChrgnMod_Enum
      RTE_R_DCChrMgmt_DcChrgnSts_Enum: nonqueued-receiver-com-spec{data-element=tec_DCChrMgmt_DcChrgnSts_Enum, filter=data-filter-type=ALWAYS, init-value=0}, required-interface=IF_DCChrMgmt_DcChrgnSts_Enum
      RTE_R_EgyMgmt_BattChrgIDcLmt_A: nonqueued-receiver-com-spec{data-element=tec_EgyMgmt_BattChrgIDcLmt_A, filter=data-filter-type=ALWAYS, init-value=0}, required-interface=IF_EgyMgmt_BattChrgIDcLmt_A
      RTE_R_EgyMgmt_DCDCPwrCnsCalcn_Kw: nonqueued-receiver-com-spec{data-element=tec_EgyMgmt_DCDCPwrCnsCalcn_Kw, filter=data-filter-type=ALWAYS, init-value=0}, required-interface=IF_EgyMgmt_DCDCPwrCnsCalcn_Kw
      RTE_R_EgyMgmt_PackPTCPwrCnsCalcn_Kw: nonqueued-receiver-com-spec{data-element=tec_EgyMgmt_PackPTCPwrCnsCalcn_Kw, filter=data-filter-type=ALWAYS, init-value=0}, required-interface=IF_EgyMgmt_PackPTCPwrCnsCalcn_Kw
      RTE_R_EgyMgmt_TCUPwrCnsCalcn_Kw: nonqueued-receiver-com-spec{data-element=tec_EgyMgmt_TCUPwrCnsCalcn_Kw, filter=data-filter-type=ALWAYS, init-value=0}, required-interface=IF_EgyMgmt_TCUPwrCnsCalcn_Kw
      RTE_R_ErrMgmt_ChrgCtrl_8bit: nonqueued-receiver-com-spec{data-element=tec_ErrMgmt_ChrgCtrl_8bit, filter=data-filter-type=ALWAYS, init-value=0}, required-interface=IF_ErrMgmt_ChrgCtrl_8bit
      RTE_R_GearMgmt_ActGear_Enum: nonqueued-receiver-com-spec{data-element=tec_GearMgmt_ActGear_Enum, filter=data-filter-type=ALWAYS, init-value=0}, required-interface=IF_GearMgmt_ActGear_Enum
      RTE_R_HvMgmt_DCDCWrkModActSts_Enum: nonqueued-receiver-com-spec{data-element=tec_HvMgmt_DCDCWrkModActSts_Enum, filter=data-filter-type=ALWAYS, init-value=0}, required-interface=IF_HvMgmt_DCDCWrkModActSts_Enum
      RTE_R_IOAbs_CC2SigUDc_mV: nonqueued-receiver-com-spec{data-element=tec_IOAbs_CC2SigUDc_mV, filter=data-filter-type=ALWAYS, init-value=0}, required-interface=IF_IOAbs_CC2SigUDc_mV
      RTE_R_ModMgmt_HvSts_Enum: nonqueued-receiver-com-spec{data-element=tec_ModMgmt_HvSts_Enum, filter=data-filter-type=ALWAYS, init-value=0}, required-interface=IF_ModMgmt_HvSts_Enum
      RTE_R_OBCMgmt_AcChrgnSts_Enum: nonqueued-receiver-com-spec{data-element=tec_OBCMgmt_AcChrgnSts_Enum, filter=data-filter-type=ALWAYS, init-value=0}, required-interface=IF_OBCMgmt_AcChrgnSts_Enum
      RTE_R_OBCMgmt_OBCOutpCpbyIDc_A: nonqueued-receiver-com-spec{data-element=tec_OBCMgmt_OBCOutpCpbyIDc_A, filter=data-filter-type=ALWAYS, init-value=0}, required-interface=IF_OBCMgmt_OBCOutpCpbyIDc_A
      RTE_R_VehMot_VehSpd_kph: nonqueued-receiver-com-spec{data-element=tec_VehMot_VehSpd_kph, filter=data-filter-type=ALWAYS, init-value=0}, required-interface=IF_VehMot_VehSpd_kph
    4 x component:
      CtAp_ChrgEgyCal: type=CtAp_ChrgEgyCal
      CtAp_ChrgPreHeat: type=CtAp_ChrgPreHeat
      CtAp_ChrgSdl: type=CtAp_ChrgSdl
      CtAp_ChrgStat: type=CtAp_ChrgStat
    connect CtAp_ChrgEgyCal.RTE_P_ChrMgmt_VCUCalcdPODIDc_A -> CtAp_ChrgStat.RTE_R_ChrMgmt_VCUCalcdPODIDc_A
    connect CtAp_ChrgPreHeat.RTE_P_ChrMgmt_PreheatSts_Enum -> CtAp_ChrgStat.RTE_R_ChrMgmt_PreheatSts_Enum
    connect CtAp_ChrgStat.RTE_P_ChrMgmt_ChrgSts_Enum -> CtAp_ChrgEgyCal.RTE_R_ChrMgmt_ChrgSts_Enum
    connect CtAp_ChrgStat.RTE_P_ChrMgmt_ChrgSts_Enum -> CtAp_ChrgPreHeat.RTE_R_ChrMgmt_ChrgSts_Enum
    connect CtAp_ChrgStat.RTE_P_ChrMgmt_ChrgSts_Enum -> CtAp_ChrgSdl.RTE_R_ChrMgmt_ChrgSts_Enum
    delegate CtAp_ChrgStat.RTE_P_ChgMgmt_ChrgIndcnSts_Enum <-> outer port CtAp_ChrMgmt_swc/RTE_P_ChgMgmt_ChrgIndcnSts_Enum
    delegate CtAp_ChrgStat.RTE_P_ChgMgmt_DchaAbortRsn_Enum <-> outer port CtAp_ChrMgmt_swc/RTE_P_ChgMgmt_DchaAbortRsn_Enum
    delegate CtAp_ChrgSdl.RTE_P_ChrgMgmt_ChrgnRemnTim_min <-> outer port CtAp_ChrMgmt_swc/RTE_P_ChrgMgmt_ChrgnRemnTim_min
    delegate CtAp_ChrgStat.RTE_P_ChrMgmt_AcChrgCmplSts_Enum <-> outer port CtAp_ChrMgmt_swc/RTE_P_ChrMgmt_AcChrgCmplSts_Enum
    delegate CtAp_ChrgEgyCal.RTE_P_ChrMgmt_BattSideSngChrgEgy_kWh <-> outer port CtAp_ChrMgmt_swc/RTE_P_ChrMgmt_BattSideSngChrgEgy_kWh
    delegate CtAp_ChrgEgyCal.RTE_P_ChrMgmt_ChrgPwr_kW <-> outer port CtAp_ChrMgmt_swc/RTE_P_ChrMgmt_ChrgPwr_kW
    delegate CtAp_ChrgStat.RTE_P_ChrMgmt_ChrgSts_Enum <-> outer port CtAp_ChrMgmt_swc/RTE_P_ChrMgmt_ChrgSts_Enum
    delegate CtAp_ChrgStat.RTE_P_ChrMgmt_ChrgStsErrDTC_8bit <-> outer port CtAp_ChrMgmt_swc/RTE_P_ChrMgmt_ChrgStsErrDTC_8bit
    delegate CtAp_ChrgSdl.RTE_P_ChrMgmt_ChrgTim_min <-> outer port CtAp_ChrMgmt_swc/RTE_P_ChrMgmt_ChrgTim_min
    delegate CtAp_ChrgStat.RTE_P_ChrMgmt_DcChrgAllwd_Flg <-> outer port CtAp_ChrMgmt_swc/RTE_P_ChrMgmt_DcChrgAllwd_Flg
    delegate CtAp_ChrgStat.RTE_P_ChrMgmt_DcChrgCmplSts_Enum <-> outer port CtAp_ChrMgmt_swc/RTE_P_ChrMgmt_DcChrgCmplSts_Enum
    delegate CtAp_ChrgEgyCal.RTE_P_ChrMgmt_DcChrgrSideSngChrgEgy_kWh <-> outer port CtAp_ChrMgmt_swc/RTE_P_ChrMgmt_DcChrgrSideSngChrgEgy_kWh
    delegate CtAp_ChrgStat.RTE_P_ChrMgmt_KeepWrm_Flg <-> outer port CtAp_ChrMgmt_swc/RTE_P_ChrMgmt_KeepWrm_Flg
    delegate CtAp_ChrgPreHeat.RTE_P_ChrMgmt_NegRlyOpenReq_Flg <-> outer port CtAp_ChrMgmt_swc/RTE_P_ChrMgmt_NegRlyOpenReq_Flg
    delegate CtAp_ChrgStat.RTE_P_ChrMgmt_OBCCtrlMdlSts_Enum <-> outer port CtAp_ChrMgmt_swc/RTE_P_ChrMgmt_OBCCtrlMdlSts_Enum
    delegate CtAp_ChrgStat.RTE_P_ChrMgmt_OBCEnaAllwd_Flg <-> outer port CtAp_ChrMgmt_swc/RTE_P_ChrMgmt_OBCEnaAllwd_Flg
    delegate CtAp_ChrgEgyCal.RTE_P_ChrMgmt_OBCSideSngChrgEgy_kWh <-> outer port CtAp_ChrMgmt_swc/RTE_P_ChrMgmt_OBCSideSngChrgEgy_kWh
    delegate CtAp_ChrgEgyCal.RTE_P_ChrMgmt_OBCSideSngDchaEgy_kWh <-> outer port CtAp_ChrMgmt_swc/RTE_P_ChrMgmt_OBCSideSngDchaEgy_kWh
    delegate CtAp_ChrgStat.RTE_P_ChrMgmt_PlugSts_Enum <-> outer port CtAp_ChrMgmt_swc/RTE_P_ChrMgmt_PlugSts_Enum
    delegate CtAp_ChrgEgyCal.RTE_P_ChrMgmt_PODSideSngChrgEgy_kWh <-> outer port CtAp_ChrMgmt_swc/RTE_P_ChrMgmt_PODSideSngChrgEgy_kWh
    delegate CtAp_ChrgPreHeat.RTE_P_ChrMgmt_PreheatPODDiReq_Flg <-> outer port CtAp_ChrMgmt_swc/RTE_P_ChrMgmt_PreheatPODDiReq_Flg
    delegate CtAp_ChrgPreHeat.RTE_P_ChrMgmt_PreheatSts_Enum <-> outer port CtAp_ChrMgmt_swc/RTE_P_ChrMgmt_PreheatSts_Enum
    delegate CtAp_ChrgStat.RTE_P_ChrMgmt_ReqHvRdy_Flg <-> outer port CtAp_ChrMgmt_swc/RTE_P_ChrMgmt_ReqHvRdy_Flg
    delegate CtAp_ChrgEgyCal.RTE_P_ChrMgmt_VCUCalcdPODIDc_A <-> outer port CtAp_ChrMgmt_swc/RTE_P_ChrMgmt_VCUCalcdPODIDc_A
    delegate CtAp_ChrgEgyCal.RTE_P_ChrMgmt_VCUDispChrgI_A <-> outer port CtAp_ChrMgmt_swc/RTE_P_ChrMgmt_VCUDispChrgI_A
    delegate CtAp_ChrgEgyCal.RTE_P_ChrMgmt_VCUDispChrgU_V <-> outer port CtAp_ChrMgmt_swc/RTE_P_ChrMgmt_VCUDispChrgU_V
    delegate CtAp_ChrgEgyCal.RTE_R_ComM_AcChrgPha_Enum <-> outer port CtAp_ChrMgmt_swc/RTE_R_ComM_AcChrgPha_Enum
    delegate CtAp_ChrgStat.RTE_R_ComM_ApptChrgMdlSts_Enum <-> outer port CtAp_ChrMgmt_swc/RTE_R_ComM_ApptChrgMdlSts_Enum
    delegate CtAp_ChrgSdl.RTE_R_ComM_BattMaxTemp_C <-> outer port CtAp_ChrMgmt_swc/RTE_R_ComM_BattMaxTemp_C
    delegate CtAp_ChrgSdl.RTE_R_ComM_BattMinTemp_C <-> outer port CtAp_ChrMgmt_swc/RTE_R_ComM_BattMinTemp_C
    delegate CtAp_ChrgSdl.RTE_R_ComM_BMSBattDispSOC_pct <-> outer port CtAp_ChrMgmt_swc/RTE_R_ComM_BMSBattDispSOC_pct
    delegate CtAp_ChrgStat.RTE_R_ComM_BMSBattDispSOC_pct <-> outer port CtAp_ChrMgmt_swc/RTE_R_ComM_BMSBattDispSOC_pct
    delegate CtAp_ChrgEgyCal.RTE_R_ComM_BMSBattIDc_A <-> outer port CtAp_ChrMgmt_swc/RTE_R_ComM_BMSBattIDc_A
    delegate CtAp_ChrgPreHeat.RTE_R_ComM_BMSBattIDc_A <-> outer port CtAp_ChrMgmt_swc/RTE_R_ComM_BMSBattIDc_A
    delegate CtAp_ChrgEgyCal.RTE_R_ComM_BMSBattLnkUDc_V <-> outer port CtAp_ChrMgmt_swc/RTE_R_ComM_BMSBattLnkUDc_V
    delegate CtAp_ChrgPreHeat.RTE_R_ComM_BMSBattPckUDc_V <-> outer port CtAp_ChrMgmt_swc/RTE_R_ComM_BMSBattPckUDc_V
    delegate CtAp_ChrgSdl.RTE_R_ComM_BMSBattRateCp_Ah <-> outer port CtAp_ChrMgmt_swc/RTE_R_ComM_BMSBattRateCp_Ah
    delegate CtAp_ChrgEgyCal.RTE_R_ComM_BMSBattUDc_V <-> outer port CtAp_ChrMgmt_swc/RTE_R_ComM_BMSBattUDc_V
    delegate CtAp_ChrgStat.RTE_R_ComM_BMSChrgCmplSts_Enum <-> outer port CtAp_ChrMgmt_swc/RTE_R_ComM_BMSChrgCmplSts_Enum
    delegate CtAp_ChrgStat.RTE_R_ComM_BMSChrgReqSts_Enum <-> outer port CtAp_ChrMgmt_swc/RTE_R_ComM_BMSChrgReqSts_Enum
    delegate CtAp_ChrgPreHeat.RTE_R_ComM_BMSChrgSts_Enum <-> outer port CtAp_ChrMgmt_swc/RTE_R_ComM_BMSChrgSts_Enum
    delegate CtAp_ChrgStat.RTE_R_ComM_BMSChrgSts_Enum <-> outer port CtAp_ChrMgmt_swc/RTE_R_ComM_BMSChrgSts_Enum
    delegate CtAp_ChrgStat.RTE_R_ComM_BMSKeepWrmReq_Enum <-> outer port CtAp_ChrMgmt_swc/RTE_R_ComM_BMSKeepWrmReq_Enum
    delegate CtAp_ChrgSdl.RTE_R_ComM_BMSRemnChrgTim_min <-> outer port CtAp_ChrMgmt_swc/RTE_R_ComM_BMSRemnChrgTim_min
    delegate CtAp_ChrgEgyCal.RTE_R_ComM_CCSOutpIDc_A <-> outer port CtAp_ChrMgmt_swc/RTE_R_ComM_CCSOutpIDc_A
    delegate CtAp_ChrgEgyCal.RTE_R_ComM_CCSOutpUDc_V <-> outer port CtAp_ChrMgmt_swc/RTE_R_ComM_CCSOutpUDc_V
    delegate CtAp_ChrgSdl.RTE_R_ComM_CMLMaxOutpIDc_A <-> outer port CtAp_ChrMgmt_swc/RTE_R_ComM_CMLMaxOutpIDc_A
    delegate CtAp_ChrgStat.RTE_R_ComM_DchaSwtSts_Enum <-> outer port CtAp_ChrMgmt_swc/RTE_R_ComM_DchaSwtSts_Enum
    delegate CtAp_ChrgStat.RTE_R_ComM_IVIChrgCmd_Enum <-> outer port CtAp_ChrMgmt_swc/RTE_R_ComM_IVIChrgCmd_Enum
    delegate CtAp_ChrgStat.RTE_R_ComM_MaxChrgSOCSet_Enum <-> outer port CtAp_ChrMgmt_swc/RTE_R_ComM_MaxChrgSOCSet_Enum
    delegate CtAp_ChrgStat.RTE_R_ComM_MinDchaSOCSet_Enum <-> outer port CtAp_ChrMgmt_swc/RTE_R_ComM_MinDchaSOCSet_Enum
    delegate CtAp_ChrgStat.RTE_R_ComM_OBCCCSts_Enum <-> outer port CtAp_ChrMgmt_swc/RTE_R_ComM_OBCCCSts_Enum
    delegate CtAp_ChrgStat.RTE_R_ComM_OBCCPSts_Enum <-> outer port CtAp_ChrMgmt_swc/RTE_R_ComM_OBCCPSts_Enum
    delegate CtAp_ChrgEgyCal.RTE_R_ComM_OBCInpIAc_A <-> outer port CtAp_ChrMgmt_swc/RTE_R_ComM_OBCInpIAc_A
    delegate CtAp_ChrgEgyCal.RTE_R_ComM_OBCInpUAc_V <-> outer port CtAp_ChrMgmt_swc/RTE_R_ComM_OBCInpUAc_V
    delegate CtAp_ChrgEgyCal.RTE_R_ComM_OBCOutpIDc_A <-> outer port CtAp_ChrMgmt_swc/RTE_R_ComM_OBCOutpIDc_A
    delegate CtAp_ChrgStat.RTE_R_ComM_OBCOutpIDc_A <-> outer port CtAp_ChrMgmt_swc/RTE_R_ComM_OBCOutpIDc_A
    delegate CtAp_ChrgEgyCal.RTE_R_ComM_OBCOutpUDc_V <-> outer port CtAp_ChrMgmt_swc/RTE_R_ComM_OBCOutpUDc_V
    delegate CtAp_ChrgPreHeat.RTE_R_ComM_OBCOutpUDc_V <-> outer port CtAp_ChrMgmt_swc/RTE_R_ComM_OBCOutpUDc_V
    delegate CtAp_ChrgStat.RTE_R_ComM_PEPSPwrMod_Enum <-> outer port CtAp_ChrMgmt_swc/RTE_R_ComM_PEPSPwrMod_Enum
    delegate CtAp_ChrgEgyCal.RTE_R_ComM_PODDCFCUDc_V <-> outer port CtAp_ChrMgmt_swc/RTE_R_ComM_PODDCFCUDc_V
    delegate CtAp_ChrgPreHeat.RTE_R_ComM_PODDCFCUDc_V <-> outer port CtAp_ChrMgmt_swc/RTE_R_ComM_PODDCFCUDc_V
    delegate CtAp_ChrgStat.RTE_R_ComM_SGWChrgCmd_Enum <-> outer port CtAp_ChrMgmt_swc/RTE_R_ComM_SGWChrgCmd_Enum
    delegate CtAp_ChrgPreHeat.RTE_R_ComM_SysIRVal_kOhm <-> outer port CtAp_ChrMgmt_swc/RTE_R_ComM_SysIRVal_kOhm
    delegate CtAp_ChrgSdl.RTE_R_DCChrMgmt_DcChrgnMod_Enum <-> outer port CtAp_ChrMgmt_swc/RTE_R_DCChrMgmt_DcChrgnMod_Enum
    delegate CtAp_ChrgPreHeat.RTE_R_DCChrMgmt_DcChrgnSts_Enum <-> outer port CtAp_ChrMgmt_swc/RTE_R_DCChrMgmt_DcChrgnSts_Enum
    delegate CtAp_ChrgStat.RTE_R_DCChrMgmt_DcChrgnSts_Enum <-> outer port CtAp_ChrMgmt_swc/RTE_R_DCChrMgmt_DcChrgnSts_Enum
    delegate CtAp_ChrgSdl.RTE_R_EgyMgmt_BattChrgIDcLmt_A <-> outer port CtAp_ChrMgmt_swc/RTE_R_EgyMgmt_BattChrgIDcLmt_A
    delegate CtAp_ChrgEgyCal.RTE_R_EgyMgmt_DCDCPwrCnsCalcn_Kw <-> outer port CtAp_ChrMgmt_swc/RTE_R_EgyMgmt_DCDCPwrCnsCalcn_Kw
    delegate CtAp_ChrgEgyCal.RTE_R_EgyMgmt_PackPTCPwrCnsCalcn_Kw <-> outer port CtAp_ChrMgmt_swc/RTE_R_EgyMgmt_PackPTCPwrCnsCalcn_Kw
    delegate CtAp_ChrgEgyCal.RTE_R_EgyMgmt_TCUPwrCnsCalcn_Kw <-> outer port CtAp_ChrMgmt_swc/RTE_R_EgyMgmt_TCUPwrCnsCalcn_Kw
    delegate CtAp_ChrgStat.RTE_R_ErrMgmt_ChrgCtrl_8bit <-> outer port CtAp_ChrMgmt_swc/RTE_R_ErrMgmt_ChrgCtrl_8bit
    delegate CtAp_ChrgStat.RTE_R_GearMgmt_ActGear_Enum <-> outer port CtAp_ChrMgmt_swc/RTE_R_GearMgmt_ActGear_Enum
    delegate CtAp_ChrgPreHeat.RTE_R_HvMgmt_DCDCWrkModActSts_Enum <-> outer port CtAp_ChrMgmt_swc/RTE_R_HvMgmt_DCDCWrkModActSts_Enum
    delegate CtAp_ChrgStat.RTE_R_HvMgmt_DCDCWrkModActSts_Enum <-> outer port CtAp_ChrMgmt_swc/RTE_R_HvMgmt_DCDCWrkModActSts_Enum
    delegate CtAp_ChrgStat.RTE_R_IOAbs_CC2SigUDc_mV <-> outer port CtAp_ChrMgmt_swc/RTE_R_IOAbs_CC2SigUDc_mV
    delegate CtAp_ChrgPreHeat.RTE_R_ModMgmt_HvSts_Enum <-> outer port CtAp_ChrMgmt_swc/RTE_R_ModMgmt_HvSts_Enum
    delegate CtAp_ChrgStat.RTE_R_ModMgmt_HvSts_Enum <-> outer port CtAp_ChrMgmt_swc/RTE_R_ModMgmt_HvSts_Enum
    delegate CtAp_ChrgPreHeat.RTE_R_OBCMgmt_AcChrgnSts_Enum <-> outer port CtAp_ChrMgmt_swc/RTE_R_OBCMgmt_AcChrgnSts_Enum
    delegate CtAp_ChrgStat.RTE_R_OBCMgmt_AcChrgnSts_Enum <-> outer port CtAp_ChrMgmt_swc/RTE_R_OBCMgmt_AcChrgnSts_Enum
    delegate CtAp_ChrgSdl.RTE_R_OBCMgmt_OBCOutpCpbyIDc_A <-> outer port CtAp_ChrMgmt_swc/RTE_R_OBCMgmt_OBCOutpCpbyIDc_A
    delegate CtAp_ChrgStat.RTE_R_VehMot_VehSpd_kph <-> outer port CtAp_ChrMgmt_swc/RTE_R_VehMot_VehSpd_kph
  composition sw component type CtAp_EgyMgmt_swc
    16 x provide port:
      RTE_P_EgyMgmt_BMSBattChrgIDcLmt_A: nonqueued-sender-com-spec{data-element=tec_EgyMgmt_BMSBattChrgIDcLmt_A, init-value=0}, provided-interface=IF_EgyMgmt_BMSBattChrgIDcLmt_A
      RTE_P_EgyMgmt_DCDCPwrCnsCalcn_Kw: nonqueued-sender-com-spec{data-element=tec_EgyMgmt_DCDCPwrCnsCalcn_Kw, init-value=0}, provided-interface=IF_EgyMgmt_DCDCPwrCnsCalcn_Kw
      RTE_P_EgyMgmt_DCDCPwrLmt_Kw: nonqueued-sender-com-spec{data-element=tec_EgyMgmt_DCDCPwrLmt_Kw, init-value=0}, provided-interface=IF_EgyMgmt_DCDCPwrLmt_Kw
      RTE_P_EgyMgmt_KeepWrmIDcLmt_A: nonqueued-sender-com-spec{data-element=tec_EgyMgmt_KeepWrmIDcLmt_A, init-value=0}, provided-interface=IF_EgyMgmt_KeepWrmIDcLmt_A
      RTE_P_EgyMgmt_MCULongChrgPwrLmt_Kw: nonqueued-sender-com-spec{data-element=tec_EgyMgmt_MCULongChrgPwrLmt_Kw, init-value=0}, provided-interface=IF_EgyMgmt_MCULongChrgPwrLmt_Kw
      RTE_P_EgyMgmt_MCULongDchaPwrLmt_Kw: nonqueued-sender-com-spec{data-element=tec_EgyMgmt_MCULongDchaPwrLmt_Kw, init-value=0}, provided-interface=IF_EgyMgmt_MCULongDchaPwrLmt_Kw
      RTE_P_EgyMgmt_MCUPwrCnsCalcn_Kw: nonqueued-sender-com-spec{data-element=tec_EgyMgmt_MCUPwrCnsCalcn_Kw, init-value=0}, provided-interface=IF_EgyMgmt_MCUPwrCnsCalcn_Kw
      RTE_P_EgyMgmt_MCUShoChrgPwrLmt_Kw: nonqueued-sender-com-spec{data-element=tec_EgyMgmt_MCUShoChrgPwrLmt_Kw, init-value=0}, provided-interface=IF_EgyMgmt_MCUShoChrgPwrLmt_Kw
      RTE_P_EgyMgmt_MCUShoDchaPwrLmt_Kw: nonqueued-sender-com-spec{data-element=tec_EgyMgmt_MCUShoDchaPwrLmt_Kw, init-value=0}, provided-interface=IF_EgyMgmt_MCUShoDchaPwrLmt_Kw
      RTE_P_EgyMgmt_OBCDchaPwrLmt_Kw: nonqueued-sender-com-spec{data-element=tec_EgyMgmt_OBCDchaPwrLmt_Kw, init-value=0}, provided-interface=IF_EgyMgmt_OBCDchaPwrLmt_Kw
      RTE_P_EgyMgmt_PackPTCPwrCnsCalcn_Kw: nonqueued-sender-com-spec{data-element=tec_EgyMgmt_PackPTCPwrCnsCalcn_Kw, init-value=0}, provided-interface=IF_EgyMgmt_PackPTCPwrCnsCalcn_Kw
      RTE_P_EgyMgmt_PermtPckPTC_Flg: nonqueued-sender-com-spec{data-element=tec_EgyMgmt_PermtPckPTC_Flg, init-value=0}, provided-interface=IF_EgyMgmt_PermtPckPTC_Flg
      RTE_P_EgyMgmt_PreheatIDcLmt_A: nonqueued-sender-com-spec{data-element=tec_EgyMgmt_PreheatIDcLmt_A, init-value=0}, provided-interface=IF_EgyMgmt_PreheatIDcLmt_A
      RTE_P_EgyMgmt_TCUPwrAllwd_Kw: nonqueued-sender-com-spec{data-element=tec_EgyMgmt_TCUPwrAllwd_Kw, init-value=0}, provided-interface=IF_EgyMgmt_TCUPwrAllwd_Kw
      RTE_P_EgyMgmt_TCUPwrCnsCalcn_Kw: nonqueued-sender-com-spec{data-element=tec_EgyMgmt_TCUPwrCnsCalcn_Kw, init-value=0}, provided-interface=IF_EgyMgmt_TCUPwrCnsCalcn_Kw
      RTE_P_EgyMgmt_V2LPwrCnsCalcn_Kw: nonqueued-sender-com-spec{data-element=IF_EgyMgmt_V2LPwrCnsCalcn_Kw, init-value=0}, provided-interface=IF_EgyMgmt_V2LPwrCnsCalcn_Kw
    25 x require port:
      RTE_R_ChrMgmt_ChrgSts_Enum: nonqueued-receiver-com-spec{data-element=tec_ChrMgmt_ChrgSts_Enum, filter=data-filter-type=ALWAYS, init-value=0}, required-interface=IF_ChrMgmt_ChrgSts_Enum
      RTE_R_ComM_APTCPwrCns_Kw: nonqueued-receiver-com-spec{data-element=tec_ComM_APTCPwrCns_Kw, filter=data-filter-type=ALWAYS, init-value=0}, required-interface=IF_ComM_APTCPwrCns_Kw
      RTE_R_ComM_BMSBattAllowChrgIDc_A: nonqueued-receiver-com-spec{data-element=tec_ComM_BMSBattAllowChrgIDc_A, filter=data-filter-type=ALWAYS, init-value=0}, required-interface=IF_ComM_BMSBattAllowChrgIDc_A
      RTE_R_ComM_BMSBattDchaIDc_A: nonqueued-receiver-com-spec{data-element=tec_ComM_BMSBattDchaIDc_A, filter=data-filter-type=ALWAYS, init-value=0}, required-interface=IF_ComM_BMSBattDchaIDc_A
      RTE_R_ComM_BMSBattHeatIDc_A: nonqueued-receiver-com-spec{data-element=tec_ComM_BMSBattHeatIDc_A, filter=data-filter-type=ALWAYS, init-value=0}, required-interface=IF_ComM_BMSBattHeatIDc_A
      RTE_R_ComM_BMSBattLnkUDc_V: nonqueued-receiver-com-spec{data-element=tec_ComM_BMSBattLnkUDc_V, filter=data-filter-type=ALWAYS, init-value=0}, required-interface=IF_ComM_BMSBattLnkUDc_V
      RTE_R_ComM_BMSBattLongChrgIDc_A: nonqueued-receiver-com-spec{data-element=tec_ComM_BMSBattLongChrgIDc_A, filter=data-filter-type=ALWAYS, init-value=0}, required-interface=IF_ComM_BMSBattLongChrgIDc_A
      RTE_R_ComM_BMSBattLongDchaIDc_A: nonqueued-receiver-com-spec{data-element=tec_ComM_BMSBattLongDchaIDc_A, filter=data-filter-type=ALWAYS, init-value=0}, required-interface=IF_ComM_BMSBattLongDchaIDc_A
      RTE_R_ComM_BMSBattPckUDc_V: nonqueued-receiver-com-spec{data-element=tec_ComM_BMSBattPckUDc_V, filter=data-filter-type=ALWAYS, init-value=0}, required-interface=IF_ComM_BMSBattPckUDc_V
      RTE_R_ComM_BMSBattShoChrgIDc_A: nonqueued-receiver-com-spec{data-element=tec_ComM_BMSBattShoChrgIDc_A, filter=data-filter-type=ALWAYS, init-value=0}, required-interface=IF_ComM_BMSBattShoChrgIDc_A
      RTE_R_ComM_BMSBattShoDchaIDc_A: nonqueued-receiver-com-spec{data-element=tec_ComM_BMSBattShoDchaIDc_A, filter=data-filter-type=ALWAYS, init-value=0}, required-interface=IF_ComM_BMSBattShoDchaIDc_A
      RTE_R_ComM_DCDCHvInpIDc_A: nonqueued-receiver-com-spec{data-element=tec_ComM_DCDCHvInpIDc_A, filter=data-filter-type=ALWAYS, init-value=0}, required-interface=IF_ComM_DCDCHvInpIDc_A
      RTE_R_ComM_DCDCHvInpUDc_V: nonqueued-receiver-com-spec{data-element=tec_ComM_DCDCHvInpUDc_V, filter=data-filter-type=ALWAYS, init-value=0}, required-interface=IF_ComM_DCDCHvInpUDc_V
      RTE_R_ComM_EVCOMActPwrCns_Kw: nonqueued-receiver-com-spec{data-element=tec_ComM_EVCOMActPwrCns_Kw, filter=data-filter-type=ALWAYS, init-value=0}, required-interface=IF_ComM_EVCOMActPwrCns_Kw
      RTE_R_ComM_HVCHIDc_A: nonqueued-receiver-com-spec{data-element=tec_ComM_HVCHIDc_A, filter=data-filter-type=ALWAYS, init-value=0}, required-interface=IF_ComM_HVCHIDc_A
      RTE_R_ComM_HVCHUDc_V: nonqueued-receiver-com-spec{data-element=tec_ComM_HVCHUDc_V, filter=data-filter-type=ALWAYS, init-value=0}, required-interface=IF_ComM_HVCHUDc_V
      RTE_R_ComM_MCUIDc_A: nonqueued-receiver-com-spec{data-element=tec_ComM_MCUIDc_A, filter=data-filter-type=ALWAYS, init-value=0}, required-interface=IF_ComM_MCUIDc_A
      RTE_R_ComM_MCUUDc_V: nonqueued-receiver-com-spec{data-element=tec_ComM_MCUUDc_V, filter=data-filter-type=ALWAYS, init-value=0}, required-interface=IF_ComM_MCUUDc_V
      RTE_R_ComM_OBCChrgOutpPwrAvl_Kw: nonqueued-receiver-com-spec{data-element=tec_ComM_OBCChrgOutpPwrAvl_Kw, filter=data-filter-type=ALWAYS, init-value=0}, required-interface=IF_ComM_OBCChrgOutpPwrAvl_Kw
      RTE_R_ComM_OBCOutpIDc_A: nonqueued-receiver-com-spec{data-element=tec_ComM_OBCOutpIDc_A, filter=data-filter-type=ALWAYS, init-value=0}, required-interface=IF_ComM_OBCOutpIDc_A
      RTE_R_ComM_OBCOutpUDc_V: nonqueued-receiver-com-spec{data-element=tec_ComM_OBCOutpUDc_V, filter=data-filter-type=ALWAYS, init-value=0}, required-interface=IF_ComM_OBCOutpUDc_V
      RTE_R_ComM_TMSTotPwrCns_Kw: nonqueued-receiver-com-spec{data-element=tec_ComM_TMSTotPwrCns_Kw, filter=data-filter-type=ALWAYS, init-value=0}, required-interface=IF_ComM_TMSTotPwrCns_Kw
      RTE_R_ComM_TMSTotPwrReq_Kw: nonqueued-receiver-com-spec{data-element=tec_ComM_TMSTotPwrReq_Kw, filter=data-filter-type=ALWAYS, init-value=0}, required-interface=IF_ComM_TMSTotPwrReq_Kw
      RTE_R_GearMgmt_ActGear_Enum: nonqueued-receiver-com-spec{data-element=tec_GearMgmt_ActGear_Enum, filter=data-filter-type=ALWAYS, init-value=0}, required-interface=IF_GearMgmt_ActGear_Enum
      RTE_R_ModMgmt_ActDrvMod_Enum: nonqueued-receiver-com-spec{data-element=tec_ModMgmt_ActDrvMod_Enum, filter=data-filter-type=ALWAYS, init-value=0}, required-interface=IF_ModMgmt_ActDrvMod_Enum
    component CtAp_CnsCalcn: type=CtAp_CnsCalcn
    component CtAp_PwrLim: type=CtAp_PwrLim
    connect CtAp_CnsCalcn.RTE_P_EgyMgmt_DCDCPwrCnsCalcn_Kw -> CtAp_PwrLim.RTE_R_EgyMgmt_DCDCPwrCnsCalcn_Kw
    connect CtAp_CnsCalcn.RTE_P_EgyMgmt_MCUPwrCnsCalcn_Kw -> CtAp_PwrLim.RTE_R_EgyMgmt_MCUPwrCnsCalcn_Kw
    connect CtAp_CnsCalcn.RTE_P_EgyMgmt_PackPTCPwrCnsCalcn_Kw -> CtAp_PwrLim.RTE_R_EgyMgmt_PackPTCPwrCnsCalcn_Kw
    connect CtAp_CnsCalcn.RTE_P_EgyMgmt_TCUPwrCnsCalcn_Kw -> CtAp_PwrLim.RTE_R_EgyMgmt_TCUPwrCnsCalcn_Kw
    connect CtAp_CnsCalcn.RTE_P_EgyMgmt_V2LPwrCnsCalcn_Kw -> CtAp_PwrLim.RTE_R_EgyMgmt_V2LPwrCnsCalcn_Kw
    delegate CtAp_PwrLim.RTE_P_EgyMgmt_BMSBattChrgIDcLmt_A <-> outer port CtAp_EgyMgmt_swc/RTE_P_EgyMgmt_BMSBattChrgIDcLmt_A
    delegate CtAp_CnsCalcn.RTE_P_EgyMgmt_DCDCPwrCnsCalcn_Kw <-> outer port CtAp_EgyMgmt_swc/RTE_P_EgyMgmt_DCDCPwrCnsCalcn_Kw
    delegate CtAp_PwrLim.RTE_P_EgyMgmt_DCDCPwrLmt_Kw <-> outer port CtAp_EgyMgmt_swc/RTE_P_EgyMgmt_DCDCPwrLmt_Kw
    delegate CtAp_PwrLim.RTE_P_EgyMgmt_KeepWrmIDcLmt_A <-> outer port CtAp_EgyMgmt_swc/RTE_P_EgyMgmt_KeepWrmIDcLmt_A
    delegate CtAp_PwrLim.RTE_P_EgyMgmt_MCULongChrgPwrLmt_Kw <-> outer port CtAp_EgyMgmt_swc/RTE_P_EgyMgmt_MCULongChrgPwrLmt_Kw
    delegate CtAp_PwrLim.RTE_P_EgyMgmt_MCULongDchaPwrLmt_Kw <-> outer port CtAp_EgyMgmt_swc/RTE_P_EgyMgmt_MCULongDchaPwrLmt_Kw
    delegate CtAp_CnsCalcn.RTE_P_EgyMgmt_MCUPwrCnsCalcn_Kw <-> outer port CtAp_EgyMgmt_swc/RTE_P_EgyMgmt_MCUPwrCnsCalcn_Kw
    delegate CtAp_PwrLim.RTE_P_EgyMgmt_MCUShoChrgPwrLmt_Kw <-> outer port CtAp_EgyMgmt_swc/RTE_P_EgyMgmt_MCUShoChrgPwrLmt_Kw
    delegate CtAp_PwrLim.RTE_P_EgyMgmt_MCUShoDchaPwrLmt_Kw <-> outer port CtAp_EgyMgmt_swc/RTE_P_EgyMgmt_MCUShoDchaPwrLmt_Kw
    delegate CtAp_PwrLim.RTE_P_EgyMgmt_OBCDchaPwrLmt_Kw <-> outer port CtAp_EgyMgmt_swc/RTE_P_EgyMgmt_OBCDchaPwrLmt_Kw
    delegate CtAp_CnsCalcn.RTE_P_EgyMgmt_PackPTCPwrCnsCalcn_Kw <-> outer port CtAp_EgyMgmt_swc/RTE_P_EgyMgmt_PackPTCPwrCnsCalcn_Kw
    delegate CtAp_PwrLim.RTE_P_EgyMgmt_PermtPckPTC_Flg <-> outer port CtAp_EgyMgmt_swc/RTE_P_EgyMgmt_PermtPckPTC_Flg
    delegate CtAp_PwrLim.RTE_P_EgyMgmt_PreheatIDcLmt_A <-> outer port CtAp_EgyMgmt_swc/RTE_P_EgyMgmt_PreheatIDcLmt_A
    delegate CtAp_PwrLim.RTE_P_EgyMgmt_TCUPwrAllwd_Kw <-> outer port CtAp_EgyMgmt_swc/RTE_P_EgyMgmt_TCUPwrAllwd_Kw
    delegate CtAp_CnsCalcn.RTE_P_EgyMgmt_TCUPwrCnsCalcn_Kw <-> outer port CtAp_EgyMgmt_swc/RTE_P_EgyMgmt_TCUPwrCnsCalcn_Kw
    delegate CtAp_CnsCalcn.RTE_P_EgyMgmt_V2LPwrCnsCalcn_Kw <-> outer port CtAp_EgyMgmt_swc/RTE_P_EgyMgmt_V2LPwrCnsCalcn_Kw
    delegate CtAp_PwrLim.RTE_R_ChrMgmt_ChrgSts_Enum <-> outer port CtAp_EgyMgmt_swc/RTE_R_ChrMgmt_ChrgSts_Enum
    delegate CtAp_CnsCalcn.RTE_R_ComM_APTCPwrCns_Kw <-> outer port CtAp_EgyMgmt_swc/RTE_R_ComM_APTCPwrCns_Kw
    delegate CtAp_PwrLim.RTE_R_ComM_BMSBattAllowChrgIDc_A <-> outer port CtAp_EgyMgmt_swc/RTE_R_ComM_BMSBattAllowChrgIDc_A
    delegate CtAp_PwrLim.RTE_R_ComM_BMSBattDchaIDc_A <-> outer port CtAp_EgyMgmt_swc/RTE_R_ComM_BMSBattDchaIDc_A
    delegate CtAp_CnsCalcn.RTE_R_ComM_BMSBattHeatIDc_A <-> outer port CtAp_EgyMgmt_swc/RTE_R_ComM_BMSBattHeatIDc_A
    delegate CtAp_CnsCalcn.RTE_R_ComM_BMSBattLnkUDc_V <-> outer port CtAp_EgyMgmt_swc/RTE_R_ComM_BMSBattLnkUDc_V
    delegate CtAp_PwrLim.RTE_R_ComM_BMSBattLnkUDc_V <-> outer port CtAp_EgyMgmt_swc/RTE_R_ComM_BMSBattLnkUDc_V
    delegate CtAp_PwrLim.RTE_R_ComM_BMSBattLongChrgIDc_A <-> outer port CtAp_EgyMgmt_swc/RTE_R_ComM_BMSBattLongChrgIDc_A
    delegate CtAp_PwrLim.RTE_R_ComM_BMSBattLongDchaIDc_A <-> outer port CtAp_EgyMgmt_swc/RTE_R_ComM_BMSBattLongDchaIDc_A
    delegate CtAp_PwrLim.RTE_R_ComM_BMSBattPckUDc_V <-> outer port CtAp_EgyMgmt_swc/RTE_R_ComM_BMSBattPckUDc_V
    delegate CtAp_PwrLim.RTE_R_ComM_BMSBattShoChrgIDc_A <-> outer port CtAp_EgyMgmt_swc/RTE_R_ComM_BMSBattShoChrgIDc_A
    delegate CtAp_PwrLim.RTE_R_ComM_BMSBattShoDchaIDc_A <-> outer port CtAp_EgyMgmt_swc/RTE_R_ComM_BMSBattShoDchaIDc_A
    delegate CtAp_CnsCalcn.RTE_R_ComM_DCDCHvInpIDc_A <-> outer port CtAp_EgyMgmt_swc/RTE_R_ComM_DCDCHvInpIDc_A
    delegate CtAp_CnsCalcn.RTE_R_ComM_DCDCHvInpUDc_V <-> outer port CtAp_EgyMgmt_swc/RTE_R_ComM_DCDCHvInpUDc_V
    delegate CtAp_CnsCalcn.RTE_R_ComM_EVCOMActPwrCns_Kw <-> outer port CtAp_EgyMgmt_swc/RTE_R_ComM_EVCOMActPwrCns_Kw
    delegate CtAp_CnsCalcn.RTE_R_ComM_HVCHIDc_A <-> outer port CtAp_EgyMgmt_swc/RTE_R_ComM_HVCHIDc_A
    delegate CtAp_CnsCalcn.RTE_R_ComM_HVCHUDc_V <-> outer port CtAp_EgyMgmt_swc/RTE_R_ComM_HVCHUDc_V
    delegate CtAp_CnsCalcn.RTE_R_ComM_MCUIDc_A <-> outer port CtAp_EgyMgmt_swc/RTE_R_ComM_MCUIDc_A
    delegate CtAp_CnsCalcn.RTE_R_ComM_MCUUDc_V <-> outer port CtAp_EgyMgmt_swc/RTE_R_ComM_MCUUDc_V
    delegate CtAp_PwrLim.RTE_R_ComM_OBCChrgOutpPwrAvl_Kw <-> outer port CtAp_EgyMgmt_swc/RTE_R_ComM_OBCChrgOutpPwrAvl_Kw
    delegate CtAp_CnsCalcn.RTE_R_ComM_OBCOutpIDc_A <-> outer port CtAp_EgyMgmt_swc/RTE_R_ComM_OBCOutpIDc_A
    delegate CtAp_CnsCalcn.RTE_R_ComM_OBCOutpUDc_V <-> outer port CtAp_EgyMgmt_swc/RTE_R_ComM_OBCOutpUDc_V
    delegate CtAp_CnsCalcn.RTE_R_ComM_TMSTotPwrCns_Kw <-> outer port CtAp_EgyMgmt_swc/RTE_R_ComM_TMSTotPwrCns_Kw
    delegate CtAp_PwrLim.RTE_R_ComM_TMSTotPwrReq_Kw <-> outer port CtAp_EgyMgmt_swc/RTE_R_ComM_TMSTotPwrReq_Kw
    delegate CtAp_PwrLim.RTE_R_GearMgmt_ActGear_Enum <-> outer port CtAp_EgyMgmt_swc/RTE_R_GearMgmt_ActGear_Enum
    delegate CtAp_PwrLim.RTE_R_ModMgmt_ActDrvMod_Enum <-> outer port CtAp_EgyMgmt_swc/RTE_R_ModMgmt_ActDrvMod_Enum
  composition sw component type CtAp_ErrMgmt_swc
    4 x component:
      CtAp_ComMErr: type=CtAp_ComMErr
      CtAp_DiagIf: type=CtAp_DiagIf
      CtAp_FltReactn: type=CtAp_FltReactn
      CtAp_HVSfty: type=CtAp_HVSfty
  composition sw component type CtAp_GearMgmt_swc
    23 x provide port:
      RTE_P_GearMgmt_ActGear_Enum: nonqueued-sender-com-spec{data-element=tec_GearMgmt_ActGear_Enum, init-value=0}, provided-interface=IF_GearMgmt_ActGear_Enum
      RTE_P_GearMgmt_AllowGearShift_Enum: nonqueued-sender-com-spec{data-element=tec_GearMgmt_AllowGearShift_Enum, init-value=0}, provided-interface=IF_GearMgmt_AllowGearShift_Enum
      RTE_P_GearMgmt_AllowGearShift2P_Flg: nonqueued-sender-com-spec{data-element=tec_GearMgmt_AllowGearShift2P_Flg, init-value=0}, provided-interface=IF_GearMgmt_AllowGearShift2P_Flg
      RTE_P_GearMgmt_AllowGearShiftWait_Enum: nonqueued-sender-com-spec{data-element=tec_GearMgmt_AllowGearShiftWait_Enum, init-value=0}, provided-interface=IF_GearMgmt_AllowGearShiftWait_Enum
      RTE_P_GearMgmt_AutoNReq_Flg: nonqueued-sender-com-spec{data-element=tec_GearMgmt_AutoNReq_Flg, init-value=0}, provided-interface=IF_GearMgmt_AutoNReq_Flg
      RTE_P_GearMgmt_AutoPNSts_Flg: nonqueued-sender-com-spec{data-element=tec_GearMgmt_AutoPNSts_Flg, init-value=0}, provided-interface=IF_GearMgmt_AutoPNSts_Flg
      RTE_P_GearMgmt_AutoPReq_Flg: nonqueued-sender-com-spec{data-element=tec_GearMgmt_AutoPReq_Flg, init-value=0}, provided-interface=IF_GearMgmt_AutoPReq_Flg
      RTE_P_GearMgmt_EPBPrkReq_Flg: nonqueued-sender-com-spec{data-element=tec_GearMgmt_EPBPrkReq_Flg, init-value=0}, provided-interface=IF_GearMgmt_EPBPrkReq_Flg
      RTE_P_GearMgmt_EPBPrkReqCmpl_Flg: nonqueued-sender-com-spec{data-element=tec_GearMgmt_EPBPrkReqCmpl_Flg, init-value=0}, provided-interface=IF_GearMgmt_EPBPrkReqCmpl_Flg
      RTE_P_GearMgmt_EPBPrkReqFail_Flg: nonqueued-sender-com-spec{data-element=tec_GearMgmt_EPBPrkReqFail_Flg, init-value=0}, provided-interface=IF_GearMgmt_EPBPrkReqFail_Flg
      RTE_P_GearMgmt_EPBPrkType_Enum: nonqueued-sender-com-spec{data-element=tec_GearMgmt_EPBPrkType_Enum, init-value=0}, provided-interface=IF_GearMgmt_EPBPrkType_Enum
      RTE_P_GearMgmt_EPBRelsReq_Flg: nonqueued-sender-com-spec{data-element=tec_GearMgmt_EPBRelsReq_Flg, init-value=0}, provided-interface=IF_GearMgmt_EPBRelsReq_Flg
      RTE_P_GearMgmt_EPBRelsReqCmpl_Flg: nonqueued-sender-com-spec{data-element=tec_GearMgmt_EPBRelsReqCmpl_Flg, init-value=0}, provided-interface=IF_GearMgmt_EPBRelsReqCmpl_Flg
      RTE_P_GearMgmt_EPBRelsReqFail_Flg: nonqueued-sender-com-spec{data-element=tec_GearMgmt_EPBRelsReqFail_Flg, init-value=0}, provided-interface=IF_GearMgmt_EPBRelsReqFail_Flg
      RTE_P_GearMgmt_InPlugDetd_Flg: nonqueued-sender-com-spec{data-element=tec_GearMgmt_InPlugDetd_Flg, init-value=0}, provided-interface=IF_GearMgmt_InPlugDetd_Flg
      RTE_P_GearMgmt_InvldGearSel_Enum: nonqueued-sender-com-spec{data-element=tec_GearMgmt_InvldGearSel_Enum, init-value=0}, provided-interface=IF_GearMgmt_InvldGearSel_Enum
      RTE_P_GearMgmt_NotP2PReq_Flg: nonqueued-sender-com-spec{data-element=tec_GearMgmt_NotP2PReq_Flg, init-value=0}, provided-interface=IF_GearMgmt_NotP2PReq_Flg
      RTE_P_GearMgmt_P2NReq_Flg: nonqueued-sender-com-spec{data-element=tec_GearMgmt_P2NReq_Flg, init-value=0}, provided-interface=IF_GearMgmt_P2NReq_Flg
      RTE_P_GearMgmt_TarGear_Enum: nonqueued-sender-com-spec{data-element=tec_GearMgmt_TarGear_Enum, init-value=0}, provided-interface=IF_GearMgmt_TarGear_Enum
      RTE_P_GearMgmt_TarGearPInhbTq_Flg: nonqueued-sender-com-spec{data-element=tec_GearMgmt_TarGearPInhbTq_Flg, init-value=0}, provided-interface=IF_GearMgmt_TarGearPInhbTq_Flg
      RTE_P_GearMgmt_TarGearShift_Enum: nonqueued-sender-com-spec{data-element=tec_GearMgmt_TarGearShift_Enum, init-value=0}, provided-interface=IF_GearMgmt_TarGearShift_Enum
      RTE_P_GearMgmt_WakeUpEPBReq_Flg: nonqueued-sender-com-spec{data-element=tec_GearMgmt_WakeUpEPBReq_Flg, init-value=0}, provided-interface=IF_GearMgmt_WakeUpEPBReq_Flg
      RTE_P_GearMgmt_WakeUpFinish_Flg: nonqueued-sender-com-spec{data-element=tec_GearMgmt_WakeUpFinish_Flg, init-value=0}, provided-interface=IF_GearMgmt_WakeUpFinish_Flg
    19 x require port:
      RTE_R_ChassisMgmt_AccrPedlPosn_pct: nonqueued-receiver-com-spec{data-element=tec_ChassisMgmt_AccrPedlPosn_pct, filter=data-filter-type=ALWAYS, init-value=0}, required-interface=IF_ChassisMgmt_AccrPedlPosn_pct
      RTE_R_ChassisMgmt_AccrPedlVld_Flg: nonqueued-receiver-com-spec{data-element=tec_ChassisMgmt_AccrPedlVld_Flg, filter=data-filter-type=ALWAYS, init-value=0}, required-interface=IF_ChassisMgmt_AccrPedlVld_Flg
      RTE_R_ChassisMgmt_BrkSts_Flg: nonqueued-receiver-com-spec{data-element=tec_ChassisMgmt_BrkSts_Flg, filter=data-filter-type=ALWAYS, init-value=0}, required-interface=IF_ChassisMgmt_BrkSts_Flg
      RTE_R_ChassisMgmt_BrkStsVld_Flg: nonqueued-receiver-com-spec{data-element=tec_ChassisMgmt_BrkStsVld_Flg, filter=data-filter-type=ALWAYS, init-value=0}, required-interface=IF_ChassisMgmt_BrkStsVld_Flg
      RTE_R_ChrMgmt_ChrgSts_Enum: nonqueued-receiver-com-spec{data-element=tec_ChrMgmt_ChrgSts_Enum, filter=data-filter-type=ALWAYS, init-value=0}, required-interface=IF_ChrMgmt_ChrgSts_Enum
      RTE_R_ComM_ACUDrvSeatBltSts_Flg: nonqueued-receiver-com-spec{data-element=tec_ComM_ACUDrvSeatBltSts_Flg, filter=data-filter-type=ALWAYS, init-value=0}, required-interface=IF_ComM_ACUDrvSeatBltSts_Flg
      RTE_R_ComM_ACUDrvSeatBltStsVld_Flg: nonqueued-receiver-com-spec{data-element=tec_ComM_ACUDrvSeatBltStsVld_Flg, filter=data-filter-type=ALWAYS, init-value=0}, required-interface=IF_ComM_ACUDrvSeatBltStsVld_Flg
      RTE_R_ComM_ADCUDMSDrvExist_Flg: nonqueued-receiver-com-spec{data-element=tec_ComM_ADCUDMSDrvrExist_Flg, filter=data-filter-type=ALWAYS, init-value=0}, required-interface=IF_ComM_ADCUDMSDrvExist_Flg
      RTE_R_ComM_DCMFLDoorSts_Flg: nonqueued-receiver-com-spec{data-element=tec_ComM_DCMFLDoorSts_Flg, filter=data-filter-type=ALWAYS, init-value=0}, required-interface=IF_ComM_DCMFLDoorSts_Flg
      RTE_R_ComM_EPBWrkSts_Enum: nonqueued-receiver-com-spec{data-element=tec_ComM_EPBWrkSts_Enum, filter=data-filter-type=ALWAYS, init-value=0}, required-interface=IF_ComM_EPBWrkSts_Enum
      RTE_R_ComM_GearPBtn_Enum: nonqueued-receiver-com-spec{data-element=tec_ComM_GearPBtn_Enum, filter=data-filter-type=ALWAYS, init-value=0}, required-interface=IF_ComM_GearPBtn_Enum
      RTE_R_ComM_GearPBtnFltSts_Flg: nonqueued-receiver-com-spec{data-element=tec_ComM_GearPBtnFltSts_Flg, filter=data-filter-type=ALWAYS, init-value=0}, required-interface=IF_ComM_GearPBtnFltSts_Flg
      RTE_R_ComM_GearRNDBtn_Enum: nonqueued-receiver-com-spec{data-element=tec_ComM_GearRNDBtn_Enum, filter=data-filter-type=ALWAYS, init-value=0}, required-interface=IF_ComM_GearRNDBtn_Enum
      RTE_R_ComM_GearRNDBtnFltSts_Flg: nonqueued-receiver-com-spec{data-element=tec_ComM_GearRNDBtnFltSts_Flg, filter=data-filter-type=ALWAYS, init-value=0}, required-interface=IF_ComM_GearRNDBtnFltSts_Flg
      RTE_R_ComM_IBSTarGearReq_Enum: nonqueued-receiver-com-spec{data-element=tec_ComM_IBSTarGearReq_Enum, filter=data-filter-type=ALWAYS, init-value=0}, required-interface=IF_ComM_IBSTarGearReq_Enum
      RTE_R_ComM_IVIGearReq_Enum: nonqueued-receiver-com-spec{data-element=tec_ComM_IVIGearReq_Enum, filter=data-filter-type=ALWAYS, init-value=0}, required-interface=IF_ComM_IVIGearReq_Enum
      RTE_R_ComM_PEPSPwrMod_Enum: nonqueued-receiver-com-spec{data-element=tec_ComM_PEPSPwrMod_Enum, filter=data-filter-type=ALWAYS, init-value=0}, required-interface=IF_ComM_PEPSPwrMod_Enum
      RTE_R_ModMgmt_HvSts_Enum: nonqueued-receiver-com-spec{data-element=tec_ModMgmt_HvSts_Enum, filter=data-filter-type=ALWAYS, init-value=0}, required-interface=IF_ModMgmt_HvSts_Enum
      RTE_R_VehMot_VehSpd_kph: nonqueued-receiver-com-spec{data-element=tec_VehMot_VehSpd_kph, filter=data-filter-type=ALWAYS, init-value=0}, required-interface=IF_VehMot_VehSpd_kph
    5 x component:
      CtAp_AutoSftGear: type=CtAp_AutoSftGear
      CtAp_EPBLink: type=CtAp_EPBLink
      CtAp_GearCoor: type=CtAp_GearCoor
      CtAp_GearDiag: type=CtAp_GearDiag
      CtAp_ManSftGear: type=CtAp_ManSftGear
    connect CtAp_AutoSftGear.RTE_P_GearMgmt_AutoPNSts_Flg -> CtAp_EPBLink.RTE_R_GearMgmt_AutoPNSts_Flg
    connect CtAp_AutoSftGear.RTE_P_GearMgmt_AutoPReq_Flg -> CtAp_EPBLink.RTE_R_GearMgmt_AutoPReq_Flg
    connect CtAp_AutoSftGear.RTE_P_GearMgmt_NotP2PReq_Flg -> CtAp_EPBLink.RTE_R_GearMgmt_NotP2PReq_Flg
    connect CtAp_AutoSftGear.RTE_P_GearMgmt_AutoNReq_Flg -> CtAp_GearCoor.RTE_R_GearMgmt_AutoNReq_Flg
    connect CtAp_AutoSftGear.RTE_P_GearMgmt_P2NReq_Flg -> CtAp_GearCoor.RTE_R_GearMgmt_P2NReq_Flg
    connect CtAp_AutoSftGear.RTE_P_GearMgmt_AutoPReq_Flg -> CtAp_GearDiag.RTE_R_GearMgmt_AutoPReq_Flg
    connect CtAp_EPBLink.RTE_P_GearMgmt_AllowGearShift2P_Flg -> CtAp_GearCoor.RTE_R_GearMgmt_AllowGearShift2P_Flg
    connect CtAp_EPBLink.RTE_P_GearMgmt_EPBPrkReqFail_Flg -> CtAp_GearDiag.RTE_R_GearMgmt_EPBPrkReqFail_Flg
    connect CtAp_EPBLink.RTE_P_GearMgmt_EPBPrkType_Enum -> CtAp_GearDiag.RTE_R_GearMgmt_EPBPrkType_Enum
    connect CtAp_EPBLink.RTE_P_GearMgmt_EPBRelsReqFail_Flg -> CtAp_GearDiag.RTE_R_GearMgmt_EPBRelsReqFail_Flg
    connect CtAp_EPBLink.RTE_P_GearMgmt_EPBPrkReqCmpl_Flg -> CtAp_ManSftGear.RTE_R_GearMgmt_EPBPrkReqCmpl_Flg
    connect CtAp_EPBLink.RTE_P_GearMgmt_EPBRelsReqCmpl_Flg -> CtAp_ManSftGear.RTE_R_GearMgmt_EPBRelsReqCmpl_Flg
    connect CtAp_GearCoor.RTE_P_GearMgmt_ActGear_Enum -> CtAp_AutoSftGear.RTE_R_GearMgmt_ActGear_Enum
    connect CtAp_GearCoor.RTE_P_GearMgmt_WakeUpEPBReq_Flg -> CtAp_EPBLink.RTE_R_GearMgmt_WakeUpEPBReq_Flg
    connect CtAp_GearCoor.RTE_P_GearMgmt_ActGear_Enum -> CtAp_ManSftGear.RTE_R_GearMgmt_ActGear_Enum
    connect CtAp_GearCoor.RTE_P_GearMgmt_WakeUpFinish_Flg -> CtAp_ManSftGear.RTE_R_GearMgmt_WakeUpFinish_Flg
    connect CtAp_ManSftGear.RTE_P_GearMgmt_InPlugDetd_Flg -> CtAp_AutoSftGear.RTE_R_GearMgmt_InPlugDetd_Flg
    connect CtAp_ManSftGear.RTE_P_GearMgmt_AllowGearShiftWait_Enum -> CtAp_EPBLink.RTE_R_GearMgmt_AllowGearShiftWait_Enum
    connect CtAp_ManSftGear.RTE_P_GearMgmt_AllowGearShift_Enum -> CtAp_GearCoor.RTE_R_GearMgmt_AllowGearShift_Enum
    connect CtAp_ManSftGear.RTE_P_GearMgmt_InPlugDetd_Flg -> CtAp_GearDiag.RTE_R_GearMgmt_InPlugDetd_Flg
    connect CtAp_ManSftGear.RTE_P_GearMgmt_TarGearShift_Enum -> CtAp_GearDiag.RTE_R_GearMgmt_TarGearShift_Enum
    delegate CtAp_GearCoor.RTE_P_GearMgmt_ActGear_Enum <-> outer port CtAp_GearMgmt_swc/RTE_P_GearMgmt_ActGear_Enum
    delegate CtAp_ManSftGear.RTE_P_GearMgmt_AllowGearShift_Enum <-> outer port CtAp_GearMgmt_swc/RTE_P_GearMgmt_AllowGearShift_Enum
    delegate CtAp_EPBLink.RTE_P_GearMgmt_AllowGearShift2P_Flg <-> outer port CtAp_GearMgmt_swc/RTE_P_GearMgmt_AllowGearShift2P_Flg
    delegate CtAp_ManSftGear.RTE_P_GearMgmt_AllowGearShiftWait_Enum <-> outer port CtAp_GearMgmt_swc/RTE_P_GearMgmt_AllowGearShiftWait_Enum
    delegate CtAp_AutoSftGear.RTE_P_GearMgmt_AutoNReq_Flg <-> outer port CtAp_GearMgmt_swc/RTE_P_GearMgmt_AutoNReq_Flg
    delegate CtAp_AutoSftGear.RTE_P_GearMgmt_AutoPNSts_Flg <-> outer port CtAp_GearMgmt_swc/RTE_P_GearMgmt_AutoPNSts_Flg
    delegate CtAp_AutoSftGear.RTE_P_GearMgmt_AutoPReq_Flg <-> outer port CtAp_GearMgmt_swc/RTE_P_GearMgmt_AutoPReq_Flg
    delegate CtAp_EPBLink.RTE_P_GearMgmt_EPBPrkReq_Flg <-> outer port CtAp_GearMgmt_swc/RTE_P_GearMgmt_EPBPrkReq_Flg
    delegate CtAp_EPBLink.RTE_P_GearMgmt_EPBPrkReqCmpl_Flg <-> outer port CtAp_GearMgmt_swc/RTE_P_GearMgmt_EPBPrkReqCmpl_Flg
    delegate CtAp_EPBLink.RTE_P_GearMgmt_EPBPrkReqFail_Flg <-> outer port CtAp_GearMgmt_swc/RTE_P_GearMgmt_EPBPrkReqFail_Flg
    delegate CtAp_EPBLink.RTE_P_GearMgmt_EPBPrkType_Enum <-> outer port CtAp_GearMgmt_swc/RTE_P_GearMgmt_EPBPrkType_Enum
    delegate CtAp_EPBLink.RTE_P_GearMgmt_EPBRelsReq_Flg <-> outer port CtAp_GearMgmt_swc/RTE_P_GearMgmt_EPBRelsReq_Flg
    delegate CtAp_EPBLink.RTE_P_GearMgmt_EPBRelsReqCmpl_Flg <-> outer port CtAp_GearMgmt_swc/RTE_P_GearMgmt_EPBRelsReqCmpl_Flg
    delegate CtAp_EPBLink.RTE_P_GearMgmt_EPBRelsReqFail_Flg <-> outer port CtAp_GearMgmt_swc/RTE_P_GearMgmt_EPBRelsReqFail_Flg
    delegate CtAp_ManSftGear.RTE_P_GearMgmt_InPlugDetd_Flg <-> outer port CtAp_GearMgmt_swc/RTE_P_GearMgmt_InPlugDetd_Flg
    delegate CtAp_GearDiag.RTE_P_GearMgmt_InvldGearSel_Enum <-> outer port CtAp_GearMgmt_swc/RTE_P_GearMgmt_InvldGearSel_Enum
    delegate CtAp_AutoSftGear.RTE_P_GearMgmt_NotP2PReq_Flg <-> outer port CtAp_GearMgmt_swc/RTE_P_GearMgmt_NotP2PReq_Flg
    delegate CtAp_AutoSftGear.RTE_P_GearMgmt_P2NReq_Flg <-> outer port CtAp_GearMgmt_swc/RTE_P_GearMgmt_P2NReq_Flg
    delegate CtAp_ManSftGear.RTE_P_GearMgmt_TarGear_Enum <-> outer port CtAp_GearMgmt_swc/RTE_P_GearMgmt_TarGear_Enum
    delegate CtAp_GearCoor.RTE_P_GearMgmt_TarGearPInhbTq_Flg <-> outer port CtAp_GearMgmt_swc/RTE_P_GearMgmt_TarGearPInhbTq_Flg
    delegate CtAp_ManSftGear.RTE_P_GearMgmt_TarGearShift_Enum <-> outer port CtAp_GearMgmt_swc/RTE_P_GearMgmt_TarGearShift_Enum
    delegate CtAp_GearCoor.RTE_P_GearMgmt_WakeUpEPBReq_Flg <-> outer port CtAp_GearMgmt_swc/RTE_P_GearMgmt_WakeUpEPBReq_Flg
    delegate CtAp_GearCoor.RTE_P_GearMgmt_WakeUpFinish_Flg <-> outer port CtAp_GearMgmt_swc/RTE_P_GearMgmt_WakeUpFinish_Flg
    delegate CtAp_GearDiag.RTE_R_ChassisMgmt_AccrPedlPosn_pct <-> outer port CtAp_GearMgmt_swc/RTE_R_ChassisMgmt_AccrPedlPosn_pct
    delegate CtAp_ManSftGear.RTE_R_ChassisMgmt_AccrPedlPosn_pct <-> outer port CtAp_GearMgmt_swc/RTE_R_ChassisMgmt_AccrPedlPosn_pct
    delegate CtAp_GearDiag.RTE_R_ChassisMgmt_AccrPedlVld_Flg <-> outer port CtAp_GearMgmt_swc/RTE_R_ChassisMgmt_AccrPedlVld_Flg
    delegate CtAp_ManSftGear.RTE_R_ChassisMgmt_AccrPedlVld_Flg <-> outer port CtAp_GearMgmt_swc/RTE_R_ChassisMgmt_AccrPedlVld_Flg
    delegate CtAp_GearDiag.RTE_R_ChassisMgmt_BrkSts_Flg <-> outer port CtAp_GearMgmt_swc/RTE_R_ChassisMgmt_BrkSts_Flg
    delegate CtAp_ManSftGear.RTE_R_ChassisMgmt_BrkSts_Flg <-> outer port CtAp_GearMgmt_swc/RTE_R_ChassisMgmt_BrkSts_Flg
    delegate CtAp_GearDiag.RTE_R_ChassisMgmt_BrkStsVld_Flg <-> outer port CtAp_GearMgmt_swc/RTE_R_ChassisMgmt_BrkStsVld_Flg
    delegate CtAp_ManSftGear.RTE_R_ChassisMgmt_BrkStsVld_Flg <-> outer port CtAp_GearMgmt_swc/RTE_R_ChassisMgmt_BrkStsVld_Flg
    delegate CtAp_ManSftGear.RTE_R_ChrMgmt_ChrgSts_Enum <-> outer port CtAp_GearMgmt_swc/RTE_R_ChrMgmt_ChrgSts_Enum
    delegate CtAp_AutoSftGear.RTE_R_ComM_ACUDrvSeatBltSts_Flg <-> outer port CtAp_GearMgmt_swc/RTE_R_ComM_ACUDrvSeatBltSts_Flg
    delegate CtAp_AutoSftGear.RTE_R_ComM_ACUDrvSeatBltStsVld_Flg <-> outer port CtAp_GearMgmt_swc/RTE_R_ComM_ACUDrvSeatBltStsVld_Flg
    delegate CtAp_AutoSftGear.RTE_R_ComM_ADCUDMSDrvExist_Flg <-> outer port CtAp_GearMgmt_swc/RTE_R_ComM_ADCUDMSDrvExist_Flg
    delegate CtAp_AutoSftGear.RTE_R_ComM_DCMFLDoorSts_Flg <-> outer port CtAp_GearMgmt_swc/RTE_R_ComM_DCMFLDoorSts_Flg
    delegate CtAp_AutoSftGear.RTE_R_ComM_EPBWrkSts_Enum <-> outer port CtAp_GearMgmt_swc/RTE_R_ComM_EPBWrkSts_Enum
    delegate CtAp_EPBLink.RTE_R_ComM_EPBWrkSts_Enum <-> outer port CtAp_GearMgmt_swc/RTE_R_ComM_EPBWrkSts_Enum
    delegate CtAp_GearCoor.RTE_R_ComM_EPBWrkSts_Enum <-> outer port CtAp_GearMgmt_swc/RTE_R_ComM_EPBWrkSts_Enum
    delegate CtAp_GearDiag.RTE_R_ComM_EPBWrkSts_Enum <-> outer port CtAp_GearMgmt_swc/RTE_R_ComM_EPBWrkSts_Enum
    delegate CtAp_ManSftGear.RTE_R_ComM_GearPBtn_Enum <-> outer port CtAp_GearMgmt_swc/RTE_R_ComM_GearPBtn_Enum
    delegate CtAp_GearDiag.RTE_R_ComM_GearPBtnFltSts_Flg <-> outer port CtAp_GearMgmt_swc/RTE_R_ComM_GearPBtnFltSts_Flg
    delegate CtAp_ManSftGear.RTE_R_ComM_GearPBtnFltSts_Flg <-> outer port CtAp_GearMgmt_swc/RTE_R_ComM_GearPBtnFltSts_Flg
    delegate CtAp_ManSftGear.RTE_R_ComM_GearRNDBtn_Enum <-> outer port CtAp_GearMgmt_swc/RTE_R_ComM_GearRNDBtn_Enum
    delegate CtAp_GearDiag.RTE_R_ComM_GearRNDBtnFltSts_Flg <-> outer port CtAp_GearMgmt_swc/RTE_R_ComM_GearRNDBtnFltSts_Flg
    delegate CtAp_ManSftGear.RTE_R_ComM_GearRNDBtnFltSts_Flg <-> outer port CtAp_GearMgmt_swc/RTE_R_ComM_GearRNDBtnFltSts_Flg
    delegate CtAp_ManSftGear.RTE_R_ComM_IBSTarGearReq_Enum <-> outer port CtAp_GearMgmt_swc/RTE_R_ComM_IBSTarGearReq_Enum
    delegate CtAp_ManSftGear.RTE_R_ComM_IVIGearReq_Enum <-> outer port CtAp_GearMgmt_swc/RTE_R_ComM_IVIGearReq_Enum
    delegate CtAp_AutoSftGear.RTE_R_ComM_PEPSPwrMod_Enum <-> outer port CtAp_GearMgmt_swc/RTE_R_ComM_PEPSPwrMod_Enum
    delegate CtAp_AutoSftGear.RTE_R_ModMgmt_HvSts_Enum <-> outer port CtAp_GearMgmt_swc/RTE_R_ModMgmt_HvSts_Enum
    delegate CtAp_GearDiag.RTE_R_ModMgmt_HvSts_Enum <-> outer port CtAp_GearMgmt_swc/RTE_R_ModMgmt_HvSts_Enum
    delegate CtAp_ManSftGear.RTE_R_ModMgmt_HvSts_Enum <-> outer port CtAp_GearMgmt_swc/RTE_R_ModMgmt_HvSts_Enum
    delegate CtAp_AutoSftGear.RTE_R_VehMot_VehSpd_kph <-> outer port CtAp_GearMgmt_swc/RTE_R_VehMot_VehSpd_kph
    delegate CtAp_GearCoor.RTE_R_VehMot_VehSpd_kph <-> outer port CtAp_GearMgmt_swc/RTE_R_VehMot_VehSpd_kph
    delegate CtAp_GearDiag.RTE_R_VehMot_VehSpd_kph <-> outer port CtAp_GearMgmt_swc/RTE_R_VehMot_VehSpd_kph
    delegate CtAp_ManSftGear.RTE_R_VehMot_VehSpd_kph <-> outer port CtAp_GearMgmt_swc/RTE_R_VehMot_VehSpd_kph
    delegate CtAp_ManSftGear.RTE_R_ComM_EPBWrkSts_Enum <-> outer port CtAp_GearMgmt_swc/RTE_R_ComM_EPBWrkSts_Enum
